VERSION ""

NS_ :

BS_:

BU_: ATCM_DMSM GSM GWM _delete SCCM OCS GENERIC TSTR RCM

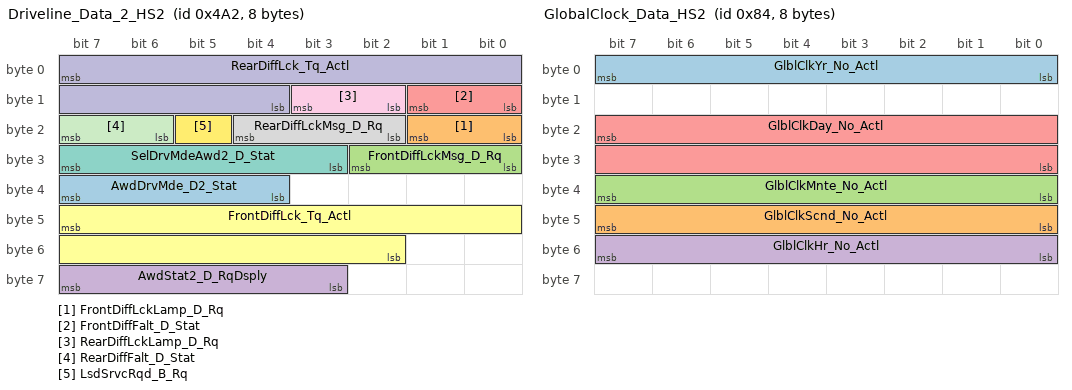
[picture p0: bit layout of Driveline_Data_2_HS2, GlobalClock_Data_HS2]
BO_ 1186 Driveline_Data_2_HS2: 8 GWM
 SG_ AwdDrvMde_D2_Stat : 39|4@0+ (1,0) [0|15] "SED" Vector__XXX
 SG_ FrontDiffLckLamp_D_Rq : 17|2@0+ (1,0) [0|3] "SED"  ATCM_DMSM
 SG_ FrontDiffLckMsg_D_Rq : 26|3@0+ (1,0) [0|7] "SED"  GENERIC
 SG_ AwdStat2_D_RqDsply : 63|5@0+ (1,0) [0|31] "SED"  GENERIC
 SG_ FrontDiffFalt_D_Stat : 9|2@0+ (1,0) [0|3] "SED"  GENERIC
 SG_ FrontDiffLck_Tq_Actl : 47|14@0+ (1,0) [0|16381] "Nm"  GENERIC
 SG_ SelDrvMdeAwd2_D_Stat : 31|5@0+ (1,0) [0|31] "SED"  GENERIC
 SG_ RearDiffLckMsg_D_Rq : 20|3@0+ (1,0) [0|7] "SED" Vector__XXX
 SG_ RearDiffLckLamp_D_Rq : 11|2@0+ (1,0) [0|3] "SED"  ATCM_DMSM
 SG_ RearDiffLck_Tq_Actl : 7|12@0+ (1,0) [0|4093] "Nm" Vector__XXX
 SG_ RearDiffFalt_D_Stat : 23|2@0+ (1,0) [0|3] "SED" Vector__XXX
 SG_ LsdSrvcRqd_B_Rq : 21|1@0+ (1,0) [0|1] "SED" Vector__XXX

BO_ 132 GlobalClock_Data_HS2: 8 GWM
 SG_ GlblClkYr_No_Actl : 7|8@0+ (1,2000) [2000|2255] "year" Vector__XXX
 SG_ GlblClkScnd_No_Actl : 47|8@0+ (1,0) [0|255] "second" Vector__XXX
 SG_ GlblClkMnte_No_Actl : 39|8@0+ (1,0) [0|255] "minute" Vector__XXX
 SG_ GlblClkHr_No_Actl : 55|8@0+ (1,0) [0|255] "hour" Vector__XXX
 SG_ GlblClkDay_No_Actl : 23|16@0+ (1,0) [0|65535] "julian day" Vector__XXX

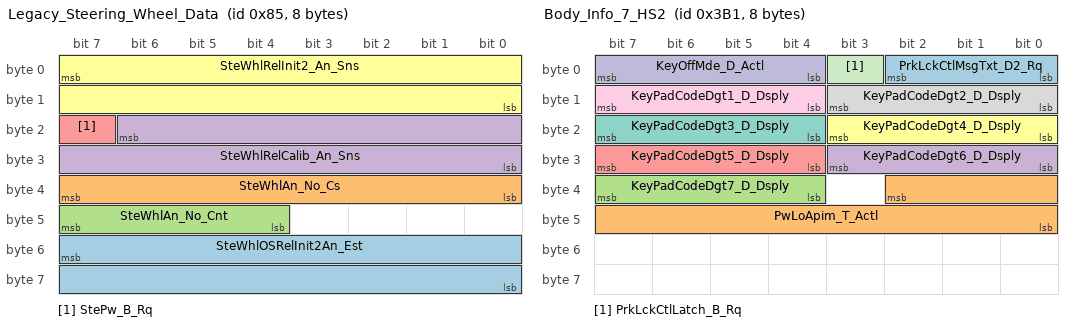
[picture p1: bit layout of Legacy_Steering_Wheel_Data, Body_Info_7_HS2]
BO_ 133 Legacy_Steering_Wheel_Data: 8 GENERIC
 SG_ SteWhlOSRelInit2An_Est : 55|16@0+ (0.1,-3200) [-3200|3353.3] "deg"  GENERIC
 SG_ SteWhlAn_No_Cs : 39|8@0+ (1,0) [0|255] "Unitless"  GENERIC
 SG_ SteWhlAn_No_Cnt : 47|4@0+ (1,0) [0|15] "Counts"  GENERIC
 SG_ SteWhlRelCalib_An_Sns : 22|15@0+ (0.1,-1600) [-1600|1676.5] "deg"  GENERIC
 SG_ StePw_B_Rq : 23|1@0+ (1,0) [0|1] "SED"  GENERIC
 SG_ SteWhlRelInit2_An_Sns : 7|16@0+ (0.1,-3200) [-3200|3353.3] "degrees"  GENERIC

BO_ 945 Body_Info_7_HS2: 8 GWM
 SG_ PrkLckCtlMsgTxt_D2_Rq : 2|3@0+ (1,0) [0|7] "SED"  GENERIC
 SG_ PwLoApim_T_Actl : 34|11@0+ (1,0) [0|2047] "minute"  GENERIC
 SG_ KeyPadCodeDgt7_D_Dsply : 39|4@0+ (1,0) [0|15] "SED"  GENERIC
 SG_ KeyPadCodeDgt6_D_Dsply : 27|4@0+ (1,0) [0|15] "SED"  GENERIC
 SG_ KeyPadCodeDgt5_D_Dsply : 31|4@0+ (1,0) [0|15] "SED"  GENERIC
 SG_ KeyPadCodeDgt4_D_Dsply : 19|4@0+ (1,0) [0|15] "SED"  GENERIC
 SG_ KeyPadCodeDgt3_D_Dsply : 23|4@0+ (1,0) [0|15] "SED"  GENERIC
 SG_ KeyPadCodeDgt2_D_Dsply : 11|4@0+ (1,0) [0|15] "SED"  GENERIC
 SG_ KeyPadCodeDgt1_D_Dsply : 15|4@0+ (1,0) [0|15] "SED"  GENERIC
 SG_ KeyOffMde_D_Actl : 7|4@0+ (1,0) [0|15] "SED" Vector__XXX
 SG_ PrkLckCtlLatch_B_Rq : 3|1@0+ (1,0) [0|1] "SED"  GENERIC

BO_ 1080 GatewayData3_HS2: 8 GWM
 SG_ TrlrAidMde_D_Rq_UB : 56|1@0+ (1,0) [0|1] "SED" Vector__XXX
 SG_ TrlrAidMde_D_Rq : 58|2@0+ (1,0) [0|3] "SED" Vector__XXX
 SG_ Rba_D_Rq_UB : 59|1@0+ (1,0) [0|1] "SED" Vector__XXX
 SG_ Rba_D_Rq : 61|2@0+ (1,0) [0|3] "SED" Vector__XXX
 SG_ TrailCtlSwtch_B_Stat_UB : 62|1@0+ (1,0) [0|1] "SED" Vector__XXX
 SG_ TrailCtlSwtch_B_Stat : 63|1@0+ (1,0) [0|1] "SED" Vector__XXX
 SG_ TrailCtlPt_B_Falt_UB : 0|1@0+ (1,0) [0|1] "SED" Vector__XXX
 SG_ TrailCtlPt_B_Falt : 49|2@0+ (1,0) [0|3] "SED" Vector__XXX
 SG_ AutoTowActv_B_Stat_UB : 50|1@0+ (1,0) [0|1] "SED" Vector__XXX
 SG_ AutoTowActv_B_Stat : 51|1@0+ (1,0) [0|1] "SED" Vector__XXX
 SG_ DrLatchLckRr_B_Stat_UB : 44|1@0+ (1,0) [0|1] "SED" Vector__XXX
 SG_ DrLatchLckRl_B_Stat_UB : 46|1@0+ (1,0) [0|1] "SED" Vector__XXX
 SG_ DrLatchLckFr_B_Stat_UB : 32|1@0+ (1,0) [0|1] "SED"  GSM
 SG_ DrLatchLckFl_B_Stat_UB : 34|1@0+ (1,0) [0|1] "SED"  GSM
 SG_ DrLatchRr_B_Falt_UB : 40|1@0+ (1,0) [0|1] "SED" Vector__XXX
 SG_ DrLatchRl_B_Falt_UB : 42|1@0+ (1,0) [0|1] "SED" Vector__XXX
 SG_ DrLatchFr_B_Falt_UB : 36|1@0+ (1,0) [0|1] "SED"  GSM
 SG_ DrLatchFl_B_Falt_UB : 38|1@0+ (1,0) [0|1] "SED"  GSM
 SG_ DrLatchCntRr_No_Actl_UB : 24|1@0+ (1,0) [0|1] "SED" Vector__XXX
 SG_ DrLatchCntRl_No_Actl_UB : 25|1@0+ (1,0) [0|1] "SED" Vector__XXX
 SG_ DrLatchCntFr_No_Actl_UB : 26|1@0+ (1,0) [0|1] "SED"  GSM
 SG_ DrLatchCntFl_No_Actl_UB : 27|1@0+ (1,0) [0|1] "SED"  GSM
 SG_ DrLatchRr_B_Falt : 41|1@0+ (1,0) [0|1] "SED" Vector__XXX
 SG_ DrLatchRl_B_Falt : 43|1@0+ (1,0) [0|1] "SED" Vector__XXX
 SG_ DrLatchLckRr_B_Stat : 45|1@0+ (1,0) [0|1] "SED" Vector__XXX
 SG_ DrLatchLckRl_B_Stat : 47|1@0+ (1,0) [0|1] "SED" Vector__XXX
 SG_ DrLatchLckFr_B_Stat : 33|1@0+ (1,0) [0|1] "SED"  GSM
 SG_ DrLatchLckFl_B_Stat : 35|1@0+ (1,0) [0|1] "SED"  GSM
 SG_ DrLatchFr_B_Falt : 37|1@0+ (1,0) [0|1] "SED"  GSM
 SG_ DrLatchFl_B_Falt : 39|1@0+ (1,0) [0|1] "SED"  GSM
 SG_ DrLatchCntRr_No_Actl : 31|4@0+ (1,0) [0|15] "unitless" Vector__XXX
 SG_ DrLatchCntRl_No_Actl : 19|4@0+ (1,0) [0|15] "unitless" Vector__XXX
 SG_ DrLatchCntFr_No_Actl : 23|4@0+ (1,0) [0|15] "unitless"  GSM
 SG_ DrLatchCntFl_No_Actl : 55|4@0+ (1,0) [0|15] "unitless"  GSM
 SG_ TurnLghtSwtch_D_Stat2_UB : 1|1@0+ (1,0) [0|1] "SED" Vector__XXX
 SG_ TurnLghtSwtch_D_Stat2 : 3|2@0+ (1,0) [0|3] "SED" Vector__XXX
 SG_ CabnAmb_Te_Actl_UB : 4|1@0+ (1,0) [0|1] "SED"  SCCM
 SG_ CabnAmb_Te_Actl : 15|8@0+ (0.5,-57) [-57|70] "degreesC"  SCCM
 SG_ HeadLghtHiPrmsn_D_Stat_UB : 5|1@0+ (1,0) [0|1] "SED"  SCCM
 SG_ HeadLghtHiPrmsn_D_Stat : 7|2@0+ (1,0) [0|3] "SED"  SCCM

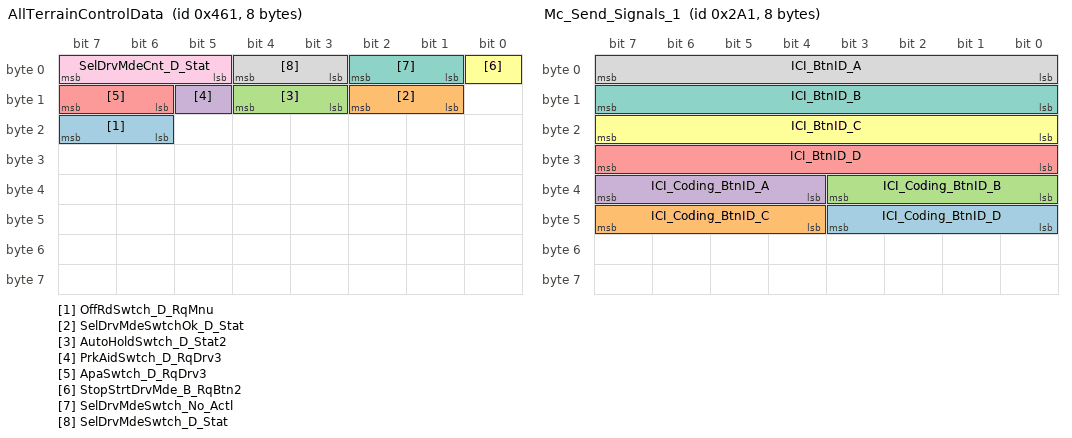
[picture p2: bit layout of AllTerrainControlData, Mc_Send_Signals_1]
BO_ 1121 AllTerrainControlData: 8 ATCM_DMSM
 SG_ OffRdSwtch_D_RqMnu : 23|2@0+ (1,0) [0|3] "SED"  GWM
 SG_ SelDrvMdeSwtchOk_D_Stat : 10|2@0+ (1,0) [0|3] "SED"  GWM
 SG_ AutoHoldSwtch_D_Stat2 : 12|2@0+ (1,0) [0|3] "SED"  GWM
 SG_ PrkAidSwtch_D_RqDrv3 : 13|1@0+ (1,0) [0|1] "SED"  GWM
 SG_ ApaSwtch_D_RqDrv3 : 15|2@0+ (1,0) [0|3] "SED"  GWM
 SG_ StopStrtDrvMde_B_RqBtn2 : 0|1@0+ (1,0) [0|1] "SED"  GWM
 SG_ SelDrvMdeSwtch_No_Actl : 2|2@0+ (1,0) [0|3] "unitless"  GWM
 SG_ SelDrvMdeSwtch_D_Stat : 4|2@0+ (1,0) [0|3] "SED"  GWM
 SG_ SelDrvMdeCnt_D_Stat : 7|3@0+ (1,0) [0|7] "Counts"  GWM

BO_ 673 Mc_Send_Signals_1: 8 SCCM
 SG_ ICI_Coding_BtnID_D : 43|4@0+ (1,0) [0|15] "SED"  GWM
 SG_ ICI_Coding_BtnID_C : 47|4@0+ (1,0) [0|15] "SED"  GWM
 SG_ ICI_Coding_BtnID_B : 35|4@0+ (1,0) [0|15] "SED"  GWM
 SG_ ICI_Coding_BtnID_A : 39|4@0+ (1,0) [0|15] "SED"  GWM
 SG_ ICI_BtnID_D : 31|8@0+ (1,0) [0|255] "unitless"  GWM
 SG_ ICI_BtnID_C : 23|8@0+ (1,0) [0|255] "unitless"  GWM
 SG_ ICI_BtnID_B : 15|8@0+ (1,0) [0|255] "unitless"  GWM
 SG_ ICI_BtnID_A : 7|8@0+ (1,0) [0|255] "unitless"  GWM

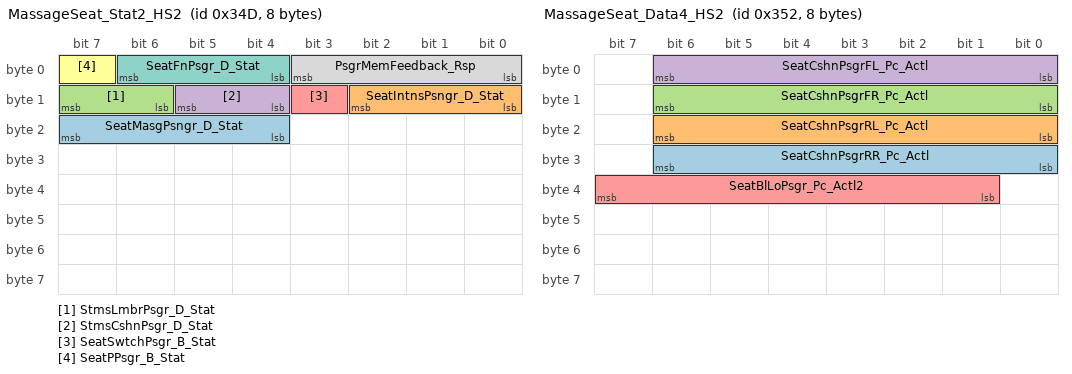
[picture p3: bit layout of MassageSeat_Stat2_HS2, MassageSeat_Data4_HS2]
BO_ 845 MassageSeat_Stat2_HS2: 8 GWM
 SG_ SeatMasgPsngr_D_Stat : 23|4@0+ (1,0) [0|15] "SED"  GENERIC
 SG_ SeatIntnsPsngr_D_Stat : 10|3@0+ (1,0) [0|7] "SED"  GENERIC
 SG_ StmsLmbrPsgr_D_Stat : 15|2@0+ (1,0) [0|3] "SED"  OCS
 SG_ StmsCshnPsgr_D_Stat : 13|2@0+ (1,0) [0|3] "SED"  OCS
 SG_ SeatSwtchPsgr_B_Stat : 11|1@0+ (1,0) [0|1] "SED"  OCS
 SG_ SeatPPsgr_B_Stat : 7|1@0+ (1,0) [0|1] "SED"  OCS
 SG_ SeatFnPsgr_D_Stat : 6|3@0+ (1,0) [0|7] "SED"  OCS
 SG_ PsgrMemFeedback_Rsp : 3|4@0+ (1,0) [0|15] "SED"  GENERIC

BO_ 850 MassageSeat_Data4_HS2: 8 GWM
 SG_ SeatCshnPsgrRR_Pc_Actl : 30|7@0+ (1,0) [0|126] "Percent"  OCS
 SG_ SeatCshnPsgrRL_Pc_Actl : 22|7@0+ (1,0) [0|126] "Percent"  OCS
 SG_ SeatCshnPsgrFR_Pc_Actl : 14|7@0+ (1,0) [0|126] "Percent"  OCS
 SG_ SeatCshnPsgrFL_Pc_Actl : 6|7@0+ (1,0) [0|126] "Percent"  OCS
 SG_ SeatBlLoPsgr_Pc_Actl2 : 39|7@0+ (1,0) [0|126] "Percent"  OCS

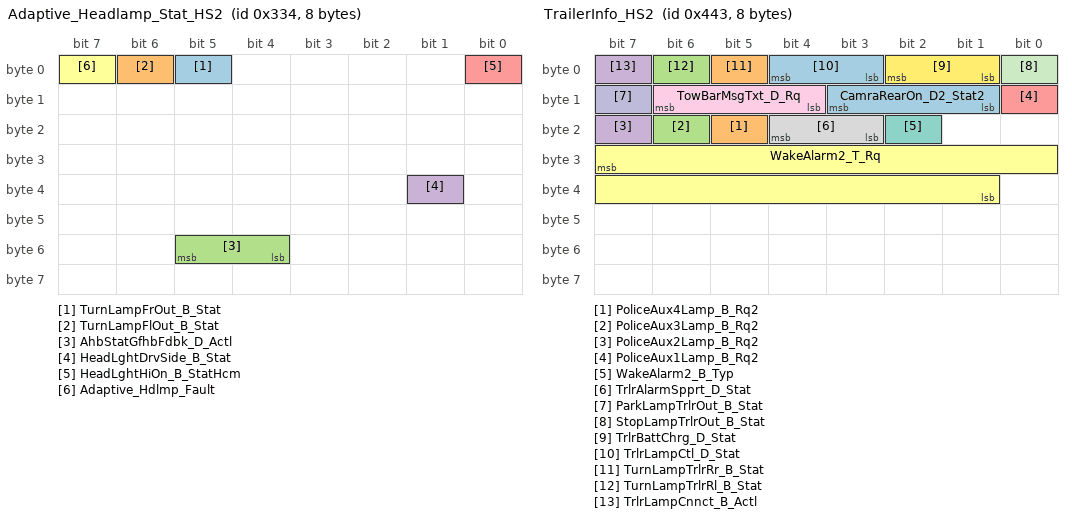
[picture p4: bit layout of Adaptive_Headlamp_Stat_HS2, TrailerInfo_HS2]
BO_ 820 Adaptive_Headlamp_Stat_HS2: 8 GWM
 SG_ TurnLampFrOut_B_Stat : 5|1@0+ (1,0) [0|1] "SED" Vector__XXX
 SG_ TurnLampFlOut_B_Stat : 6|1@0+ (1,0) [0|1] "SED" Vector__XXX
 SG_ AhbStatGfhbFdbk_D_Actl : 53|2@0+ (1,0) [0|3] "SED"  SCCM
 SG_ HeadLghtDrvSide_B_Stat : 33|1@0+ (1,0) [0|1] "SED" Vector__XXX
 SG_ HeadLghtHiOn_B_StatHcm : 0|1@0+ (1,0) [0|1] "SED"  GENERIC
 SG_ Adaptive_Hdlmp_Fault : 7|1@0+ (1,0) [0|1] "SED"  GENERIC

BO_ 935 Side_Detect_R_Stat_HS2: 8 GWM
 SG_ SodInnrRight_D_Stat : 20|2@0+ (1,0) [0|3] "SED"  GENERIC
 SG_ RbaCtaRight_D_Stat : 55|3@0+ (1,0) [0|7] "SED" Vector__XXX
 SG_ LcwaRight_D_Stat : 52|3@0+ (1,0) [0|7] "SED" Vector__XXX
 SG_ LcwaDetctRight2_B_Stat : 40|1@0+ (1,0) [0|1] "SED" Vector__XXX
 SG_ LcwaDetctRight1_B_Stat : 41|1@0+ (1,0) [0|1] "SED" Vector__XXX
 SG_ CtaInnrRight_D_Stat : 27|2@0+ (1,0) [0|3] "SED"  GENERIC
 SG_ CtaAlrtRight2_D_Stat : 30|3@0+ (1,0) [0|7] "SED"  GENERIC
 SG_ BttRight_D_Stat : 45|3@0+ (1,0) [0|7] "SED"  GENERIC
 SG_ BttRight_D_RqDrv : 47|2@0+ (1,0) [0|3] "SED"  GENERIC
 SG_ CtaBrkRightMsgTxt_B_Rq : 42|1@0+ (1,0) [0|1] "SED"  GENERIC
 SG_ CtaRightBrkEnbl_B_Rq : 31|1@0+ (1,0) [0|1] "SED" Vector__XXX
 SG_ Side_Detect_R_Illum : 39|8@0+ (1,0) [0|255] "Percent"  GENERIC
 SG_ CtaSnsRight_D_Stat : 25|2@0+ (1,0) [0|3] "SED"  GENERIC
 SG_ CtaAlrtRight_D_Stat : 8|1@0+ (1,0) [0|1] "SED"  GENERIC
 SG_ CtaRight_D_Stat : 18|3@0+ (1,0) [0|7] "SED" Vector__XXX
 SG_ SodRight_D_Stat : 15|3@0+ (1,0) [0|7] "SED"  GENERIC
 SG_ SodSnsRight_D_Stat : 12|2@0+ (1,0) [0|3] "SED" Vector__XXX
 SG_ SodAlrtRight_D_Stat : 10|2@0+ (1,0) [0|3] "SED"  GENERIC
 SG_ SodDetctRight_D_Stat : 23|3@0+ (1,0) [0|7] "SED" Vector__XXX
 SG_ SodWarnRight_Prd_Rq : 6|7@0+ (1,0) [0|127] "millisecond"  GENERIC
 SG_ CtaRightBrkDecel_B_Rq : 7|1@0+ (1,0) [0|1] "SED" Vector__XXX

BO_ 934 Side_Detect_L_Stat_HS2: 8 GWM
 SG_ SodInnrLeft_D_Stat : 20|2@0+ (1,0) [0|3] "SED"  GENERIC
 SG_ RbaCtaLeft_D_Stat : 55|3@0+ (1,0) [0|7] "SED" Vector__XXX
 SG_ LcwaLeft_D_Stat : 52|3@0+ (1,0) [0|7] "SED" Vector__XXX
 SG_ LcwaDetctLeft2_B_Stat : 40|1@0+ (1,0) [0|1] "SED" Vector__XXX
 SG_ LcwaDetctLeft1_B_Stat : 41|1@0+ (1,0) [0|1] "SED" Vector__XXX
 SG_ CtaInnrLeft_D_Stat : 27|2@0+ (1,0) [0|3] "SED"  GENERIC
 SG_ CtaAlrtLeft2_D_Stat : 30|3@0+ (1,0) [0|7] "SED"  GENERIC
 SG_ BttLeft_D_Stat : 45|3@0+ (1,0) [0|7] "SED"  GENERIC
 SG_ BttLeft_D_RqDrv : 47|2@0+ (1,0) [0|3] "SED"  GENERIC
 SG_ CtaBrkLeftMsgTxt_B_Rq : 42|1@0+ (1,0) [0|1] "SED"  GENERIC
 SG_ CtaLeftBrkDecel_B_Rq : 7|1@0+ (1,0) [0|1] "SED" Vector__XXX
 SG_ CtaLeftBrkEnbl_B_Rq : 31|1@0+ (1,0) [0|1] "SED" Vector__XXX
 SG_ Side_Detect_L_Illum : 39|8@0+ (1,0) [0|255] "Percent"  GENERIC
 SG_ CtaSnsLeft_D_Stat : 25|2@0+ (1,0) [0|3] "SED"  GENERIC
 SG_ SodDetctLeft_D_Stat : 23|3@0+ (1,0) [0|7] "SED" Vector__XXX
 SG_ CtaLeft_D_Stat : 18|3@0+ (1,0) [0|7] "SED" Vector__XXX
 SG_ CtaAlrtLeft_D_Stat : 8|1@0+ (1,0) [0|1] "SED"  GENERIC
 SG_ SodLeft_D_Stat : 15|3@0+ (1,0) [0|7] "SED"  GENERIC
 SG_ SodSnsLeft_D_Stat : 12|2@0+ (1,0) [0|3] "SED" Vector__XXX
 SG_ SodAlrtLeft_D_Stat : 10|2@0+ (1,0) [0|3] "SED"  GENERIC
 SG_ SodWarnLeft_Prd_Rq : 6|7@0+ (1,0) [0|127] "millisecond"  GENERIC

BO_ 1073 BodyEngGateway_2_HS2: 8 GWM
 SG_ CamraFrntBttn_D_Stat : 48|1@0+ (1,0) [0|1] "SED" Vector__XXX
 SG_ CamraFrntBttn_D_Stat_UB : 60|1@0+ (1,0) [0|1] "SED" Vector__XXX
 SG_ BrkDrvMde_D_Rq_UB : 49|1@0+ (1,0) [0|1] "SED" Vector__XXX
 SG_ BrkDrvMde_D_Rq : 63|3@0+ (1,0) [0|7] "SED" Vector__XXX
 SG_ SteEffort_D_Rq : 52|3@0+ (1,0) [0|7] "SED" Vector__XXX
 SG_ SteEffort_D_Rq_UB : 40|1@0+ (1,0) [0|1] "SED" Vector__XXX
 SG_ AutoHoldSwtch_D_Stat_UB : 57|1@0+ (1,0) [0|1] "SED" Vector__XXX
 SG_ AutoHoldSwtch_D_Stat : 59|2@0+ (1,0) [0|3] "SED" Vector__XXX
 SG_ HMI_HMIMode_St_UB : 41|1@0+ (1,0) [0|1] "SED"  SCCM
 SG_ HMI_HMIMode_St : 55|3@0+ (1,0) [0|7] "SED"  SCCM
 SG_ Veh_Lock_Requestor_UB : 47|1@0+ (1,0) [0|1] "SED"  GSM
 SG_ Veh_Lock_EvNum_UB : 32|1@0+ (1,0) [0|1] "SED"  GSM
 SG_ Veh_Lock_Sub_Id_UB : 33|1@0+ (1,0) [0|1] "SED" Vector__XXX
 SG_ Tire_Press_System_Stat_UB : 34|1@0+ (1,0) [0|1] "SED" Vector__XXX
 SG_ Veh_Lock_Status_UB : 8|1@0+ (1,0) [0|1] "SED"  GSM
 SG_ Veh_Lock_Sub_Id : 19|4@0+ (1,0) [0|15] "SED" Vector__XXX
 SG_ Veh_Lock_Status : 10|2@0+ (1,0) [0|3] "SED"  GSM
 SG_ Veh_Lock_Requestor : 39|5@0+ (1,0) [0|31] "SED"  GSM
 SG_ Veh_Lock_EvNum : 31|8@0+ (1,0) [0|255] "unitless"  GSM
 SG_ Tire_Press_System_Stat : 23|4@0+ (1,0) [0|15] "SED" Vector__XXX
 SG_ DISPLAY_SPEED_OFFSET_UB : 0|1@0+ (1,0) [0|1] "SED" Vector__XXX
 SG_ DISPLAY_SPEED_OFFSET : 3|3@0+ (0.5,0) [0|3.5] "kph" Vector__XXX
 SG_ DISPLAY_SPEED_SCALING_UB : 11|1@0+ (1,0) [0|1] "SED" Vector__XXX
 SG_ DISPLAY_SPEED_SCALING : 15|4@0+ (0.5,100) [100|107.5] "%" Vector__XXX
 SG_ Foh_D_Stat : 7|3@0+ (1,0) [0|7] "SED"  SCCM
 SG_ Foh_D_Stat_UB : 4|1@0+ (1,0) [0|1] "SED"  SCCM
 SG_ SteWhlHeat_D_Rq_UB : 42|1@0+ (1,0) [0|1] "SED"  SCCM
 SG_ SteWhlHeat_D_Rq : 46|4@0+ (1,0) [0|15] "SED"  SCCM

BO_ 1091 TrailerInfo_HS2: 8 GWM
 SG_ CamraRearOn_D2_Stat2 : 11|3@0+ (1,0) [0|7] "SED"  GENERIC
 SG_ PoliceAux4Lamp_B_Rq2 : 21|1@0+ (1,0) [0|1] "SED"  GENERIC
 SG_ PoliceAux3Lamp_B_Rq2 : 22|1@0+ (1,0) [0|1] "SED"  GENERIC
 SG_ PoliceAux2Lamp_B_Rq2 : 23|1@0+ (1,0) [0|1] "SED"  GENERIC
 SG_ PoliceAux1Lamp_B_Rq2 : 8|1@0+ (1,0) [0|1] "SED"  GENERIC
 SG_ WakeAlarm2_T_Rq : 31|15@0+ (1,0) [0|32767] "minute"  GENERIC
 SG_ WakeAlarm2_B_Typ : 18|1@0+ (1,0) [0|1] "SED"  GENERIC
 SG_ TrlrAlarmSpprt_D_Stat : 20|2@0+ (1,0) [0|3] "SED"  GENERIC
 SG_ TowBarMsgTxt_D_Rq : 14|3@0+ (1,0) [0|7] "SED"  GENERIC
 SG_ ParkLampTrlrOut_B_Stat : 15|1@0+ (1,0) [0|1] "SED"  GENERIC
 SG_ StopLampTrlrOut_B_Stat : 0|1@0+ (1,0) [0|1] "SED"  GENERIC
 SG_ TrlrBattChrg_D_Stat : 2|2@0+ (1,0) [0|3] "SED"  GENERIC
 SG_ TrlrLampCtl_D_Stat : 4|2@0+ (1,0) [0|3] "SED"  GENERIC
 SG_ TurnLampTrlrRr_B_Stat : 5|1@0+ (1,0) [0|1] "SED"  GENERIC
 SG_ TurnLampTrlrRl_B_Stat : 6|1@0+ (1,0) [0|1] "SED"  GENERIC
 SG_ TrlrLampCnnct_B_Actl : 7|1@0+ (1,0) [0|1] "SED" Vector__XXX

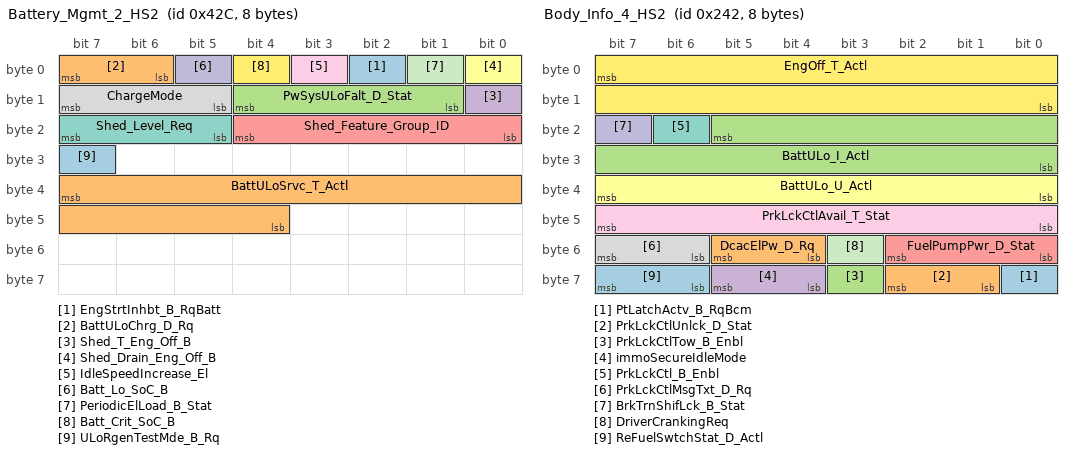
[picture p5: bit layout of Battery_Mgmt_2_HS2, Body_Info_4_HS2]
BO_ 1068 Battery_Mgmt_2_HS2: 8 GWM
 SG_ EngStrtInhbt_B_RqBatt : 2|1@0+ (1,0) [0|1] "SED"  GENERIC
 SG_ BattULoChrg_D_Rq : 7|2@0+ (1,0) [0|3] "SED"  GENERIC
 SG_ PwSysULoFalt_D_Stat : 12|4@0+ (1,0) [0|15] "SED" Vector__XXX
 SG_ Shed_T_Eng_Off_B : 8|1@0+ (1,0) [0|1] "SED" Vector__XXX
 SG_ Shed_Feature_Group_ID : 20|5@0+ (1,0) [0|31] "SED" Vector__XXX
 SG_ Shed_Drain_Eng_Off_B : 0|1@0+ (1,0) [0|1] "SED" Vector__XXX
 SG_ Shed_Level_Req : 23|3@0+ (1,0) [0|7] "SED"  GSM,SCCM
 SG_ ChargeMode : 15|3@0+ (1,0) [0|7] "SED"  GENERIC
 SG_ IdleSpeedIncrease_El : 3|1@0+ (1,0) [0|1] "SED"  GENERIC
 SG_ Batt_Lo_SoC_B : 5|1@0+ (1,0) [0|1] "SED"  GENERIC
 SG_ PeriodicElLoad_B_Stat : 1|1@0+ (1,0) [0|1] "SED"  GENERIC
 SG_ Batt_Crit_SoC_B : 4|1@0+ (1,0) [0|1] "SED"  GSM
 SG_ ULoRgenTestMde_B_Rq : 31|1@0+ (1,0) [0|1] "SED"  GENERIC
 SG_ BattULoSrvc_T_Actl : 39|12@0+ (1,0) [0|4095] "days"  GENERIC

BO_ 611 Driveline_Data_1_HS2: 8 GWM
 SG_ AwdTerrMdeChng_D_Rdy : 58|3@0+ (1,0) [0|7] "SED" Vector__XXX
 SG_ AwdTerrMde_D_Actl : 50|3@0+ (1,0) [0|7] "SED" Vector__XXX
 SG_ AwdSys_D_Stat : 27|2@0+ (1,0) [0|3] "SED"  GENERIC
 SG_ SelDrvMdeAwd_D_Stat : 33|2@0+ (1,0) [0|3] "SED"  GENERIC
 SG_ AwdStat_D_RqDsply : 63|5@0+ (1,0) [0|31] "SED"  GSM
 SG_ AwdLck_D_Stat : 31|4@0+ (1,0) [0|15] "SED"  GENERIC
 SG_ AwdSrvcRqd_B_Rq : 0|1@0+ (1,0) [0|1] "SED"  RCM
 SG_ AwdDrvMde_D_Stat : 38|3@0+ (1,0) [0|7] "SED"  GENERIC
 SG_ NtrlTowAvail_B_Stat : 4|1@0+ (1,0) [0|1] "SED"  GENERIC
 SG_ AwdLck_Tq_Rq : 15|12@0+ (1,0) [0|4093] "Nm"  GENERIC
 SG_ TrnAout_Tq_RqMx : 47|13@0+ (1,-1250) [-1250|6941] "Nm"  GENERIC
 SG_ AwdOffRoadMode_D_Stats : 25|2@0+ (1,0) [0|3] "SED" Vector__XXX
 SG_ AwdLoLamp_D_RqDsply : 35|2@0+ (1,0) [0|3] "SED"  ATCM_DMSM
 SG_ AwdHiLamp_D_RqDsply : 19|2@0+ (1,0) [0|3] "SED"  ATCM_DMSM
 SG_ AwdAutoLamp_D_RqDsply : 17|2@0+ (1,0) [0|3] "SED"  ATCM_DMSM
 SG_ Awd2wdLamp_D_RqDsply : 2|2@0+ (1,0) [0|3] "SED"  ATCM_DMSM
 SG_ AwdRnge_D_Actl : 7|3@0+ (1,0) [0|7] "SED" Vector__XXX

BO_ 395 HeadUpDisplayReq_HS2: 8 GWM
 SG_ SelDrvMdeCnfm_D_Stat : 35|2@0+ (1,0) [0|3] "SED"  GENERIC
 SG_ HudShifPoint_N_Rq : 29|6@0+ (100,2000) [2000|8300] "rpm" Vector__XXX
 SG_ HudMde_D_Rq : 38|3@0+ (1,0) [0|7] "SED" Vector__XXX
 SG_ HudLedMde_D_Rq : 31|2@0+ (1,0) [0|3] "SED" Vector__XXX
 SG_ HudLedIntns_Pc_Rq : 22|7@0+ (1,0) [0|127] "percent" Vector__XXX
 SG_ HudLed9On_B_Rq : 15|1@0+ (1,0) [0|1] "SED" Vector__XXX
 SG_ HudLed8On_B_Rq : 0|1@0+ (1,0) [0|1] "SED" Vector__XXX
 SG_ HudLed7On_B_Rq : 1|1@0+ (1,0) [0|1] "SED" Vector__XXX
 SG_ HudLed6On_B_Rq : 2|1@0+ (1,0) [0|1] "SED" Vector__XXX
 SG_ HudLed5On_B_Rq : 3|1@0+ (1,0) [0|1] "SED" Vector__XXX
 SG_ HudLed4On_B_Rq : 4|1@0+ (1,0) [0|1] "SED" Vector__XXX
 SG_ HudLed3On_B_Rq : 5|1@0+ (1,0) [0|1] "SED" Vector__XXX
 SG_ HudLed2On_B_Rq : 6|1@0+ (1,0) [0|1] "SED" Vector__XXX
 SG_ HudLed1On_B_Rq : 7|1@0+ (1,0) [0|1] "SED" Vector__XXX
 SG_ HudLed18On_B_Rq : 39|1@0+ (1,0) [0|1] "SED" Vector__XXX
 SG_ HudLed17On_B_Rq : 23|1@0+ (1,0) [0|1] "SED" Vector__XXX
 SG_ HudLed16On_B_Rq : 8|1@0+ (1,0) [0|1] "SED" Vector__XXX
 SG_ HudLed15On_B_Rq : 9|1@0+ (1,0) [0|1] "SED" Vector__XXX
 SG_ HudLed14On_B_Rq : 10|1@0+ (1,0) [0|1] "SED" Vector__XXX
 SG_ HudLed13On_B_Rq : 11|1@0+ (1,0) [0|1] "SED" Vector__XXX
 SG_ HudLed12On_B_Rq : 12|1@0+ (1,0) [0|1] "SED" Vector__XXX
 SG_ HudLed11On_B_Rq : 13|1@0+ (1,0) [0|1] "SED" Vector__XXX
 SG_ HudLed10On_B_Rq : 14|1@0+ (1,0) [0|1] "SED" Vector__XXX

BO_ 578 Body_Info_4_HS2: 8 GWM
 SG_ PtLatchActv_B_RqBcm : 56|1@0+ (1,0) [0|1] "SED"  GENERIC
 SG_ PrkLckCtlUnlck_D_Stat : 58|2@0+ (1,0) [0|3] "SED"  GENERIC
 SG_ PrkLckCtlTow_B_Enbl : 59|1@0+ (1,0) [0|1] "SED"  GENERIC
 SG_ immoSecureIdleMode : 61|2@0+ (1,0) [0|3] "SED"  GSM
 SG_ FuelPumpPwr_D_Stat : 50|3@0+ (1,0) [0|7] "SED"  GENERIC
 SG_ BattULo_U_Actl : 39|8@0+ (0.0625,0) [0|15.875] "volt" Vector__XXX
 SG_ PrkLckCtl_B_Enbl : 22|1@0+ (1,0) [0|1] "SED"  GSM
 SG_ PrkLckCtlMsgTxt_D_Rq : 55|2@0+ (1,0) [0|3] "SED"  GENERIC
 SG_ PrkLckCtlAvail_T_Stat : 47|8@0+ (1,0) [0|255] "second"  GENERIC
 SG_ BrkTrnShifLck_B_Stat : 23|1@0+ (1,0) [0|1] "SED"  GSM
 SG_ DriverCrankingReq : 51|1@0+ (1,0) [0|1] "SED"  GSM
 SG_ EngOff_T_Actl : 7|16@0+ (1,0) [0|65534] "second^0.5" Vector__XXX
 SG_ ReFuelSwtchStat_D_Actl : 63|2@0+ (1,0) [0|3] "SED"  GENERIC
 SG_ DcacElPw_D_Rq : 53|2@0+ (1,0) [0|3] "SED"  GENERIC
 SG_ BattULo_I_Actl : 21|14@0+ (0.0625,-512) [-512|511.875] "ampere"  GENERIC

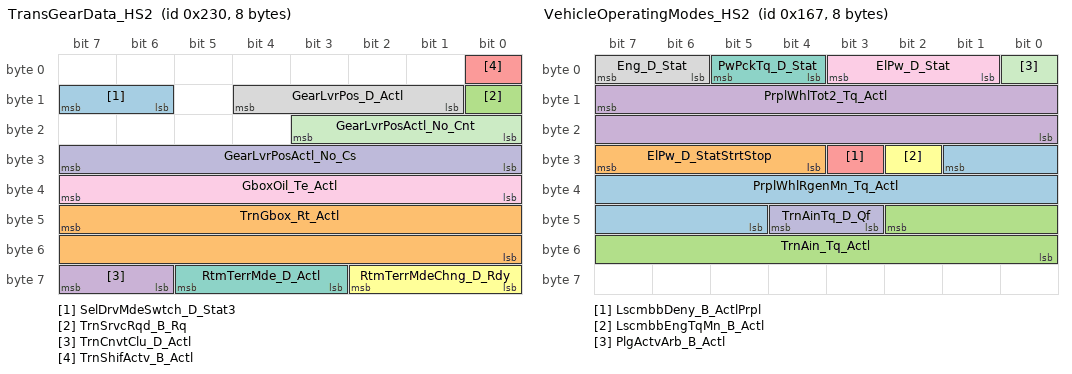
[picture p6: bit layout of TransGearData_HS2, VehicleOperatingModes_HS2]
BO_ 560 TransGearData_HS2: 8 GWM
 SG_ SelDrvMdeSwtch_D_Stat3 : 15|2@0+ (1,0) [0|3] "SED" Vector__XXX
 SG_ TrnGbox_Rt_Actl : 47|16@0+ (0.001,0) [0|65.533] "Unitless" Vector__XXX
 SG_ TrnSrvcRqd_B_Rq : 8|1@0+ (1,0) [0|1] "SED"  RCM
 SG_ TrnCnvtClu_D_Actl : 63|2@0+ (1,0) [0|3] "SED" Vector__XXX
 SG_ TrnShifActv_B_Actl : 0|1@0+ (1,0) [0|1] "SED" Vector__XXX
 SG_ RtmTerrMdeChng_D_Rdy : 58|3@0+ (1,0) [0|7] "SED" Vector__XXX
 SG_ RtmTerrMde_D_Actl : 61|3@0+ (1,0) [0|7] "SED" Vector__XXX
 SG_ GearLvrPos_D_Actl : 12|4@0+ (1,0) [0|15] "SED"  SCCM,RCM,GSM
 SG_ GboxOil_Te_Actl : 39|8@0+ (1,-60) [-60|193] "degC"  GENERIC
 SG_ GearLvrPosActl_No_Cs : 31|8@0+ (1,0) [0|255] "Unitless"  GENERIC
 SG_ GearLvrPosActl_No_Cnt : 19|4@0+ (1,0) [0|15] "Unitless"  GENERIC

BO_ 359 VehicleOperatingModes_HS2: 8 GWM
 SG_ PrplWhlRgenMn_Tq_Actl : 25|13@0+ (4,-16380) [-16380|16380] "Nm" Vector__XXX
 SG_ ElPw_D_StatStrtStop : 31|4@0+ (1,0) [0|15] "SED"  GSM,SCCM
 SG_ TrnAin_Tq_Actl : 42|11@0+ (1,-500) [-500|1547] "Nm" Vector__XXX
 SG_ PrplWhlTot2_Tq_Actl : 15|16@0+ (4,-131072) [-131072|131060] "Nm"  RCM
 SG_ LscmbbDeny_B_ActlPrpl : 27|1@0+ (1,0) [0|1] "SED" Vector__XXX
 SG_ LscmbbEngTqMn_B_Actl : 26|1@0+ (1,0) [0|1] "SED" Vector__XXX
 SG_ PwPckTq_D_Stat : 5|2@0+ (1,0) [0|3] "SED"  SCCM,OCS,GSM
 SG_ Eng_D_Stat : 7|2@0+ (1,0) [0|3] "SED" Vector__XXX
 SG_ ElPw_D_Stat : 3|3@0+ (1,0) [0|7] "SED"  GSM,OCS,SCCM
 SG_ TrnAinTq_D_Qf : 44|2@0+ (1,0) [0|3] "SED" Vector__XXX
 SG_ PlgActvArb_B_Actl : 0|1@0+ (1,0) [0|1] "SED"  GENERIC

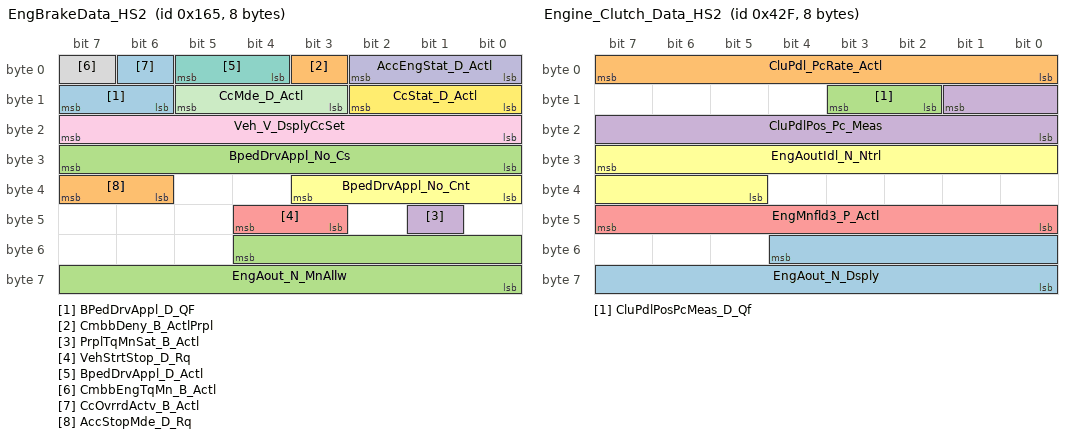
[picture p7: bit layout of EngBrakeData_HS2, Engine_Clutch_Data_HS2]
BO_ 357 EngBrakeData_HS2: 8 GWM
 SG_ BPedDrvAppl_D_QF : 15|2@0+ (1,0) [0|3] "SED"  OCS,GSM,RCM
 SG_ CmbbDeny_B_ActlPrpl : 3|1@0+ (1,0) [0|1] "SED" Vector__XXX
 SG_ BpedDrvAppl_No_Cs : 31|8@0+ (1,0) [0|255] "Unitless"  GENERIC
 SG_ PrplTqMnSat_B_Actl : 41|1@0+ (1,0) [0|1] "SED" Vector__XXX
 SG_ VehStrtStop_D_Rq : 44|2@0+ (1,0) [0|3] "SED"  GENERIC
 SG_ BpedDrvAppl_No_Cnt : 35|4@0+ (1,0) [0|15] "Unitless"  GENERIC
 SG_ BpedDrvAppl_D_Actl : 5|2@0+ (1,0) [0|3] "SED"  OCS,GSM,RCM
 SG_ CmbbEngTqMn_B_Actl : 7|1@0+ (1,0) [0|1] "SED"  GENERIC
 SG_ Veh_V_DsplyCcSet : 23|8@0+ (1,0) [0|253] "Unitless"  GENERIC
 SG_ AccEngStat_D_Actl : 2|3@0+ (1,0) [0|7] "SED" Vector__XXX
 SG_ CcMde_D_Actl : 13|3@0+ (1,0) [0|7] "SED" Vector__XXX
 SG_ CcStat_D_Actl : 10|3@0+ (1,0) [0|7] "SED"  OCS,RCM
 SG_ CcOvrrdActv_B_Actl : 6|1@0+ (1,0) [0|1] "SED"  RCM
 SG_ AccStopMde_D_Rq : 39|2@0+ (1,0) [0|3] "SED" Vector__XXX
 SG_ EngAout_N_MnAllw : 52|13@0+ (2,0) [0|16382] "rpm"  GENERIC

BO_ 390 ACCDATA_HS2: 8 GWM
 SG_ AccAutoResum_D_Rq : 7|2@0+ (1,0) [0|3] "SED" Vector__XXX
 SG_ AccBrkPulse_B_Rq : 36|1@0+ (1,0) [0|1] "SED" Vector__XXX
 SG_ AccBrkTot_A_Rq : 4|13@0+ (0.0039,-20) [-20|11.9449] "m/s^2" Vector__XXX
 SG_ AccPrpl_A_Pred : 17|10@0+ (0.01,-5) [-5|5.23] "m/s^2" Vector__XXX
 SG_ AccVeh_V_Trg : 32|9@0+ (0.5,0) [0|255.5] "kph" Vector__XXX
 SG_ AccBrkPrkEl_B_Rq : 38|1@0+ (1,0) [0|1] "SED" Vector__XXX
 SG_ Cmbb_B_Enbl : 50|1@0+ (1,0) [0|1] "SED"  RCM
 SG_ CmbbOvrrd_B_RqDrv : 51|1@0+ (1,0) [0|1] "SED"  RCM
 SG_ CmbbDeny_B_Actl : 37|1@0+ (1,0) [0|1] "SED"  RCM
 SG_ CmbbEngTqMn_B_Rq : 52|1@0+ (1,0) [0|1] "SED" Vector__XXX
 SG_ AccPrpl_A_Rq : 49|10@0+ (0.01,-5) [-5|5.23] "m/s^2" Vector__XXX
 SG_ AccDeny_B_Rq : 53|1@0+ (1,0) [0|1] "SED" Vector__XXX
 SG_ AccResumEnbl_B_Rq : 33|1@0+ (1,0) [0|1] "SED" Vector__XXX
 SG_ AccCancl_B_Rq : 39|1@0+ (1,0) [0|1] "SED" Vector__XXX
 SG_ AccBrkPrchg_B_Rq : 54|1@0+ (1,0) [0|1] "SED" Vector__XXX
 SG_ AccBrkDecel_B_Rq : 55|1@0+ (1,0) [0|1] "SED" Vector__XXX
 SG_ AccStopStat_B_Rq : 34|1@0+ (1,0) [0|1] "SED" Vector__XXX

BO_ 1071 Engine_Clutch_Data_HS2: 8 GWM
 SG_ EngAout_N_Dsply : 52|13@0+ (2,0) [0|16382] "rpm"  GENERIC
 SG_ CluPdl_PcRate_Actl : 7|8@0+ (0.04,-5) [-5|5.2] "%/ms" Vector__XXX
 SG_ CluPdlPosPcMeas_D_Qf : 11|2@0+ (1,0) [0|3] "SED" Vector__XXX
 SG_ CluPdlPos_Pc_Meas : 9|10@0+ (0.1,0) [0|102.3] "%" Vector__XXX
 SG_ EngMnfld3_P_Actl : 47|8@0+ (10,0) [0|2530] "milibar" Vector__XXX
 SG_ EngAoutIdl_N_Ntrl : 31|11@0+ (2,0) [0|4094] "rpm" Vector__XXX

BO_ 1072 Cluster_Info1_HS2: 8 GWM
 SG_ HdcOn_B_Rq_UB : 55|1@0+ (1,0) [0|1] "SED" Vector__XXX
 SG_ TrlrAidCancl_B_Rq_UB : 56|1@0+ (1,0) [0|1] "SED" Vector__XXX
 SG_ TrlrAidCancl_B_Rq : 57|1@0+ (1,0) [0|1] "SED" Vector__XXX
 SG_ HdcOn_B_Rq : 39|1@0+ (1,0) [0|1] "SED" Vector__XXX
 SG_ HsaMde_D_Rq : 51|2@0+ (1,0) [0|3] "SED" Vector__XXX
 SG_ HsaMde_D_Rq_UB : 49|1@0+ (1,0) [0|1] "SED" Vector__XXX
 SG_ LscmbbStat_B_Actl : 53|1@0+ (1,0) [0|1] "SED" Vector__XXX
 SG_ LscmbbStat_B_Actl_UB : 52|1@0+ (1,0) [0|1] "SED" Vector__XXX
 SG_ Outside_Air_Temp_Stat_UB : 3|1@0+ (1,0) [0|1] "SED" Vector__XXX
 SG_ Outside_Air_Temp_Stat : 47|8@0+ (0.5,-40) [-40|86.5] "Degrees C" Vector__XXX
 SG_ BulbChkActv_B_Stat_UB : 5|1@0+ (1,0) [0|1] "SED" Vector__XXX
 SG_ BulbChkActv_B_Stat : 6|1@0+ (1,0) [0|1] "SED" Vector__XXX
 SG_ Fda_B_Stat_UB : 4|1@0+ (1,0) [0|1] "SED" Vector__XXX
 SG_ AccEnbl_B_RqDrv_UB : 2|1@0+ (1,0) [0|1] "SED" Vector__XXX
 SG_ AccDeny_B_RqIpc_UB : 1|1@0+ (1,0) [0|1] "SED" Vector__XXX
 SG_ OdometerMasterValue_UB : 0|1@0+ (1,0) [0|1] "SED" Vector__XXX
 SG_ OdometerMasterValue : 15|24@0+ (1,0) [0|16777214] "km"  RCM
 SG_ Fda_B_Stat : 36|1@0+ (1,0) [0|1] "SED" Vector__XXX
 SG_ AccDeny_B_RqIpc : 7|1@0+ (1,0) [0|1] "SED" Vector__XXX
 SG_ AccEnbl_B_RqDrv : 35|1@0+ (1,0) [0|1] "SED" Vector__XXX
 SG_ DrvSlipCtlMde_D_Rq_UB : 38|1@0+ (1,0) [0|1] "SED" Vector__XXX
 SG_ DrvSlipCtlMde_D_Rq : 33|2@0+ (1,0) [0|3] "SED" Vector__XXX
 SG_ DrvSlipCtlMde_B_Rq_UB : 37|1@0+ (1,0) [0|1] "SED" Vector__XXX
 SG_ DrvSlipCtlMde_B_Rq : 34|1@0+ (1,0) [0|1] "SED" Vector__XXX
 SG_ ePRNDL_MODE_UB : 48|1@0+ (1,0) [0|1] "SED"  GSM
 SG_ ePRNDL_MODE : 54|1@0+ (1,0) [0|1] "SED"  GSM
 SG_ TrlrBrkMde_D_Rq : 63|1@0+ (1,0) [0|1] "SED" Vector__XXX
 SG_ TRLR_SWAY_CONFIG_CMD : 62|1@0+ (1,0) [0|1] "SED" Vector__XXX
 SG_ TRAILER_BRAKE_CONFIG : 61|1@0+ (1,0) [0|1] "SED" Vector__XXX
 SG_ TrlrBrkMde_D_Rq_UB : 60|1@0+ (1,0) [0|1] "SED" Vector__XXX
 SG_ TRLR_SWAY_CONFIG_CMD_UB : 59|1@0+ (1,0) [0|1] "SED" Vector__XXX
 SG_ TRAILER_BRAKE_CONFIG_UB : 58|1@0+ (1,0) [0|1] "SED" Vector__XXX

BO_ 1058 PowertrainData_HS2: 8 GWM
 SG_ TqmTerrMdeChng_D_Rdy_UB : 33|1@0+ (1,0) [0|1] "SED" Vector__XXX
 SG_ TqmTerrMde_D_Actl_UB : 32|1@0+ (1,0) [0|1] "SED" Vector__XXX
 SG_ TqmTerrMdeChng_D_Rdy : 63|3@0+ (1,0) [0|7] "SED" Vector__XXX
 SG_ TqmTerrMde_D_Actl : 60|3@0+ (1,0) [0|7] "SED" Vector__XXX
 SG_ BattTracWarnLamp_B_Rq_UB : 48|1@0+ (1,0) [0|1] "SED"  GENERIC
 SG_ BattTracWarnLamp_B_Rq : 43|1@0+ (1,0) [0|1] "SED"  RCM
 SG_ BattTracSrvcRqd_B_Rq_UB : 44|1@0+ (1,0) [0|1] "SED"  GENERIC
 SG_ BattTracSrvcRqd_B_Rq : 45|1@0+ (1,0) [0|1] "SED"  RCM
 SG_ SeatBlLoPsgr_Pc_Actl_UB : 42|1@0+ (1,0) [0|1] "SED"  OCS
 SG_ SeatBlLoPsgr_Pc_Actl : 55|7@0+ (1,0) [0|126] "Percent"  OCS
 SG_ WndwFrontHeat_B_Stat_UB : 41|1@0+ (1,0) [0|1] "SED" Vector__XXX
 SG_ WndwFrontHeat_B_Stat : 40|1@0+ (1,0) [0|1] "SED" Vector__XXX
 SG_ HILL_DESC_SW_UB : 46|1@0+ (1,0) [0|1] "SED" Vector__XXX
 SG_ HILL_DESC_SW : 47|1@0+ (1,0) [0|1] "SED" Vector__XXX
 SG_ EngClntTe_D_Qf : 36|2@0+ (1,0) [0|3] "SED" Vector__XXX
 SG_ EngClnt_Te_Actl_UB : 37|1@0+ (1,0) [0|1] "SED" Vector__XXX
 SG_ EngClnt_Te_Actl : 31|8@0+ (1,-60) [-60|195] "degC" Vector__XXX
 SG_ TrnTotTq_Rt_Est_UB : 38|1@0+ (1,0) [0|1] "SED" Vector__XXX
 SG_ TrnTotLss_Tq_Est_UB : 39|1@0+ (1,0) [0|1] "SED" Vector__XXX
 SG_ TrnTotTq_Rt_Est : 15|16@0+ (0.001,0) [0|65.533] "Unitless" Vector__XXX
 SG_ TrnTotLss_Tq_Est : 7|8@0+ (0.5,0) [0|126.5] "Nm" Vector__XXX
 SG_ DrvSlipCtlMde_B_Rq2_UB : 57|1@0+ (1,0) [0|1] "SED" Vector__XXX
 SG_ DrvSlipCtlMde_B_Rq2 : 34|1@0+ (1,0) [0|1] "SED" Vector__XXX

BO_ 1082 GatewayData_HS2: 8 GWM
 SG_ EsaOn_B_Rq_UB : 33|1@0+ (1,0) [0|1] "SED" Vector__XXX
 SG_ EsaOn_B_Rq : 34|1@0+ (1,0) [0|1] "SED" Vector__XXX
 SG_ RearDiffLck_D_RqArb_UB : 35|1@0+ (1,0) [0|1] "SED" Vector__XXX
 SG_ RearDiffLck_D_RqArb : 25|2@0+ (1,0) [0|3] "SED" Vector__XXX
 SG_ AwdMde_D_RqArb_UB : 36|1@0+ (1,0) [0|1] "SED" Vector__XXX
 SG_ AwdMde_D_RqArb : 39|3@0+ (1,0) [0|7] "SED" Vector__XXX
 SG_ SelDrvMdeTxtReset_B_Rq_UB : 43|1@0+ (1,0) [0|1] "SED" Vector__XXX
 SG_ SelDrvMdeTxtReset_B_Rq : 44|1@0+ (1,0) [0|1] "SED" Vector__XXX
 SG_ SelDrvMdeDsply_B_Avail_UB : 50|1@0+ (1,0) [0|1] "SED" Vector__XXX
 SG_ AirSusp_D_RqDrv_UB : 16|1@0+ (1,0) [0|1] "SED" Vector__XXX
 SG_ DrvInputRequired_B_Rq_UB : 52|1@0+ (1,0) [0|1] "SED"  SCCM
 SG_ DrvInputRequired_B_Rq : 32|1@0+ (1,0) [0|1] "SED"  SCCM
 SG_ SelDrvMdeSwtch_D_Stat2_UB : 45|1@0+ (1,0) [0|1] "SED" Vector__XXX
 SG_ SelDrvMdeSwtch_D_Stat2 : 47|2@0+ (1,0) [0|3] "SED" Vector__XXX
 SG_ FapLcStopHold_B_Rq : 57|1@0+ (1,0) [0|1] "SED" Vector__XXX
 SG_ SelDrvMdeDsply_B_Avail : 51|1@0+ (1,0) [0|1] "SED" Vector__XXX
 SG_ FapLcStopHold_B_Rq_UB : 56|1@0+ (1,0) [0|1] "SED" Vector__XXX
 SG_ FapLcPrchgBrk_B_Rq_UB : 58|1@0+ (1,0) [0|1] "SED" Vector__XXX
 SG_ LnchCtl_N_Rq_UB : 23|1@0+ (1,0) [0|1] "SED" Vector__XXX
 SG_ LnchCtl_D_Rq_UB : 0|1@0+ (1,0) [0|1] "SED" Vector__XXX
 SG_ LnchCtl_N_Rq : 15|8@0+ (50,0) [0|12750] "rpm" Vector__XXX
 SG_ LnchCtl_D_Rq : 2|2@0+ (1,0) [0|3] "SED" Vector__XXX
 SG_ AirSusp_D_RqDrv : 31|2@0+ (1,0) [0|3] "SED" Vector__XXX
 SG_ AwdRnge_D_ActlIpc_UB : 26|1@0+ (1,0) [0|1] "SED" Vector__XXX
 SG_ AwdRnge_D_ActlIpc : 29|3@0+ (1,0) [0|7] "SED" Vector__XXX
 SG_ NtrlTowMdeEnbl_B_RqDrv_UB : 60|1@0+ (1,0) [0|1] "SED" Vector__XXX
 SG_ NtrlTowMdeEnbl_B_RqDrv : 48|1@0+ (1,0) [0|1] "SED" Vector__XXX
 SG_ DrvSlipCtlMde_B_RqMyKey_UB : 17|1@0+ (1,0) [0|1] "SED" Vector__XXX
 SG_ DrvSlipCtlMde_B_RqMyKey : 18|1@0+ (1,0) [0|1] "SED" Vector__XXX
 SG_ AwdDrvMde_D_Rq_UB : 49|1@0+ (1,0) [0|1] "SED" Vector__XXX
 SG_ AwdDrvMde_D_Rq : 63|3@0+ (1,0) [0|7] "SED" Vector__XXX
 SG_ MetricActv_B_Actl_UB : 53|1@0+ (1,0) [0|1] "SED" Vector__XXX
 SG_ MetricActv_B_Actl : 54|1@0+ (1,0) [0|1] "SED" Vector__XXX
 SG_ BrkLineLck_D_Rq_UB : 5|1@0+ (1,0) [0|1] "SED" Vector__XXX
 SG_ BrkLineLck_D_Rq : 7|2@0+ (1,0) [0|3] "SED" Vector__XXX
 SG_ SuspDrvMde_D_Rq_UB : 19|1@0+ (1,0) [0|1] "SED" Vector__XXX
 SG_ SuspDrvMde_D_Rq : 22|3@0+ (1,0) [0|7] "SED" Vector__XXX
 SG_ SelDrvMdePt_D_Stat_UB : 55|1@0+ (1,0) [0|1] "SED" Vector__XXX
 SG_ SelDrvMdePt_D_Stat : 41|2@0+ (1,0) [0|3] "SED" Vector__XXX

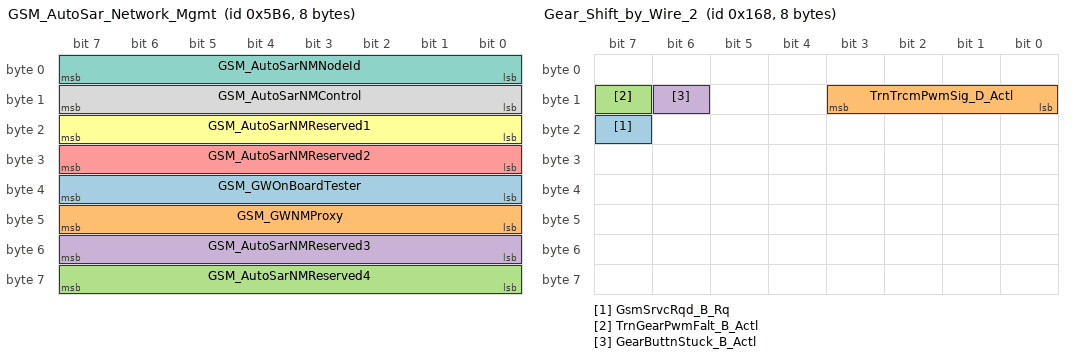
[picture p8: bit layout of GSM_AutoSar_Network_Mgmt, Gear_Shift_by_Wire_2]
BO_ 1462 GSM_AutoSar_Network_Mgmt: 8 GSM
 SG_ GSM_GWOnBoardTester : 39|8@0+ (1,0) [0|255] "unitless"  SCCM,GWM
 SG_ GSM_GWNMProxy : 47|8@0+ (1,0) [0|255] "unitless"  SCCM,GWM
 SG_ GSM_AutoSarNMReserved4 : 63|8@0+ (1,0) [0|255] "unitless"  SCCM,GWM
 SG_ GSM_AutoSarNMReserved3 : 55|8@0+ (1,0) [0|255] "unitless"  SCCM,GWM
 SG_ GSM_AutoSarNMReserved2 : 31|8@0+ (1,0) [0|255] "unitless"  SCCM,GWM
 SG_ GSM_AutoSarNMReserved1 : 23|8@0+ (1,0) [0|255] "unitless"  SCCM,GWM
 SG_ GSM_AutoSarNMNodeId : 7|8@0+ (1,0) [0|255] "unitless"  SCCM,GWM
 SG_ GSM_AutoSarNMControl : 15|8@0+ (1,0) [0|255] "unitless"  SCCM,GWM

BO_ 92 Gear_Shift_by_Wire_3_HS2: 8 GWM
 SG_ TrnGearMsgTxt2_D_Rq : 53|5@0+ (1,0) [0|31] "SED"  GENERIC
 SG_ RaceTrakMde_D_Stat : 55|2@0+ (1,0) [0|3] "SED" Vector__XXX
 SG_ TrnLvrV_D_Rq : 43|2@0+ (1,0) [0|3] "SED" Vector__XXX
 SG_ TrnSbwSysHlth_D_Actl : 1|2@0+ (1,0) [0|3] "SED"  GSM
 SG_ TrnDtpCmd_D_Actl : 46|3@0+ (1,0) [0|7] "SED"  GSM
 SG_ TrnGearNtmAllow_B_Stat : 47|1@0+ (1,0) [0|1] "SED"  GENERIC
 SG_ GearSelLck_D_Rq : 41|2@0+ (1,0) [0|3] "SED"  GSM
 SG_ TrnGearCmd_No_Cs : 31|8@0+ (1,0) [0|255] "Unitless"  GSM
 SG_ TrnValidGear_D_Cnfm : 11|2@0+ (1,0) [0|3] "SED"  GSM
 SG_ TrnNtrlTowCmd_D_Actl : 6|2@0+ (1,0) [0|3] "SED"  GSM
 SG_ TrnGearCmd_Pc_ActlPt : 9|10@0+ (0.1,0) [0|102.2] "percent duty cycle"  GSM
 SG_ TrnGear_D_RqPt : 4|3@0+ (1,0) [0|7] "SED"  GSM
 SG_ TrnCmdState_B_Actl : 39|1@0+ (1,0) [0|1] "SED"  GSM
 SG_ TrnCmdCnt_B_Actl : 7|1@0+ (1,0) [0|1] "unitless"  GSM
 SG_ PrkBrkActv_D_RqTrnGear : 38|2@0+ (1,0) [0|3] "SED"  GSM
 SG_ TrnGearMsgTxt_D_Rq : 36|5@0+ (1,0) [0|31] "SED"  GENERIC
 SG_ TrnGearCmd_No_Cnt : 15|4@0+ (1,0) [0|15] "Unitless"  GSM

BO_ 360 Gear_Shift_by_Wire_2: 8 GSM
 SG_ GsmSrvcRqd_B_Rq : 23|1@0+ (1,0) [0|1] "SED"  GWM
 SG_ TrnTrcmPwmSig_D_Actl : 11|4@0+ (1,0) [0|15] "SED"  GWM
 SG_ TrnGearPwmFalt_B_Actl : 15|1@0+ (1,0) [0|1] "SED"  GWM
 SG_ GearButtnStuck_B_Actl : 14|1@0+ (1,0) [0|1] "SED"  GWM

BO_ 90 Gear_Shift_by_Wire: 8 GSM
 SG_ TrnGsmNtmState_D_Actl : 55|2@0+ (1,0) [0|3] "SED"  GWM
 SG_ DrQltyDrv_D_StatGsm : 42|3@0+ (1,0) [0|7] "SED"  GWM
 SG_ TrnBtsiOvrrd_B_Stat : 43|1@0+ (1,0) [0|1] "SED"  GWM
 SG_ GsmGearMsgTxt_D_Rq : 63|2@0+ (1,0) [0|3] "SED"  GWM
 SG_ TrnRng_D_RqGsm : 51|4@0+ (1,0) [0|15] "SED"  GWM
 SG_ PrkBrkActv_D_RqGsmGear : 53|2@0+ (1,0) [0|3] "SED"  GWM
 SG_ TrnValidGearRq_D_Stat : 25|2@0+ (1,0) [0|3] "SED"  GWM
 SG_ TrnGearRqCnt_B_Actl : 26|1@0+ (1,0) [0|1] "unitless"  GWM
 SG_ TrnGearButtn_U_Actl : 23|8@0+ (0.05,0) [0|12.7] "VOLT"  GWM
 SG_ TrnGearButtn_B_ActlR2 : 8|1@0+ (1,0) [0|1] "SED"  GWM
 SG_ TrnGearButtn_B_ActlR1 : 9|1@0+ (1,0) [0|1] "SED"  GWM
 SG_ TrnGearButtn_B_ActlR0 : 10|1@0+ (1,0) [0|1] "SED"  GWM
 SG_ TrnGearButtn_B_ActlP2 : 11|1@0+ (1,0) [0|1] "SED"  GWM
 SG_ TrnGearButtn_B_ActlP1 : 12|1@0+ (1,0) [0|1] "SED"  GWM
 SG_ TrnGearButtn_B_ActlP0 : 13|1@0+ (1,0) [0|1] "SED"  GWM
 SG_ TrnGearButtn_B_ActlN2 : 14|1@0+ (1,0) [0|1] "SED"  GWM
 SG_ TrnGearButtn_B_ActlN1 : 15|1@0+ (1,0) [0|1] "SED"  GWM
 SG_ TrnGearButtn_B_ActlN0 : 0|1@0+ (1,0) [0|1] "SED"  GWM
 SG_ TrnGearButtn_B_ActlM2 : 1|1@0+ (1,0) [0|1] "SED"  GWM
 SG_ TrnGearButtn_B_ActlM1 : 2|1@0+ (1,0) [0|1] "SED"  GWM
 SG_ TrnGearButtn_B_ActlM0 : 3|1@0+ (1,0) [0|1] "SED"  GWM
 SG_ TrnGearButtn_B_ActlD2 : 4|1@0+ (1,0) [0|1] "SED"  GWM
 SG_ TrnGearButtn_B_ActlD1 : 5|1@0+ (1,0) [0|1] "SED"  GWM
 SG_ TrnGearButtn_B_ActlD0 : 6|1@0+ (1,0) [0|1] "SED"  GWM
 SG_ TrnGear_No_Cs : 39|8@0+ (1,0) [0|255] "Unitless"  GWM
 SG_ TrnGear_No_Cnt : 47|4@0+ (1,0) [0|15] "Unitless"  GWM
 SG_ TrnGear_D_RqDrv : 31|5@0+ (1,0) [0|31] "SED"  GWM
 SG_ BrkSwtchPos_B_ActlGsm : 7|1@0+ (1,0) [0|1] "SED" Vector__XXX

BO_ 1842 TesterPhysicalReqGSM: 8 TSTR
 SG_ TesterPhysicalReqGSM : 7|64@0+ (1,0) [0|1.84467E+019] "unitless"  GSM

BO_ 1850 TesterPhysicalResGSM: 8 GSM
 SG_ TesterPhysicalResGSM : 7|64@0+ (1,0) [0|1.84467E+019] "unitless"  TSTR

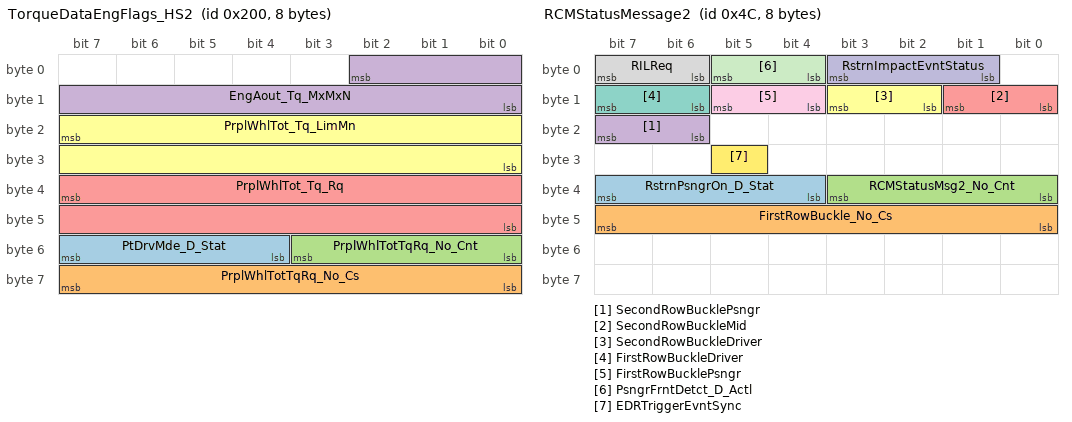
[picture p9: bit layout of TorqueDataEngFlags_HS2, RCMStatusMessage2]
BO_ 512 TorqueDataEngFlags_HS2: 8 GWM
 SG_ PtDrvMde_D_Stat : 55|4@0+ (1,0) [0|15] "SED" Vector__XXX
 SG_ PrplWhlTotTqRq_No_Cs : 63|8@0+ (1,0) [0|255] "Unitless" Vector__XXX
 SG_ PrplWhlTotTqRq_No_Cnt : 51|4@0+ (1,0) [0|15] "Unitless" Vector__XXX
 SG_ EngAout_Tq_MxMxN : 2|11@0+ (1,-500) [-500|1547] "Nm"  GENERIC
 SG_ PrplWhlTot_Tq_Rq : 39|16@0+ (4,-131072) [-131072|131068] "Nm" Vector__XXX
 SG_ PrplWhlTot_Tq_LimMn : 23|16@0+ (4,-131072) [-131072|131068] "Nm" Vector__XXX

BO_ 76 RCMStatusMessage2: 8 RCM
 SG_ RstrnPsngrOn_D_Stat : 39|4@0+ (1,0) [0|15] "SED"  GWM
 SG_ FirstRowBuckle_No_Cs : 47|8@0+ (1,0) [0|255] "unitless"  GWM
 SG_ RCMStatusMsg2_No_Cnt : 35|4@0+ (1,0) [0|15] "Unitless"  GWM
 SG_ SecondRowBucklePsngr : 23|2@0+ (1,0) [0|3] "SED"  GWM
 SG_ SecondRowBuckleMid : 9|2@0+ (1,0) [0|3] "SED"  GWM
 SG_ SecondRowBuckleDriver : 11|2@0+ (1,0) [0|3] "SED"  GWM
 SG_ FirstRowBuckleDriver : 15|2@0+ (1,0) [0|3] "SED"  GSM,GWM
 SG_ RILReq : 7|2@0+ (1,0) [0|3] "SED"  GWM
 SG_ FirstRowBucklePsngr : 13|2@0+ (1,0) [0|3] "SED"  OCS,GWM
 SG_ RstrnImpactEvntStatus : 3|3@0+ (1,0) [0|7] "SED"  SCCM,OCS,GWM
 SG_ PsngrFrntDetct_D_Actl : 5|2@0+ (1,0) [0|3] "SED"  GWM
 SG_ EDRTriggerEvntSync : 29|1@0+ (1,0) [0|1] "SED"  GWM

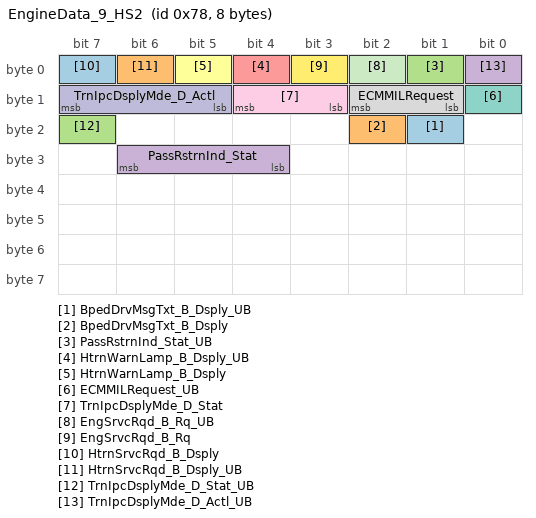
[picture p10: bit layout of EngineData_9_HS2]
BO_ 120 EngineData_9_HS2: 8 GWM
 SG_ BpedDrvMsgTxt_B_Dsply_UB : 17|1@0+ (1,0) [0|1] "SED"  RCM
 SG_ BpedDrvMsgTxt_B_Dsply : 18|1@0+ (1,0) [0|1] "SED" Vector__XXX
 SG_ PassRstrnInd_Stat_UB : 1|1@0+ (1,0) [0|1] "SED" Vector__XXX
 SG_ PassRstrnInd_Stat : 30|3@0+ (1,0) [0|7] "SED" Vector__XXX
 SG_ HtrnWarnLamp_B_Dsply_UB : 4|1@0+ (1,0) [0|1] "SED"  GENERIC
 SG_ HtrnWarnLamp_B_Dsply : 5|1@0+ (1,0) [0|1] "SED"  RCM
 SG_ ECMMILRequest_UB : 8|1@0+ (1,0) [0|1] "SED"  RCM
 SG_ ECMMILRequest : 10|2@0+ (1,0) [0|3] "SED"  RCM
 SG_ TrnIpcDsplyMde_D_Stat : 12|2@0+ (1,0) [0|3] "SED"  GSM
 SG_ TrnIpcDsplyMde_D_Actl : 15|3@0+ (1,0) [0|7] "SED"  GSM
 SG_ EngSrvcRqd_B_Rq_UB : 2|1@0+ (1,0) [0|1] "SED"  GENERIC
 SG_ EngSrvcRqd_B_Rq : 3|1@0+ (1,0) [0|1] "SED"  RCM
 SG_ HtrnSrvcRqd_B_Dsply : 7|1@0+ (1,0) [0|1] "SED"  RCM
 SG_ HtrnSrvcRqd_B_Dsply_UB : 6|1@0+ (1,0) [0|1] "SED"  GENERIC
 SG_ TrnIpcDsplyMde_D_Stat_UB : 23|1@0+ (1,0) [0|1] "SED"  GSM
 SG_ TrnIpcDsplyMde_D_Actl_UB : 0|1@0+ (1,0) [0|1] "SED"  GSM

BO_ 1665 RCM_Rapid_Data_Response_2: 8 RCM
 SG_ UUDTRCMResponse2 : 7|64@0+ (1,0) [0|1.84467440737096E+019] "unitless"  TSTR

BO_ 2041 TesterPhysicalResPCU: 8 RCM
 SG_ TesterPhysicalResPCU : 7|64@0+ (1,0) [0|1.84467E+019] "unitless"  TSTR

CM_ SG_ 133 SteWhlOSRelInit2An_Est "Legacy signal not supported, reserving bit location for commodity IPMA dbc file.  No valid data. ";
CM_ SG_ 133 SteWhlAn_No_Cs "Legacy signal not supported, reserving bit location for commodity IPMA dbc file.  No valid data. ";
CM_ SG_ 133 SteWhlAn_No_Cnt "Legacy signal not supported, reserving bit location for commodity IPMA dbc file.  No valid data. ";
CM_ SG_ 133 SteWhlRelCalib_An_Sns "Signal is not transmitted on vehicles where PSCM is transmitting the message that contains this signal.
Signal data set to 0x0 for ABS only vehicle option content";
CM_ SG_ 133 SteWhlRelInit2_An_Sns "Legacy signal not supported, reserving bit location for commodity IPMA dbc file.  No valid data. ";
CM_ SG_ 1080 DrLatchCntRr_No_Actl "Rolling counts indicate fresh data (DrLatchCntxx) are updated each time new data is sent from a latch to BCM thru the GW. UBs not required.";
CM_ SG_ 1080 DrLatchCntRl_No_Actl "Rolling counts indicate fresh data (DrLatchCntxx) are updated each time new data is sent from a latch to BCM thru the GW. UBs not required.";
CM_ SG_ 1080 DrLatchCntFr_No_Actl "Rolling counts indicate fresh data (DrLatchCntxx) are updated each time new data is sent from a latch to BCM thru the GW. UBs not required.";
CM_ SG_ 1080 DrLatchCntFl_No_Actl "Rolling counts indicate fresh data (DrLatchCntxx) are updated each time new data is sent from a latch to BCM thru the GW. UBs not required.";
CM_ BO_ 673 "Do not use this Frame for other Cluster Interaction";
CM_ SG_ 673 ICI_Coding_BtnID_D "Object InputControlInterface ICI ButtonCoding_D
(Parameter2)";
CM_ SG_ 673 ICI_Coding_BtnID_C "Object InputControlInterface ICI ButtonCoding_C
(Parameter2)";
CM_ SG_ 673 ICI_Coding_BtnID_B "Object InputControlInterface ICI ButtonCoding_B
(Parameter2)";
CM_ SG_ 673 ICI_Coding_BtnID_A "Object InputControlInterface ICI ButtonCoding_A
(Parameter2)";
CM_ SG_ 673 ICI_BtnID_D "Object InputControlInterface ICI ButtonID_D
(Parameter1)
for detailed Information refer to ICI Reference document";
CM_ SG_ 673 ICI_BtnID_C "Object InputControlInterface ICI ButtonID_C
(Parameter1)
for detailed Information refer to ICI Reference document";
CM_ SG_ 673 ICI_BtnID_B "Object InputControlInterface ICI ButtonID_B
(Parameter1)
for detailed Information refer to ICI Reference document";
CM_ SG_ 673 ICI_BtnID_A "Object InputControlInterface ICI ButtonID_A
(Parameter1)
for detailed Information refer to ICI Reference document";
CM_ SG_ 1073 HMI_HMIMode_St "Object ACU System Master.HMIMode
OR
Object NAV System Master.HMIMode

Refer Method HMIAudioMode in the SPSS";
CM_ SG_ 1073 Foh_D_Stat "Signal not transmitted on vehicles that do not have the Fuel operated heater feature.";
CM_ SG_ 1091 PoliceAux4Lamp_B_Rq2 "Signal not transmitted on programs that do not have AWD.";
CM_ SG_ 1091 PoliceAux3Lamp_B_Rq2 "Signal not transmitted on programs that do not have AWD.";
CM_ SG_ 1091 PoliceAux2Lamp_B_Rq2 "Signal not transmitted on programs that do not have AWD.";
CM_ SG_ 1091 PoliceAux1Lamp_B_Rq2 "Signal not transmitted on programs that do not have AWD.";
CM_ BO_ 611 "Used on Applications with 4x4 supplied by Motorola.";
CM_ SG_ 611 AwdStat_D_RqDsply "Signal not transmitted on programs that do not have AWD.";
CM_ SG_ 611 AwdSrvcRqd_B_Rq "Signal not transmitted on programs that do not have AWD.";
CM_ SG_ 611 AwdLck_Tq_Rq "Signal not transmitted on programs that do not have AWD.";
CM_ SG_ 560 SelDrvMdeSwtch_D_Stat3 "ECM_HEV does not support or Transmit signal.";
CM_ SG_ 560 TrnGbox_Rt_Actl "Signal not transmitted on Gas & HEV variants. MHT(U611/625) HPCM Rx 0x230 from PCM_HEV. Powersplit FWD HEV’s(Cx482/3 430) HPCM Tx 0x230.";
CM_ SG_ 560 TrnSrvcRqd_B_Rq "Signal not transmitted on Diesel & HEV variants. MHT(U611/625) HPCM Rx 0x230 from PCM_HEV. Powersplit FWD HEV’s(Cx482/3 430) HPCM Tx 0x230.";
CM_ SG_ 560 TrnCnvtClu_D_Actl "Signal not transmitted on Gas & HEV variants. MHT(U611/625) HPCM Rx 0x230 from PCM_HEV. Powersplit FWD HEV’s(Cx482/3 430) HPCM Tx 0x230.";
CM_ SG_ 560 TrnShifActv_B_Actl "Signal not transmitted on HEV variants. MHT(U611/625) HPCM Rx 0x230 from PCM_HEV. Powersplit FWD HEV’s(Cx482/3 430) HPCM Tx 0x230.";
CM_ SG_ 560 GboxOil_Te_Actl "Signal not transmitted on HEV variants. MHT(U611/625) HPCM Rx 0x230 from PCM_HEV. Powersplit FWD HEV’s(Cx482/3 430) HPCM Tx 0x230.";
CM_ SG_ 560 GearLvrPosActl_No_Cs "Signal not transmitted on Gas & HEV variants. MHT(U611/625) HPCM Rx 0x230 from PCM_HEV. Powersplit FWD HEV’s(Cx482/3 430) HPCM Tx 0x230.";
CM_ SG_ 560 GearLvrPosActl_No_Cnt "Signal not transmitted on Gas & HEV variants. MHT(U611/625) HPCM Rx 0x230 from PCM_HEV. Powersplit FWD HEV’s(Cx482/3 430) HPCM Tx 0x230.";
CM_ SG_ 359 TrnAin_Tq_Actl "Signal not transmitted on HEV variances.";
CM_ SG_ 359 TrnAinTq_D_Qf "Signal not transmitted on HEV variances.";
CM_ SG_ 359 PlgActvArb_B_Actl "Only supported on PHEV programs.  PlgActvArb_B_Actl HPCM will Tx on Powersplit PHEV’s,  On MHT PHEVs the PCM_HEV will Tx and HPCM will Rx. 
";
CM_ SG_ 390 AccPrpl_A_Rq "PCMGenSigTimeoutTime=1000";
CM_ SG_ 1071 CluPdl_PcRate_Actl "Signal not transmitted on HEV variants.";
CM_ SG_ 1071 CluPdlPosPcMeas_D_Qf "Signal not transmitted on HEV variants.";
CM_ SG_ 1071 CluPdlPos_Pc_Meas "Signal not transmitted on HEV variants.";
CM_ SG_ 1071 EngAoutIdl_N_Ntrl "Signal not transmitted on HEV variants and diesel.";
CM_ SG_ 1072 Outside_Air_Temp_Stat "Filtered value, i.e. same as disply for customer";
CM_ SG_ 1058 TrnTotTq_Rt_Est "Signal not transmitted on gas and HEV variants.";
CM_ SG_ 1058 TrnTotLss_Tq_Est "Signal not transmitted on gas and HEV variants.";
CM_ SG_ 1082 MetricActv_B_Actl "0 =Inactive(English), 1=Active(Metric)";
CM_ SG_ 92 TrnGearMsgTxt2_D_Rq "Signal not transmitted on vehicles that do not have shift by wire.";
CM_ SG_ 92 TrnSbwSysHlth_D_Actl "Signal not transmitted on vehicles that do not have shift by wire.";
CM_ SG_ 92 TrnDtpCmd_D_Actl "Signal not transmitted on vehicles that do not have shift by wire.";
CM_ SG_ 92 TrnGearNtmAllow_B_Stat "Signal not transmitted on vehicles that do not have shift by wire.";
CM_ SG_ 92 TrnGearCmd_No_Cs "Signal not transmitted on vehicles that do not have shift by wire.";
CM_ SG_ 92 TrnValidGear_D_Cnfm "Signal not transmitted on vehicles that do not have shift by wire.";
CM_ SG_ 92 TrnNtrlTowCmd_D_Actl "Signal not transmitted on vehicles that do not have shift by wire.";
CM_ SG_ 92 TrnGearCmd_Pc_ActlPt "Signal not transmitted on vehicles that do not have shift by wire.";
CM_ SG_ 92 TrnGear_D_RqPt "Signal not transmitted on vehicles that do not have shift by wire.";
CM_ SG_ 92 TrnCmdState_B_Actl "Signal not transmitted on vehicles that do not have shift by wire.";
CM_ SG_ 92 TrnCmdCnt_B_Actl "Signal not transmitted on vehicles that do not have shift by wire.";
CM_ SG_ 92 PrkBrkActv_D_RqTrnGear "Signal not transmitted on vehicles that do not have shift by wire.";
CM_ SG_ 92 TrnGearMsgTxt_D_Rq "Signal not transmitted on vehicles that do not have shift by wire.";
CM_ SG_ 92 TrnGearCmd_No_Cnt "Signal not transmitted on vehicles that do not have shift by wire.";
CM_ SG_ 360 GsmSrvcRqd_B_Rq "Signal not transmitted on vehicles that do not have shift by wire.";
CM_ SG_ 360 TrnTrcmPwmSig_D_Actl "Signal not transmitted on vehicles that do not have shift by wire.";
CM_ SG_ 360 TrnGearPwmFalt_B_Actl "Signal not transmitted on vehicles that do not have shift by wire.";
CM_ SG_ 360 GearButtnStuck_B_Actl "Signal not transmitted on vehicles that do not have shift by wire.";
CM_ SG_ 90 TrnGsmNtmState_D_Actl "Signal not transmitted on vehicles that do not have shift by wire.";
CM_ SG_ 90 DrQltyDrv_D_StatGsm "Signal not transmitted on vehicles that do not have shift by wire.";
CM_ SG_ 90 TrnBtsiOvrrd_B_Stat "Signal not transmitted on vehicles that do not have shift by wire.";
CM_ SG_ 90 TrnValidGearRq_D_Stat "Signal not transmitted on vehicles that do not have shift by wire.";
CM_ SG_ 90 TrnGearRqCnt_B_Actl "Signal not transmitted on vehicles that do not have shift by wire.";
CM_ SG_ 90 TrnGearButtn_U_Actl "Signal not transmitted on vehicles that do not have shift by wire.";
CM_ SG_ 90 TrnGearButtn_B_ActlR2 "Signal not transmitted on vehicles that do not have shift by wire.";
CM_ SG_ 90 TrnGearButtn_B_ActlR1 "Signal not transmitted on vehicles that do not have shift by wire.";
CM_ SG_ 90 TrnGearButtn_B_ActlR0 "Signal not transmitted on vehicles that do not have shift by wire.";
CM_ SG_ 90 TrnGearButtn_B_ActlP2 "Signal not transmitted on vehicles that do not have shift by wire.";
CM_ SG_ 90 TrnGearButtn_B_ActlP1 "Signal not transmitted on vehicles that do not have shift by wire.";
CM_ SG_ 90 TrnGearButtn_B_ActlP0 "Signal not transmitted on vehicles that do not have shift by wire.";
CM_ SG_ 90 TrnGearButtn_B_ActlN2 "Signal not transmitted on vehicles that do not have shift by wire.";
CM_ SG_ 90 TrnGearButtn_B_ActlN1 "Signal not transmitted on vehicles that do not have shift by wire.";
CM_ SG_ 90 TrnGearButtn_B_ActlN0 "Signal not transmitted on vehicles that do not have shift by wire.";
CM_ SG_ 90 TrnGearButtn_B_ActlM2 "Signal not transmitted on vehicles that do not have shift by wire.";
CM_ SG_ 90 TrnGearButtn_B_ActlM1 "Signal not transmitted on vehicles that do not have shift by wire.";
CM_ SG_ 90 TrnGearButtn_B_ActlM0 "Signal not transmitted on vehicles that do not have shift by wire.";
CM_ SG_ 90 TrnGearButtn_B_ActlD2 "Signal not transmitted on vehicles that do not have shift by wire.";
CM_ SG_ 90 TrnGearButtn_B_ActlD1 "Signal not transmitted on vehicles that do not have shift by wire.";
CM_ SG_ 90 TrnGearButtn_B_ActlD0 "Signal not transmitted on vehicles that do not have shift by wire.";
CM_ SG_ 90 TrnGear_No_Cs "Signal not transmitted on vehicles that do not have shift by wire.";
CM_ SG_ 90 TrnGear_No_Cnt "Signal not transmitted on vehicles that do not have shift by wire.";
CM_ SG_ 90 TrnGear_D_RqDrv "Signal not transmitted on vehicles that do not have shift by wire.";
CM_ SG_ 90 BrkSwtchPos_B_ActlGsm "Signal not transmitted on vehicles that do not have shift by wire.";
CM_ SG_ 512 PrplWhlTotTqRq_No_Cs "Signal not transmitted on gas variants.";
CM_ SG_ 512 PrplWhlTotTqRq_No_Cnt "Signal not transmitted on gas variants.";
CM_ SG_ 512 EngAout_Tq_MxMxN "Signal not transmitted on gas variants.";
BA_DEF_ BO_  "FrameRouting" STRING ;
BA_DEF_ BO_  "FrameGatewayNetwork" STRING ;
BA_DEF_ BO_  "NetworkInitialization" ENUM  "No","Yes";
BA_DEF_ BO_  "FrameGatewayId" HEX 0 1407;
BA_DEF_ BO_  "EventRateOfChange" INT 10 10000;
BA_DEF_ BO_  "GenMsgNrOfRepetition" INT 0 100;
BA_DEF_ BO_  "GenMsgDelayTime" INT 0 1000;
BA_DEF_ BO_  "GenMsgCycleTime" INT 0 100000;
BA_DEF_ BO_  "GenMsgSendType" ENUM  "FixedPeriodic","Event","EnabledPeriodic","NotUsed","NotUsed","EventPeriodic","NotUsed","NotUsed","NoMsgSendType";
BA_DEF_ SG_  "U_CD764_MY2022_Tx" ENUM  "No","Yes";
BA_DEF_ SG_  "U_U55X_MY2022_Tx" ENUM  "No","Yes";
BA_DEF_ SG_  "U_CD542_MY2021_Tx" ENUM  "No","Yes";
BA_DEF_ SG_  "ECGUsedTxSignal" ENUM  "No","Yes";
BA_DEF_ SG_  "U_T6_MCA_MY2020_Tx" ENUM  "No","Yes";
BA_DEF_ SG_  "U_P702_MY2021_Tx" ENUM  "No","Yes";
BA_DEF_ SG_  "U_CX727_MY2021_Tx" ENUM  "No","Yes";
BA_DEF_ SG_  "U_CD764_MY2022_Rx" ENUM  "No","Yes";
BA_DEF_ SG_  "U_U55X_MY2022_Rx" ENUM  "No","Yes";
BA_DEF_ SG_  "U_CD542_MY2021_Rx" ENUM  "No","Yes";
BA_DEF_ SG_  "ECGUsedRxSignal" ENUM  "No","Yes";
BA_DEF_ SG_  "U_T6_MCA_MY2020_Rx" ENUM  "No","Yes";
BA_DEF_ SG_  "U_P702_MY2021_Rx" ENUM  "No","Yes";
BA_DEF_ SG_  "U_CX727_MY2021_Rx" ENUM  "No","Yes";
BA_DEF_ SG_  "GenSigStartValue" HEX 0 268435455;
BA_DEF_ SG_  "MetaData" ENUM  "No","Yes";
BA_DEF_ SG_  "ContentDependant" ENUM  "No","Yes";
BA_DEF_ SG_  "GenSigStartValueInteger" INT 0 1000000000;
BA_DEF_ SG_  "UsedOnPgmDBC" ENUM  "No","Yes";
BA_DEF_ SG_  "WakeupSignal" ENUM  "No","Yes";
BA_DEF_ SG_  "GenSigInactiveValue" INT 0 100000;
BA_DEF_ SG_  "GenSigSendType" ENUM  "Cyclic","OnWrite","vector_leerstring","OnChange","vector_leerstring","IfActive","vector_leerstring","NoSigSendType";
BA_DEF_ BO_  "OvtpPushApplication" ENUM  "FALSE","TRUE";
BA_DEF_ BO_  "SCP_FreshnessValueLength" INT 0 512;
BA_DEF_ BO_  "SCP_FreshnessValueTxLength" INT 0 512;
BA_DEF_ BO_  "SCP_AuthInfoTxLength" INT 0 512;
BA_DEF_ BO_  "GenMsgRoutingTimeoutTime" INT 0 5000;
BA_DEF_ BO_  "MessageGateway" ENUM  "No","Yes";
BA_DEF_ BO_  "NmAsrMessage" ENUM  "No","Yes";
BA_DEF_ BO_  "TpApplType" STRING ;
BA_DEF_ BO_  "DiagState" ENUM  "No","Yes";
BA_DEF_ BO_  "TpTxIndex" INT 0 536870911;
BA_DEF_ BO_  "DiagRequest" ENUM  "No","Yes";
BA_DEF_ BO_  "DiagResponse" ENUM  "No","Yes";
BA_DEF_ BO_  "GenMsgILSupport" ENUM  "No","Yes";
BA_DEF_DEF_  "FrameRouting" "";
BA_DEF_DEF_  "FrameGatewayNetwork" "NONE";
BA_DEF_DEF_  "NetworkInitialization" "Yes";
BA_DEF_DEF_  "FrameGatewayId" 0;
BA_DEF_DEF_  "EventRateOfChange" 10000;
BA_DEF_DEF_  "GenMsgNrOfRepetition" 1;
BA_DEF_DEF_  "GenMsgDelayTime" 20;
BA_DEF_DEF_  "GenMsgCycleTime" 0;
BA_DEF_DEF_  "GenMsgSendType" "NoMsgSendType";
BA_DEF_DEF_  "U_CD764_MY2022_Tx" "No";
BA_DEF_DEF_  "U_U55X_MY2022_Tx" "No";
BA_DEF_DEF_  "U_CD542_MY2021_Tx" "No";
BA_DEF_DEF_  "ECGUsedTxSignal" "No";
BA_DEF_DEF_  "U_T6_MCA_MY2020_Tx" "No";
BA_DEF_DEF_  "U_P702_MY2021_Tx" "No";
BA_DEF_DEF_  "U_CX727_MY2021_Tx" "No";
BA_DEF_DEF_  "U_CD764_MY2022_Rx" "No";
BA_DEF_DEF_  "U_U55X_MY2022_Rx" "No";
BA_DEF_DEF_  "U_CD542_MY2021_Rx" "No";
BA_DEF_DEF_  "ECGUsedRxSignal" "No";
BA_DEF_DEF_  "U_T6_MCA_MY2020_Rx" "No";
BA_DEF_DEF_  "U_P702_MY2021_Rx" "No";
BA_DEF_DEF_  "U_CX727_MY2021_Rx" "No";
BA_DEF_DEF_  "GenSigStartValue" 0;
BA_DEF_DEF_  "MetaData" "No";
BA_DEF_DEF_  "ContentDependant" "No";
BA_DEF_DEF_  "GenSigStartValueInteger" 0;
BA_DEF_DEF_  "UsedOnPgmDBC" "Yes";
BA_DEF_DEF_  "WakeupSignal" "No";
BA_DEF_DEF_  "GenSigInactiveValue" 0;
BA_DEF_DEF_  "GenSigSendType" "NoSigSendType";
BA_DEF_DEF_  "OvtpPushApplication" "FALSE";
BA_DEF_DEF_  "SCP_FreshnessValueLength" 64;
BA_DEF_DEF_  "SCP_FreshnessValueTxLength" 11;
BA_DEF_DEF_  "SCP_AuthInfoTxLength" 53;
BA_DEF_DEF_  "GenMsgRoutingTimeoutTime" 0;
BA_DEF_DEF_  "MessageGateway" "No";
BA_DEF_DEF_  "NmAsrMessage" "No";
BA_DEF_DEF_  "TpApplType" "";
BA_DEF_DEF_  "DiagState" "No";
BA_DEF_DEF_  "TpTxIndex" 0;
BA_DEF_DEF_  "DiagRequest" "No";
BA_DEF_DEF_  "DiagResponse" "No";
BA_DEF_DEF_  "GenMsgILSupport" "Yes";
BA_ "FrameGatewayId" BO_ 1186 1186;
BA_ "FrameGatewayNetwork" BO_ 1186 "FD1_CAN";
BA_ "FrameRouting" BO_ 1186 "FD1_CAN,0x4A2;";
BA_ "FrameGatewayId" BO_ 132 132;
BA_ "FrameGatewayNetwork" BO_ 132 "HS1_CAN";
BA_ "FrameRouting" BO_ 132 "HS1_CAN,0x84;";
BA_ "GenMsgSendType" BO_ 133 0;
BA_ "GenMsgCycleTime" BO_ 133 10;
BA_ "GenMsgDelayTime" BO_ 133 0;
BA_ "FrameGatewayId" BO_ 945 945;
BA_ "FrameGatewayNetwork" BO_ 945 "HS1_CAN";
BA_ "FrameRouting" BO_ 945 "HS1_CAN,0x3B1;";
BA_ "GenMsgSendType" BO_ 1080 5;
BA_ "GenMsgCycleTime" BO_ 1080 1000;
BA_ "GenMsgSendType" BO_ 1121 5;
BA_ "GenMsgCycleTime" BO_ 1121 1000;
BA_ "GenMsgSendType" BO_ 673 5;
BA_ "GenMsgCycleTime" BO_ 673 100;
BA_ "FrameGatewayId" BO_ 845 845;
BA_ "FrameGatewayNetwork" BO_ 845 "MS1_CAN";
BA_ "FrameRouting" BO_ 845 "MS1_CAN,0x34D;";
BA_ "FrameGatewayId" BO_ 850 850;
BA_ "FrameGatewayNetwork" BO_ 850 "MS1_CAN";
BA_ "FrameRouting" BO_ 850 "MS1_CAN,0x352;";
BA_ "FrameGatewayId" BO_ 820 820;
BA_ "FrameGatewayNetwork" BO_ 820 "FD1_CAN";
BA_ "FrameRouting" BO_ 820 "FD1_CAN,0x334;";
BA_ "FrameRouting" BO_ 935 "FD1_CAN,0x3A7;";
BA_ "FrameRouting" BO_ 934 "FD1_CAN,0x3A6;";
BA_ "GenMsgSendType" BO_ 1073 5;
BA_ "GenMsgCycleTime" BO_ 1073 1000;
BA_ "FrameRouting" BO_ 1091 "HS3_CAN,0x443;MS1_CAN,0x443";
BA_ "MessageGateway" BO_ 1068 1;
BA_ "GenMsgRoutingTimeoutTime" BO_ 1068 150;
BA_ "GenMsgSendType" BO_ 1068 5;
BA_ "GenMsgCycleTime" BO_ 1068 100;
BA_ "FrameGatewayId" BO_ 611 611;
BA_ "FrameGatewayNetwork" BO_ 611 "FD1_CAN";
BA_ "FrameRouting" BO_ 611 "FD1_CAN,0x263;";
BA_ "FrameGatewayId" BO_ 395 395;
BA_ "FrameGatewayNetwork" BO_ 395 "HS3_CAN";
BA_ "FrameRouting" BO_ 395 "HS3_CAN,0x18B;";
BA_ "MessageGateway" BO_ 578 1;
BA_ "GenMsgRoutingTimeoutTime" BO_ 578 120;
BA_ "GenMsgSendType" BO_ 578 5;
BA_ "GenMsgCycleTime" BO_ 578 100;
BA_ "MessageGateway" BO_ 560 1;
BA_ "GenMsgRoutingTimeoutTime" BO_ 560 60;
BA_ "GenMsgSendType" BO_ 560 5;
BA_ "GenMsgCycleTime" BO_ 560 100;
BA_ "GenMsgDelayTime" BO_ 560 10;
BA_ "GenMsgDelayTime" BO_ 359 0;
BA_ "FrameGatewayId" BO_ 359 359;
BA_ "FrameGatewayNetwork" BO_ 359 "FD1_CAN";
BA_ "FrameRouting" BO_ 359 "FD1_CAN,0x167;";
BA_ "MessageGateway" BO_ 357 1;
BA_ "GenMsgRoutingTimeoutTime" BO_ 357 60;
BA_ "GenMsgSendType" BO_ 357 5;
BA_ "GenMsgCycleTime" BO_ 357 100;
BA_ "GenMsgDelayTime" BO_ 357 10;
BA_ "FrameGatewayId" BO_ 390 390;
BA_ "FrameGatewayNetwork" BO_ 390 "FD1_CAN";
BA_ "FrameRouting" BO_ 390 "FD1_CAN,0x186;";
BA_ "FrameGatewayId" BO_ 1071 1071;
BA_ "FrameGatewayNetwork" BO_ 1071 "FD1_CAN";
BA_ "FrameRouting" BO_ 1071 "FD1_CAN,0x42F;";
BA_ "GenMsgSendType" BO_ 1072 5;
BA_ "GenMsgCycleTime" BO_ 1072 100;
BA_ "GenMsgSendType" BO_ 1058 0;
BA_ "GenMsgCycleTime" BO_ 1058 100;
BA_ "GenMsgSendType" BO_ 1082 5;
BA_ "GenMsgCycleTime" BO_ 1082 1000;
BA_ "GenMsgILSupport" BO_ 1462 0;
BA_ "NmAsrMessage" BO_ 1462 1;
BA_ "GenMsgSendType" BO_ 1462 0;
BA_ "GenMsgCycleTime" BO_ 1462 1000;
BA_ "NetworkInitialization" BO_ 1462 0;
BA_ "FrameGatewayId" BO_ 92 92;
BA_ "FrameGatewayNetwork" BO_ 92 "FD1_CAN";
BA_ "FrameRouting" BO_ 92 "FD1_CAN,0x5C;";
BA_ "GenMsgSendType" BO_ 360 0;
BA_ "GenMsgCycleTime" BO_ 360 1000;
BA_ "GenMsgSendType" BO_ 90 5;
BA_ "GenMsgCycleTime" BO_ 90 100;
BA_ "GenMsgILSupport" BO_ 1842 0;
BA_ "DiagRequest" BO_ 1842 1;
BA_ "GenMsgSendType" BO_ 1842 1;
BA_ "GenMsgDelayTime" BO_ 1842 0;
BA_ "NetworkInitialization" BO_ 1842 0;
BA_ "GenMsgILSupport" BO_ 1850 0;
BA_ "DiagResponse" BO_ 1850 1;
BA_ "GenMsgSendType" BO_ 1850 1;
BA_ "GenMsgDelayTime" BO_ 1850 0;
BA_ "NetworkInitialization" BO_ 1850 0;
BA_ "GenMsgDelayTime" BO_ 512 10;
BA_ "FrameGatewayId" BO_ 512 512;
BA_ "FrameGatewayNetwork" BO_ 512 "FD1_CAN";
BA_ "FrameRouting" BO_ 512 "FD1_CAN,0x200;";
BA_ "GenMsgSendType" BO_ 76 5;
BA_ "GenMsgCycleTime" BO_ 76 100;
BA_ "GenMsgDelayTime" BO_ 76 10;
BA_ "GenMsgSendType" BO_ 120 5;
BA_ "GenMsgCycleTime" BO_ 120 100;
BA_ "GenMsgDelayTime" BO_ 120 10;
BA_ "GenMsgILSupport" BO_ 1665 0;
BA_ "TpApplType" BO_ 1665 "DiagUUDTResponse";
BA_ "GenMsgSendType" BO_ 1665 1;
BA_ "NetworkInitialization" BO_ 1665 0;
BA_ "GenMsgILSupport" BO_ 2041 0;
BA_ "GenMsgSendType" BO_ 2041 1;
BA_ "GenMsgDelayTime" BO_ 2041 0;
BA_ "NetworkInitialization" BO_ 2041 0;
BA_ "GenSigStartValue" SG_ 1186 FrontDiffLck_Tq_Actl 16382;
BA_ "GenSigStartValueInteger" SG_ 1186 SelDrvMdeAwd2_D_Stat 31;
BA_ "GenSigStartValue" SG_ 1186 SelDrvMdeAwd2_D_Stat 31;
BA_ "U_P702_MY2021_Rx" SG_ 1186 RearDiffLckLamp_D_Rq 1;
BA_ "U_U55X_MY2022_Rx" SG_ 1186 RearDiffLckLamp_D_Rq 1;
BA_ "U_T6_MCA_MY2020_Rx" SG_ 132 GlblClkYr_No_Actl 1;
BA_ "U_U55X_MY2022_Rx" SG_ 132 GlblClkYr_No_Actl 1;
BA_ "U_CD764_MY2022_Rx" SG_ 132 GlblClkYr_No_Actl 1;
BA_ "U_T6_MCA_MY2020_Rx" SG_ 132 GlblClkScnd_No_Actl 1;
BA_ "U_U55X_MY2022_Rx" SG_ 132 GlblClkScnd_No_Actl 1;
BA_ "U_CD764_MY2022_Rx" SG_ 132 GlblClkScnd_No_Actl 1;
BA_ "U_T6_MCA_MY2020_Rx" SG_ 132 GlblClkMnte_No_Actl 1;
BA_ "U_U55X_MY2022_Rx" SG_ 132 GlblClkMnte_No_Actl 1;
BA_ "U_CD764_MY2022_Rx" SG_ 132 GlblClkMnte_No_Actl 1;
BA_ "U_T6_MCA_MY2020_Rx" SG_ 132 GlblClkHr_No_Actl 1;
BA_ "U_U55X_MY2022_Rx" SG_ 132 GlblClkHr_No_Actl 1;
BA_ "U_CD764_MY2022_Rx" SG_ 132 GlblClkHr_No_Actl 1;
BA_ "U_T6_MCA_MY2020_Rx" SG_ 132 GlblClkDay_No_Actl 1;
BA_ "U_U55X_MY2022_Rx" SG_ 132 GlblClkDay_No_Actl 1;
BA_ "U_CD764_MY2022_Rx" SG_ 132 GlblClkDay_No_Actl 1;
BA_ "GenSigStartValueInteger" SG_ 133 SteWhlOSRelInit2An_Est 65534;
BA_ "ContentDependant" SG_ 133 SteWhlOSRelInit2An_Est 1;
BA_ "GenSigStartValue" SG_ 133 SteWhlOSRelInit2An_Est 65533;
BA_ "ContentDependant" SG_ 133 SteWhlAn_No_Cs 1;
BA_ "MetaData" SG_ 133 SteWhlAn_No_Cs 1;
BA_ "ContentDependant" SG_ 133 SteWhlAn_No_Cnt 1;
BA_ "MetaData" SG_ 133 SteWhlAn_No_Cnt 1;
BA_ "ContentDependant" SG_ 133 SteWhlRelCalib_An_Sns 1;
BA_ "U_P702_MY2021_Rx" SG_ 133 SteWhlRelCalib_An_Sns 1;
BA_ "U_T6_MCA_MY2020_Rx" SG_ 133 SteWhlRelCalib_An_Sns 1;
BA_ "U_CD764_MY2022_Rx" SG_ 133 SteWhlRelCalib_An_Sns 1;
BA_ "U_P702_MY2021_Tx" SG_ 133 SteWhlRelCalib_An_Sns 1;
BA_ "GenSigStartValueInteger" SG_ 133 SteWhlRelInit2_An_Sns 65535;
BA_ "ContentDependant" SG_ 133 SteWhlRelInit2_An_Sns 1;
BA_ "GenSigStartValue" SG_ 133 SteWhlRelInit2_An_Sns 65535;
BA_ "U_CX727_MY2021_Rx" SG_ 133 SteWhlRelInit2_An_Sns 1;
BA_ "U_P702_MY2021_Rx" SG_ 133 SteWhlRelInit2_An_Sns 1;
BA_ "WakeupSignal" SG_ 945 PrkLckCtlMsgTxt_D2_Rq 1;
BA_ "WakeupSignal" SG_ 945 PwLoApim_T_Actl 1;
BA_ "WakeupSignal" SG_ 945 KeyPadCodeDgt6_D_Dsply 1;
BA_ "WakeupSignal" SG_ 945 KeyPadCodeDgt5_D_Dsply 1;
BA_ "WakeupSignal" SG_ 945 KeyPadCodeDgt4_D_Dsply 1;
BA_ "WakeupSignal" SG_ 945 KeyPadCodeDgt3_D_Dsply 1;
BA_ "WakeupSignal" SG_ 945 KeyPadCodeDgt2_D_Dsply 1;
BA_ "WakeupSignal" SG_ 945 KeyPadCodeDgt1_D_Dsply 1;
BA_ "GenSigSendType" SG_ 1080 TrlrAidMde_D_Rq 3;
BA_ "GenSigSendType" SG_ 1080 Rba_D_Rq 3;
BA_ "GenSigSendType" SG_ 1080 TrailCtlSwtch_B_Stat 3;
BA_ "GenSigSendType" SG_ 1080 TrailCtlPt_B_Falt 3;
BA_ "U_CX727_MY2021_Rx" SG_ 1080 AutoTowActv_B_Stat_UB 1;
BA_ "GenSigSendType" SG_ 1080 AutoTowActv_B_Stat 3;
BA_ "U_CX727_MY2021_Rx" SG_ 1080 AutoTowActv_B_Stat 1;
BA_ "U_P702_MY2021_Rx" SG_ 1080 AutoTowActv_B_Stat 1;
BA_ "U_CX727_MY2021_Rx" SG_ 1080 DrLatchLckRr_B_Stat_UB 1;
BA_ "U_P702_MY2021_Rx" SG_ 1080 DrLatchLckRr_B_Stat_UB 1;
BA_ "U_T6_MCA_MY2020_Rx" SG_ 1080 DrLatchLckRr_B_Stat_UB 1;
BA_ "U_CX727_MY2021_Rx" SG_ 1080 DrLatchLckRl_B_Stat_UB 1;
BA_ "U_P702_MY2021_Rx" SG_ 1080 DrLatchLckRl_B_Stat_UB 1;
BA_ "U_T6_MCA_MY2020_Rx" SG_ 1080 DrLatchLckRl_B_Stat_UB 1;
BA_ "U_CX727_MY2021_Rx" SG_ 1080 DrLatchLckFr_B_Stat_UB 1;
BA_ "U_P702_MY2021_Rx" SG_ 1080 DrLatchLckFr_B_Stat_UB 1;
BA_ "U_T6_MCA_MY2020_Rx" SG_ 1080 DrLatchLckFr_B_Stat_UB 1;
BA_ "U_CD542_MY2021_Rx" SG_ 1080 DrLatchLckFr_B_Stat_UB 1;
BA_ "U_U55X_MY2022_Rx" SG_ 1080 DrLatchLckFr_B_Stat_UB 1;
BA_ "U_CD764_MY2022_Rx" SG_ 1080 DrLatchLckFr_B_Stat_UB 1;
BA_ "U_CX727_MY2021_Rx" SG_ 1080 DrLatchLckFl_B_Stat_UB 1;
BA_ "U_P702_MY2021_Rx" SG_ 1080 DrLatchLckFl_B_Stat_UB 1;
BA_ "U_T6_MCA_MY2020_Rx" SG_ 1080 DrLatchLckFl_B_Stat_UB 1;
BA_ "U_CD542_MY2021_Rx" SG_ 1080 DrLatchLckFl_B_Stat_UB 1;
BA_ "U_U55X_MY2022_Rx" SG_ 1080 DrLatchLckFl_B_Stat_UB 1;
BA_ "U_CD764_MY2022_Rx" SG_ 1080 DrLatchLckFl_B_Stat_UB 1;
BA_ "U_CX727_MY2021_Rx" SG_ 1080 DrLatchRr_B_Falt_UB 1;
BA_ "U_P702_MY2021_Rx" SG_ 1080 DrLatchRr_B_Falt_UB 1;
BA_ "U_T6_MCA_MY2020_Rx" SG_ 1080 DrLatchRr_B_Falt_UB 1;
BA_ "U_CX727_MY2021_Rx" SG_ 1080 DrLatchRl_B_Falt_UB 1;
BA_ "U_P702_MY2021_Rx" SG_ 1080 DrLatchRl_B_Falt_UB 1;
BA_ "U_T6_MCA_MY2020_Rx" SG_ 1080 DrLatchRl_B_Falt_UB 1;
BA_ "U_CX727_MY2021_Rx" SG_ 1080 DrLatchFr_B_Falt_UB 1;
BA_ "U_P702_MY2021_Rx" SG_ 1080 DrLatchFr_B_Falt_UB 1;
BA_ "U_T6_MCA_MY2020_Rx" SG_ 1080 DrLatchFr_B_Falt_UB 1;
BA_ "U_CD542_MY2021_Rx" SG_ 1080 DrLatchFr_B_Falt_UB 1;
BA_ "U_U55X_MY2022_Rx" SG_ 1080 DrLatchFr_B_Falt_UB 1;
BA_ "U_CD764_MY2022_Rx" SG_ 1080 DrLatchFr_B_Falt_UB 1;
BA_ "U_CX727_MY2021_Rx" SG_ 1080 DrLatchFl_B_Falt_UB 1;
BA_ "U_P702_MY2021_Rx" SG_ 1080 DrLatchFl_B_Falt_UB 1;
BA_ "U_T6_MCA_MY2020_Rx" SG_ 1080 DrLatchFl_B_Falt_UB 1;
BA_ "U_CD542_MY2021_Rx" SG_ 1080 DrLatchFl_B_Falt_UB 1;
BA_ "U_U55X_MY2022_Rx" SG_ 1080 DrLatchFl_B_Falt_UB 1;
BA_ "U_CD764_MY2022_Rx" SG_ 1080 DrLatchFl_B_Falt_UB 1;
BA_ "U_CX727_MY2021_Rx" SG_ 1080 DrLatchCntRr_No_Actl_UB 1;
BA_ "U_P702_MY2021_Rx" SG_ 1080 DrLatchCntRr_No_Actl_UB 1;
BA_ "U_T6_MCA_MY2020_Rx" SG_ 1080 DrLatchCntRr_No_Actl_UB 1;
BA_ "U_CX727_MY2021_Rx" SG_ 1080 DrLatchCntRl_No_Actl_UB 1;
BA_ "U_P702_MY2021_Rx" SG_ 1080 DrLatchCntRl_No_Actl_UB 1;
BA_ "U_T6_MCA_MY2020_Rx" SG_ 1080 DrLatchCntRl_No_Actl_UB 1;
BA_ "U_CX727_MY2021_Rx" SG_ 1080 DrLatchCntFr_No_Actl_UB 1;
BA_ "U_P702_MY2021_Rx" SG_ 1080 DrLatchCntFr_No_Actl_UB 1;
BA_ "U_T6_MCA_MY2020_Rx" SG_ 1080 DrLatchCntFr_No_Actl_UB 1;
BA_ "U_CD542_MY2021_Rx" SG_ 1080 DrLatchCntFr_No_Actl_UB 1;
BA_ "U_U55X_MY2022_Rx" SG_ 1080 DrLatchCntFr_No_Actl_UB 1;
BA_ "U_CD764_MY2022_Rx" SG_ 1080 DrLatchCntFr_No_Actl_UB 1;
BA_ "U_CX727_MY2021_Rx" SG_ 1080 DrLatchCntFl_No_Actl_UB 1;
BA_ "U_P702_MY2021_Rx" SG_ 1080 DrLatchCntFl_No_Actl_UB 1;
BA_ "U_T6_MCA_MY2020_Rx" SG_ 1080 DrLatchCntFl_No_Actl_UB 1;
BA_ "U_CD542_MY2021_Rx" SG_ 1080 DrLatchCntFl_No_Actl_UB 1;
BA_ "U_U55X_MY2022_Rx" SG_ 1080 DrLatchCntFl_No_Actl_UB 1;
BA_ "U_CD764_MY2022_Rx" SG_ 1080 DrLatchCntFl_No_Actl_UB 1;
BA_ "U_CX727_MY2021_Rx" SG_ 1080 DrLatchRr_B_Falt 1;
BA_ "U_P702_MY2021_Rx" SG_ 1080 DrLatchRr_B_Falt 1;
BA_ "U_T6_MCA_MY2020_Rx" SG_ 1080 DrLatchRr_B_Falt 1;
BA_ "U_CX727_MY2021_Rx" SG_ 1080 DrLatchRl_B_Falt 1;
BA_ "U_P702_MY2021_Rx" SG_ 1080 DrLatchRl_B_Falt 1;
BA_ "U_T6_MCA_MY2020_Rx" SG_ 1080 DrLatchRl_B_Falt 1;
BA_ "U_CX727_MY2021_Rx" SG_ 1080 DrLatchLckRr_B_Stat 1;
BA_ "U_P702_MY2021_Rx" SG_ 1080 DrLatchLckRr_B_Stat 1;
BA_ "U_T6_MCA_MY2020_Rx" SG_ 1080 DrLatchLckRr_B_Stat 1;
BA_ "U_CX727_MY2021_Rx" SG_ 1080 DrLatchLckRl_B_Stat 1;
BA_ "U_P702_MY2021_Rx" SG_ 1080 DrLatchLckRl_B_Stat 1;
BA_ "U_T6_MCA_MY2020_Rx" SG_ 1080 DrLatchLckRl_B_Stat 1;
BA_ "U_CX727_MY2021_Rx" SG_ 1080 DrLatchLckFr_B_Stat 1;
BA_ "U_P702_MY2021_Rx" SG_ 1080 DrLatchLckFr_B_Stat 1;
BA_ "U_T6_MCA_MY2020_Rx" SG_ 1080 DrLatchLckFr_B_Stat 1;
BA_ "U_CD542_MY2021_Rx" SG_ 1080 DrLatchLckFr_B_Stat 1;
BA_ "U_U55X_MY2022_Rx" SG_ 1080 DrLatchLckFr_B_Stat 1;
BA_ "U_CD764_MY2022_Rx" SG_ 1080 DrLatchLckFr_B_Stat 1;
BA_ "U_CX727_MY2021_Rx" SG_ 1080 DrLatchLckFl_B_Stat 1;
BA_ "U_P702_MY2021_Rx" SG_ 1080 DrLatchLckFl_B_Stat 1;
BA_ "U_T6_MCA_MY2020_Rx" SG_ 1080 DrLatchLckFl_B_Stat 1;
BA_ "U_CD542_MY2021_Rx" SG_ 1080 DrLatchLckFl_B_Stat 1;
BA_ "U_U55X_MY2022_Rx" SG_ 1080 DrLatchLckFl_B_Stat 1;
BA_ "U_CD764_MY2022_Rx" SG_ 1080 DrLatchLckFl_B_Stat 1;
BA_ "U_CX727_MY2021_Rx" SG_ 1080 DrLatchFr_B_Falt 1;
BA_ "U_P702_MY2021_Rx" SG_ 1080 DrLatchFr_B_Falt 1;
BA_ "U_T6_MCA_MY2020_Rx" SG_ 1080 DrLatchFr_B_Falt 1;
BA_ "U_CD542_MY2021_Rx" SG_ 1080 DrLatchFr_B_Falt 1;
BA_ "U_U55X_MY2022_Rx" SG_ 1080 DrLatchFr_B_Falt 1;
BA_ "U_CD764_MY2022_Rx" SG_ 1080 DrLatchFr_B_Falt 1;
BA_ "U_CX727_MY2021_Rx" SG_ 1080 DrLatchFl_B_Falt 1;
BA_ "U_P702_MY2021_Rx" SG_ 1080 DrLatchFl_B_Falt 1;
BA_ "U_T6_MCA_MY2020_Rx" SG_ 1080 DrLatchFl_B_Falt 1;
BA_ "U_CD542_MY2021_Rx" SG_ 1080 DrLatchFl_B_Falt 1;
BA_ "U_U55X_MY2022_Rx" SG_ 1080 DrLatchFl_B_Falt 1;
BA_ "U_CD764_MY2022_Rx" SG_ 1080 DrLatchFl_B_Falt 1;
BA_ "U_CX727_MY2021_Rx" SG_ 1080 DrLatchCntRr_No_Actl 1;
BA_ "U_P702_MY2021_Rx" SG_ 1080 DrLatchCntRr_No_Actl 1;
BA_ "U_T6_MCA_MY2020_Rx" SG_ 1080 DrLatchCntRr_No_Actl 1;
BA_ "U_CX727_MY2021_Rx" SG_ 1080 DrLatchCntRl_No_Actl 1;
BA_ "U_P702_MY2021_Rx" SG_ 1080 DrLatchCntRl_No_Actl 1;
BA_ "U_T6_MCA_MY2020_Rx" SG_ 1080 DrLatchCntRl_No_Actl 1;
BA_ "U_CX727_MY2021_Rx" SG_ 1080 DrLatchCntFr_No_Actl 1;
BA_ "U_P702_MY2021_Rx" SG_ 1080 DrLatchCntFr_No_Actl 1;
BA_ "U_T6_MCA_MY2020_Rx" SG_ 1080 DrLatchCntFr_No_Actl 1;
BA_ "U_CD542_MY2021_Rx" SG_ 1080 DrLatchCntFr_No_Actl 1;
BA_ "U_U55X_MY2022_Rx" SG_ 1080 DrLatchCntFr_No_Actl 1;
BA_ "U_CD764_MY2022_Rx" SG_ 1080 DrLatchCntFr_No_Actl 1;
BA_ "U_CX727_MY2021_Rx" SG_ 1080 DrLatchCntFl_No_Actl 1;
BA_ "U_P702_MY2021_Rx" SG_ 1080 DrLatchCntFl_No_Actl 1;
BA_ "U_T6_MCA_MY2020_Rx" SG_ 1080 DrLatchCntFl_No_Actl 1;
BA_ "U_CD542_MY2021_Rx" SG_ 1080 DrLatchCntFl_No_Actl 1;
BA_ "U_U55X_MY2022_Rx" SG_ 1080 DrLatchCntFl_No_Actl 1;
BA_ "U_CD764_MY2022_Rx" SG_ 1080 DrLatchCntFl_No_Actl 1;
BA_ "U_U55X_MY2022_Rx" SG_ 1080 TurnLghtSwtch_D_Stat2_UB 1;
BA_ "GenSigSendType" SG_ 1080 TurnLghtSwtch_D_Stat2 3;
BA_ "U_U55X_MY2022_Rx" SG_ 1080 TurnLghtSwtch_D_Stat2 1;
BA_ "U_CX727_MY2021_Rx" SG_ 1080 CabnAmb_Te_Actl_UB 1;
BA_ "U_T6_MCA_MY2020_Rx" SG_ 1080 CabnAmb_Te_Actl_UB 1;
BA_ "U_CD542_MY2021_Rx" SG_ 1080 CabnAmb_Te_Actl_UB 1;
BA_ "U_U55X_MY2022_Rx" SG_ 1080 CabnAmb_Te_Actl_UB 1;
BA_ "U_CD764_MY2022_Rx" SG_ 1080 CabnAmb_Te_Actl_UB 1;
BA_ "GenSigStartValueInteger" SG_ 1080 CabnAmb_Te_Actl 114;
BA_ "U_CX727_MY2021_Rx" SG_ 1080 CabnAmb_Te_Actl 1;
BA_ "U_T6_MCA_MY2020_Rx" SG_ 1080 CabnAmb_Te_Actl 1;
BA_ "U_CD542_MY2021_Rx" SG_ 1080 CabnAmb_Te_Actl 1;
BA_ "U_U55X_MY2022_Rx" SG_ 1080 CabnAmb_Te_Actl 1;
BA_ "U_CD764_MY2022_Rx" SG_ 1080 CabnAmb_Te_Actl 1;
BA_ "U_CX727_MY2021_Rx" SG_ 1080 HeadLghtHiPrmsn_D_Stat_UB 1;
BA_ "U_P702_MY2021_Rx" SG_ 1080 HeadLghtHiPrmsn_D_Stat_UB 1;
BA_ "U_T6_MCA_MY2020_Rx" SG_ 1080 HeadLghtHiPrmsn_D_Stat_UB 1;
BA_ "U_CD542_MY2021_Rx" SG_ 1080 HeadLghtHiPrmsn_D_Stat_UB 1;
BA_ "U_U55X_MY2022_Rx" SG_ 1080 HeadLghtHiPrmsn_D_Stat_UB 1;
BA_ "U_CD764_MY2022_Rx" SG_ 1080 HeadLghtHiPrmsn_D_Stat_UB 1;
BA_ "GenSigStartValueInteger" SG_ 1080 HeadLghtHiPrmsn_D_Stat 3;
BA_ "GenSigStartValue" SG_ 1080 HeadLghtHiPrmsn_D_Stat 3;
BA_ "GenSigSendType" SG_ 1080 HeadLghtHiPrmsn_D_Stat 3;
BA_ "U_CX727_MY2021_Rx" SG_ 1080 HeadLghtHiPrmsn_D_Stat 1;
BA_ "U_P702_MY2021_Rx" SG_ 1080 HeadLghtHiPrmsn_D_Stat 1;
BA_ "U_T6_MCA_MY2020_Rx" SG_ 1080 HeadLghtHiPrmsn_D_Stat 1;
BA_ "U_CD542_MY2021_Rx" SG_ 1080 HeadLghtHiPrmsn_D_Stat 1;
BA_ "U_U55X_MY2022_Rx" SG_ 1080 HeadLghtHiPrmsn_D_Stat 1;
BA_ "U_CD764_MY2022_Rx" SG_ 1080 HeadLghtHiPrmsn_D_Stat 1;
BA_ "GenSigStartValue" SG_ 1121 OffRdSwtch_D_RqMnu 2;
BA_ "GenSigSendType" SG_ 1121 OffRdSwtch_D_RqMnu 3;
BA_ "GenSigSendType" SG_ 1121 SelDrvMdeSwtchOk_D_Stat 3;
BA_ "U_U55X_MY2022_Tx" SG_ 1121 SelDrvMdeSwtchOk_D_Stat 1;
BA_ "GenSigSendType" SG_ 1121 AutoHoldSwtch_D_Stat2 3;
BA_ "U_T6_MCA_MY2020_Tx" SG_ 1121 AutoHoldSwtch_D_Stat2 1;
BA_ "U_U55X_MY2022_Tx" SG_ 1121 AutoHoldSwtch_D_Stat2 1;
BA_ "GenSigSendType" SG_ 1121 PrkAidSwtch_D_RqDrv3 3;
BA_ "U_T6_MCA_MY2020_Tx" SG_ 1121 PrkAidSwtch_D_RqDrv3 1;
BA_ "U_U55X_MY2022_Tx" SG_ 1121 PrkAidSwtch_D_RqDrv3 1;
BA_ "GenSigSendType" SG_ 1121 ApaSwtch_D_RqDrv3 3;
BA_ "U_T6_MCA_MY2020_Tx" SG_ 1121 ApaSwtch_D_RqDrv3 1;
BA_ "U_U55X_MY2022_Tx" SG_ 1121 ApaSwtch_D_RqDrv3 1;
BA_ "GenSigSendType" SG_ 1121 StopStrtDrvMde_B_RqBtn2 3;
BA_ "U_T6_MCA_MY2020_Tx" SG_ 1121 StopStrtDrvMde_B_RqBtn2 1;
BA_ "U_U55X_MY2022_Tx" SG_ 1121 StopStrtDrvMde_B_RqBtn2 1;
BA_ "GenSigSendType" SG_ 1121 SelDrvMdeSwtch_No_Actl 3;
BA_ "U_P702_MY2021_Tx" SG_ 1121 SelDrvMdeSwtch_No_Actl 1;
BA_ "U_T6_MCA_MY2020_Tx" SG_ 1121 SelDrvMdeSwtch_No_Actl 1;
BA_ "U_U55X_MY2022_Tx" SG_ 1121 SelDrvMdeSwtch_No_Actl 1;
BA_ "GenSigSendType" SG_ 1121 SelDrvMdeSwtch_D_Stat 3;
BA_ "U_P702_MY2021_Tx" SG_ 1121 SelDrvMdeSwtch_D_Stat 1;
BA_ "U_T6_MCA_MY2020_Tx" SG_ 1121 SelDrvMdeSwtch_D_Stat 1;
BA_ "U_U55X_MY2022_Tx" SG_ 1121 SelDrvMdeSwtch_D_Stat 1;
BA_ "GenSigSendType" SG_ 1121 SelDrvMdeCnt_D_Stat 3;
BA_ "U_P702_MY2021_Tx" SG_ 1121 SelDrvMdeCnt_D_Stat 1;
BA_ "U_T6_MCA_MY2020_Tx" SG_ 1121 SelDrvMdeCnt_D_Stat 1;
BA_ "U_U55X_MY2022_Tx" SG_ 1121 SelDrvMdeCnt_D_Stat 1;
BA_ "GenSigSendType" SG_ 673 ICI_Coding_BtnID_D 3;
BA_ "U_CX727_MY2021_Tx" SG_ 673 ICI_Coding_BtnID_D 1;
BA_ "U_P702_MY2021_Tx" SG_ 673 ICI_Coding_BtnID_D 1;
BA_ "U_T6_MCA_MY2020_Tx" SG_ 673 ICI_Coding_BtnID_D 1;
BA_ "U_CD542_MY2021_Tx" SG_ 673 ICI_Coding_BtnID_D 1;
BA_ "U_U55X_MY2022_Tx" SG_ 673 ICI_Coding_BtnID_D 1;
BA_ "U_CD764_MY2022_Tx" SG_ 673 ICI_Coding_BtnID_D 1;
BA_ "GenSigSendType" SG_ 673 ICI_Coding_BtnID_C 3;
BA_ "U_CX727_MY2021_Tx" SG_ 673 ICI_Coding_BtnID_C 1;
BA_ "U_P702_MY2021_Tx" SG_ 673 ICI_Coding_BtnID_C 1;
BA_ "U_T6_MCA_MY2020_Tx" SG_ 673 ICI_Coding_BtnID_C 1;
BA_ "U_CD542_MY2021_Tx" SG_ 673 ICI_Coding_BtnID_C 1;
BA_ "U_U55X_MY2022_Tx" SG_ 673 ICI_Coding_BtnID_C 1;
BA_ "U_CD764_MY2022_Tx" SG_ 673 ICI_Coding_BtnID_C 1;
BA_ "GenSigSendType" SG_ 673 ICI_Coding_BtnID_B 3;
BA_ "U_CX727_MY2021_Tx" SG_ 673 ICI_Coding_BtnID_B 1;
BA_ "U_P702_MY2021_Tx" SG_ 673 ICI_Coding_BtnID_B 1;
BA_ "U_T6_MCA_MY2020_Tx" SG_ 673 ICI_Coding_BtnID_B 1;
BA_ "U_CD542_MY2021_Tx" SG_ 673 ICI_Coding_BtnID_B 1;
BA_ "U_U55X_MY2022_Tx" SG_ 673 ICI_Coding_BtnID_B 1;
BA_ "U_CD764_MY2022_Tx" SG_ 673 ICI_Coding_BtnID_B 1;
BA_ "GenSigSendType" SG_ 673 ICI_Coding_BtnID_A 3;
BA_ "U_CX727_MY2021_Tx" SG_ 673 ICI_Coding_BtnID_A 1;
BA_ "U_P702_MY2021_Tx" SG_ 673 ICI_Coding_BtnID_A 1;
BA_ "U_T6_MCA_MY2020_Tx" SG_ 673 ICI_Coding_BtnID_A 1;
BA_ "U_CD542_MY2021_Tx" SG_ 673 ICI_Coding_BtnID_A 1;
BA_ "U_U55X_MY2022_Tx" SG_ 673 ICI_Coding_BtnID_A 1;
BA_ "U_CD764_MY2022_Tx" SG_ 673 ICI_Coding_BtnID_A 1;
BA_ "GenSigStartValueInteger" SG_ 673 ICI_BtnID_D 255;
BA_ "GenSigStartValue" SG_ 673 ICI_BtnID_D 255;
BA_ "GenSigSendType" SG_ 673 ICI_BtnID_D 3;
BA_ "U_CX727_MY2021_Tx" SG_ 673 ICI_BtnID_D 1;
BA_ "U_P702_MY2021_Tx" SG_ 673 ICI_BtnID_D 1;
BA_ "U_T6_MCA_MY2020_Tx" SG_ 673 ICI_BtnID_D 1;
BA_ "U_CD542_MY2021_Tx" SG_ 673 ICI_BtnID_D 1;
BA_ "U_U55X_MY2022_Tx" SG_ 673 ICI_BtnID_D 1;
BA_ "U_CD764_MY2022_Tx" SG_ 673 ICI_BtnID_D 1;
BA_ "GenSigStartValueInteger" SG_ 673 ICI_BtnID_C 255;
BA_ "GenSigStartValue" SG_ 673 ICI_BtnID_C 255;
BA_ "GenSigSendType" SG_ 673 ICI_BtnID_C 3;
BA_ "U_CX727_MY2021_Tx" SG_ 673 ICI_BtnID_C 1;
BA_ "U_P702_MY2021_Tx" SG_ 673 ICI_BtnID_C 1;
BA_ "U_T6_MCA_MY2020_Tx" SG_ 673 ICI_BtnID_C 1;
BA_ "U_CD542_MY2021_Tx" SG_ 673 ICI_BtnID_C 1;
BA_ "U_U55X_MY2022_Tx" SG_ 673 ICI_BtnID_C 1;
BA_ "U_CD764_MY2022_Tx" SG_ 673 ICI_BtnID_C 1;
BA_ "GenSigStartValueInteger" SG_ 673 ICI_BtnID_B 255;
BA_ "GenSigStartValue" SG_ 673 ICI_BtnID_B 255;
BA_ "GenSigSendType" SG_ 673 ICI_BtnID_B 3;
BA_ "U_CX727_MY2021_Tx" SG_ 673 ICI_BtnID_B 1;
BA_ "U_P702_MY2021_Tx" SG_ 673 ICI_BtnID_B 1;
BA_ "U_T6_MCA_MY2020_Tx" SG_ 673 ICI_BtnID_B 1;
BA_ "U_CD542_MY2021_Tx" SG_ 673 ICI_BtnID_B 1;
BA_ "U_U55X_MY2022_Tx" SG_ 673 ICI_BtnID_B 1;
BA_ "U_CD764_MY2022_Tx" SG_ 673 ICI_BtnID_B 1;
BA_ "GenSigStartValueInteger" SG_ 673 ICI_BtnID_A 255;
BA_ "GenSigStartValue" SG_ 673 ICI_BtnID_A 255;
BA_ "GenSigSendType" SG_ 673 ICI_BtnID_A 3;
BA_ "U_CX727_MY2021_Tx" SG_ 673 ICI_BtnID_A 1;
BA_ "U_P702_MY2021_Tx" SG_ 673 ICI_BtnID_A 1;
BA_ "U_T6_MCA_MY2020_Tx" SG_ 673 ICI_BtnID_A 1;
BA_ "U_CD542_MY2021_Tx" SG_ 673 ICI_BtnID_A 1;
BA_ "U_U55X_MY2022_Tx" SG_ 673 ICI_BtnID_A 1;
BA_ "U_CD764_MY2022_Tx" SG_ 673 ICI_BtnID_A 1;
BA_ "U_U55X_MY2022_Rx" SG_ 845 SeatMasgPsngr_D_Stat 1;
BA_ "U_U55X_MY2022_Rx" SG_ 845 SeatIntnsPsngr_D_Stat 1;
BA_ "U_P702_MY2021_Rx" SG_ 845 StmsLmbrPsgr_D_Stat 1;
BA_ "U_U55X_MY2022_Rx" SG_ 845 StmsLmbrPsgr_D_Stat 1;
BA_ "U_P702_MY2021_Rx" SG_ 845 StmsCshnPsgr_D_Stat 1;
BA_ "U_U55X_MY2022_Rx" SG_ 845 StmsCshnPsgr_D_Stat 1;
BA_ "U_P702_MY2021_Rx" SG_ 845 SeatSwtchPsgr_B_Stat 1;
BA_ "U_U55X_MY2022_Rx" SG_ 845 SeatSwtchPsgr_B_Stat 1;
BA_ "U_P702_MY2021_Rx" SG_ 845 SeatPPsgr_B_Stat 1;
BA_ "U_U55X_MY2022_Rx" SG_ 845 SeatPPsgr_B_Stat 1;
BA_ "U_P702_MY2021_Rx" SG_ 845 SeatFnPsgr_D_Stat 1;
BA_ "U_U55X_MY2022_Rx" SG_ 845 SeatFnPsgr_D_Stat 1;
BA_ "GenSigStartValueInteger" SG_ 850 SeatCshnPsgrRR_Pc_Actl 127;
BA_ "GenSigStartValue" SG_ 850 SeatCshnPsgrRR_Pc_Actl 127;
BA_ "U_P702_MY2021_Rx" SG_ 850 SeatCshnPsgrRR_Pc_Actl 1;
BA_ "U_U55X_MY2022_Rx" SG_ 850 SeatCshnPsgrRR_Pc_Actl 1;
BA_ "GenSigStartValueInteger" SG_ 850 SeatCshnPsgrRL_Pc_Actl 127;
BA_ "GenSigStartValue" SG_ 850 SeatCshnPsgrRL_Pc_Actl 127;
BA_ "U_P702_MY2021_Rx" SG_ 850 SeatCshnPsgrRL_Pc_Actl 1;
BA_ "U_U55X_MY2022_Rx" SG_ 850 SeatCshnPsgrRL_Pc_Actl 1;
BA_ "GenSigStartValueInteger" SG_ 850 SeatCshnPsgrFR_Pc_Actl 127;
BA_ "GenSigStartValue" SG_ 850 SeatCshnPsgrFR_Pc_Actl 127;
BA_ "U_P702_MY2021_Rx" SG_ 850 SeatCshnPsgrFR_Pc_Actl 1;
BA_ "U_U55X_MY2022_Rx" SG_ 850 SeatCshnPsgrFR_Pc_Actl 1;
BA_ "GenSigStartValueInteger" SG_ 850 SeatCshnPsgrFL_Pc_Actl 127;
BA_ "GenSigStartValue" SG_ 850 SeatCshnPsgrFL_Pc_Actl 127;
BA_ "U_P702_MY2021_Rx" SG_ 850 SeatCshnPsgrFL_Pc_Actl 1;
BA_ "U_U55X_MY2022_Rx" SG_ 850 SeatCshnPsgrFL_Pc_Actl 1;
BA_ "GenSigStartValueInteger" SG_ 850 SeatBlLoPsgr_Pc_Actl2 127;
BA_ "GenSigStartValue" SG_ 850 SeatBlLoPsgr_Pc_Actl2 127;
BA_ "U_P702_MY2021_Rx" SG_ 850 SeatBlLoPsgr_Pc_Actl2 1;
BA_ "U_U55X_MY2022_Rx" SG_ 850 SeatBlLoPsgr_Pc_Actl2 1;
BA_ "GenSigSendType" SG_ 820 TurnLampFrOut_B_Stat 3;
BA_ "GenSigSendType" SG_ 820 TurnLampFlOut_B_Stat 3;
BA_ "GenSigSendType" SG_ 820 AhbStatGfhbFdbk_D_Actl 3;
BA_ "U_T6_MCA_MY2020_Rx" SG_ 820 AhbStatGfhbFdbk_D_Actl 1;
BA_ "U_CX727_MY2021_Rx" SG_ 820 AhbStatGfhbFdbk_D_Actl 1;
BA_ "U_P702_MY2021_Rx" SG_ 820 AhbStatGfhbFdbk_D_Actl 1;
BA_ "U_CD542_MY2021_Rx" SG_ 820 AhbStatGfhbFdbk_D_Actl 1;
BA_ "U_U55X_MY2022_Rx" SG_ 820 AhbStatGfhbFdbk_D_Actl 1;
BA_ "U_CD764_MY2022_Rx" SG_ 820 AhbStatGfhbFdbk_D_Actl 1;
BA_ "U_CX727_MY2021_Tx" SG_ 820 AhbStatGfhbFdbk_D_Actl 1;
BA_ "U_P702_MY2021_Tx" SG_ 820 AhbStatGfhbFdbk_D_Actl 1;
BA_ "U_T6_MCA_MY2020_Tx" SG_ 820 AhbStatGfhbFdbk_D_Actl 1;
BA_ "U_CD542_MY2021_Tx" SG_ 820 AhbStatGfhbFdbk_D_Actl 1;
BA_ "GenSigSendType" SG_ 820 HeadLghtDrvSide_B_Stat 3;
BA_ "U_CX727_MY2021_Tx" SG_ 820 HeadLghtDrvSide_B_Stat 1;
BA_ "U_P702_MY2021_Tx" SG_ 820 HeadLghtDrvSide_B_Stat 1;
BA_ "U_T6_MCA_MY2020_Tx" SG_ 820 HeadLghtDrvSide_B_Stat 1;
BA_ "U_CD542_MY2021_Tx" SG_ 820 HeadLghtDrvSide_B_Stat 1;
BA_ "GenSigSendType" SG_ 820 HeadLghtHiOn_B_StatHcm 3;
BA_ "U_CX727_MY2021_Tx" SG_ 820 HeadLghtHiOn_B_StatHcm 1;
BA_ "U_P702_MY2021_Tx" SG_ 820 HeadLghtHiOn_B_StatHcm 1;
BA_ "U_T6_MCA_MY2020_Tx" SG_ 820 HeadLghtHiOn_B_StatHcm 1;
BA_ "U_CD542_MY2021_Tx" SG_ 820 HeadLghtHiOn_B_StatHcm 1;
BA_ "GenSigSendType" SG_ 820 Adaptive_Hdlmp_Fault 3;
BA_ "U_CX727_MY2021_Tx" SG_ 820 Adaptive_Hdlmp_Fault 1;
BA_ "U_P702_MY2021_Tx" SG_ 820 Adaptive_Hdlmp_Fault 1;
BA_ "U_T6_MCA_MY2020_Tx" SG_ 820 Adaptive_Hdlmp_Fault 1;
BA_ "U_CD542_MY2021_Tx" SG_ 820 Adaptive_Hdlmp_Fault 1;
BA_ "GenSigStartValueInteger" SG_ 935 Side_Detect_R_Illum 100;
BA_ "GenSigStartValue" SG_ 935 Side_Detect_R_Illum 100;
BA_ "GenSigStartValueInteger" SG_ 935 SodRight_D_Stat 2;
BA_ "GenSigStartValue" SG_ 935 SodRight_D_Stat 2;
BA_ "GenSigStartValueInteger" SG_ 935 SodWarnRight_Prd_Rq 14;
BA_ "GenSigStartValue" SG_ 935 SodWarnRight_Prd_Rq 14;
BA_ "GenSigStartValueInteger" SG_ 934 Side_Detect_L_Illum 100;
BA_ "GenSigStartValue" SG_ 934 Side_Detect_L_Illum 100;
BA_ "GenSigStartValueInteger" SG_ 934 SodLeft_D_Stat 2;
BA_ "GenSigStartValue" SG_ 934 SodLeft_D_Stat 2;
BA_ "GenSigStartValueInteger" SG_ 934 SodWarnLeft_Prd_Rq 14;
BA_ "GenSigStartValue" SG_ 934 SodWarnLeft_Prd_Rq 14;
BA_ "GenSigSendType" SG_ 1073 CamraFrntBttn_D_Stat 3;
BA_ "GenSigSendType" SG_ 1073 BrkDrvMde_D_Rq 3;
BA_ "GenSigSendType" SG_ 1073 SteEffort_D_Rq 3;
BA_ "GenSigSendType" SG_ 1073 AutoHoldSwtch_D_Stat 3;
BA_ "U_CX727_MY2021_Rx" SG_ 1073 HMI_HMIMode_St_UB 1;
BA_ "U_P702_MY2021_Rx" SG_ 1073 HMI_HMIMode_St_UB 1;
BA_ "U_T6_MCA_MY2020_Rx" SG_ 1073 HMI_HMIMode_St_UB 1;
BA_ "U_CD542_MY2021_Rx" SG_ 1073 HMI_HMIMode_St_UB 1;
BA_ "U_U55X_MY2022_Rx" SG_ 1073 HMI_HMIMode_St_UB 1;
BA_ "U_CD764_MY2022_Rx" SG_ 1073 HMI_HMIMode_St_UB 1;
BA_ "WakeupSignal" SG_ 1073 HMI_HMIMode_St 1;
BA_ "GenSigSendType" SG_ 1073 HMI_HMIMode_St 3;
BA_ "U_CX727_MY2021_Rx" SG_ 1073 HMI_HMIMode_St 1;
BA_ "U_P702_MY2021_Rx" SG_ 1073 HMI_HMIMode_St 1;
BA_ "U_T6_MCA_MY2020_Rx" SG_ 1073 HMI_HMIMode_St 1;
BA_ "U_CD542_MY2021_Rx" SG_ 1073 HMI_HMIMode_St 1;
BA_ "U_U55X_MY2022_Rx" SG_ 1073 HMI_HMIMode_St 1;
BA_ "U_CD764_MY2022_Rx" SG_ 1073 HMI_HMIMode_St 1;
BA_ "U_CX727_MY2021_Rx" SG_ 1073 Veh_Lock_Requestor_UB 1;
BA_ "U_P702_MY2021_Rx" SG_ 1073 Veh_Lock_Requestor_UB 1;
BA_ "U_T6_MCA_MY2020_Rx" SG_ 1073 Veh_Lock_Requestor_UB 1;
BA_ "U_CD542_MY2021_Rx" SG_ 1073 Veh_Lock_Requestor_UB 1;
BA_ "U_U55X_MY2022_Rx" SG_ 1073 Veh_Lock_Requestor_UB 1;
BA_ "U_CD764_MY2022_Rx" SG_ 1073 Veh_Lock_Requestor_UB 1;
BA_ "U_CX727_MY2021_Rx" SG_ 1073 Veh_Lock_EvNum_UB 1;
BA_ "U_P702_MY2021_Rx" SG_ 1073 Veh_Lock_EvNum_UB 1;
BA_ "U_T6_MCA_MY2020_Rx" SG_ 1073 Veh_Lock_EvNum_UB 1;
BA_ "U_CD542_MY2021_Rx" SG_ 1073 Veh_Lock_EvNum_UB 1;
BA_ "U_U55X_MY2022_Rx" SG_ 1073 Veh_Lock_EvNum_UB 1;
BA_ "U_CD764_MY2022_Rx" SG_ 1073 Veh_Lock_EvNum_UB 1;
BA_ "U_CX727_MY2021_Rx" SG_ 1073 Veh_Lock_Status_UB 1;
BA_ "U_P702_MY2021_Rx" SG_ 1073 Veh_Lock_Status_UB 1;
BA_ "U_T6_MCA_MY2020_Rx" SG_ 1073 Veh_Lock_Status_UB 1;
BA_ "U_CD542_MY2021_Rx" SG_ 1073 Veh_Lock_Status_UB 1;
BA_ "U_U55X_MY2022_Rx" SG_ 1073 Veh_Lock_Status_UB 1;
BA_ "U_CD764_MY2022_Rx" SG_ 1073 Veh_Lock_Status_UB 1;
BA_ "GenSigSendType" SG_ 1073 Veh_Lock_Sub_Id 3;
BA_ "WakeupSignal" SG_ 1073 Veh_Lock_Status 1;
BA_ "GenSigStartValueInteger" SG_ 1073 Veh_Lock_Status 1;
BA_ "GenSigStartValue" SG_ 1073 Veh_Lock_Status 1;
BA_ "GenSigSendType" SG_ 1073 Veh_Lock_Status 3;
BA_ "U_CX727_MY2021_Rx" SG_ 1073 Veh_Lock_Status 1;
BA_ "U_P702_MY2021_Rx" SG_ 1073 Veh_Lock_Status 1;
BA_ "U_T6_MCA_MY2020_Rx" SG_ 1073 Veh_Lock_Status 1;
BA_ "U_CD542_MY2021_Rx" SG_ 1073 Veh_Lock_Status 1;
BA_ "U_U55X_MY2022_Rx" SG_ 1073 Veh_Lock_Status 1;
BA_ "U_CD764_MY2022_Rx" SG_ 1073 Veh_Lock_Status 1;
BA_ "WakeupSignal" SG_ 1073 Veh_Lock_Requestor 1;
BA_ "GenSigSendType" SG_ 1073 Veh_Lock_Requestor 3;
BA_ "U_CX727_MY2021_Rx" SG_ 1073 Veh_Lock_Requestor 1;
BA_ "U_P702_MY2021_Rx" SG_ 1073 Veh_Lock_Requestor 1;
BA_ "U_T6_MCA_MY2020_Rx" SG_ 1073 Veh_Lock_Requestor 1;
BA_ "U_CD542_MY2021_Rx" SG_ 1073 Veh_Lock_Requestor 1;
BA_ "U_U55X_MY2022_Rx" SG_ 1073 Veh_Lock_Requestor 1;
BA_ "U_CD764_MY2022_Rx" SG_ 1073 Veh_Lock_Requestor 1;
BA_ "WakeupSignal" SG_ 1073 Veh_Lock_EvNum 1;
BA_ "GenSigSendType" SG_ 1073 Veh_Lock_EvNum 3;
BA_ "U_CX727_MY2021_Rx" SG_ 1073 Veh_Lock_EvNum 1;
BA_ "U_P702_MY2021_Rx" SG_ 1073 Veh_Lock_EvNum 1;
BA_ "U_T6_MCA_MY2020_Rx" SG_ 1073 Veh_Lock_EvNum 1;
BA_ "U_CD542_MY2021_Rx" SG_ 1073 Veh_Lock_EvNum 1;
BA_ "U_U55X_MY2022_Rx" SG_ 1073 Veh_Lock_EvNum 1;
BA_ "U_CD764_MY2022_Rx" SG_ 1073 Veh_Lock_EvNum 1;
BA_ "GenSigSendType" SG_ 1073 Tire_Press_System_Stat 3;
BA_ "U_CX727_MY2021_Rx" SG_ 1073 DISPLAY_SPEED_OFFSET_UB 1;
BA_ "U_P702_MY2021_Rx" SG_ 1073 DISPLAY_SPEED_OFFSET_UB 1;
BA_ "U_T6_MCA_MY2020_Rx" SG_ 1073 DISPLAY_SPEED_OFFSET_UB 1;
BA_ "GenSigSendType" SG_ 1073 DISPLAY_SPEED_OFFSET 3;
BA_ "U_CX727_MY2021_Rx" SG_ 1073 DISPLAY_SPEED_OFFSET 1;
BA_ "U_P702_MY2021_Rx" SG_ 1073 DISPLAY_SPEED_OFFSET 1;
BA_ "U_T6_MCA_MY2020_Rx" SG_ 1073 DISPLAY_SPEED_OFFSET 1;
BA_ "U_CX727_MY2021_Rx" SG_ 1073 DISPLAY_SPEED_SCALING_UB 1;
BA_ "U_P702_MY2021_Rx" SG_ 1073 DISPLAY_SPEED_SCALING_UB 1;
BA_ "U_T6_MCA_MY2020_Rx" SG_ 1073 DISPLAY_SPEED_SCALING_UB 1;
BA_ "GenSigSendType" SG_ 1073 DISPLAY_SPEED_SCALING 3;
BA_ "U_CX727_MY2021_Rx" SG_ 1073 DISPLAY_SPEED_SCALING 1;
BA_ "U_P702_MY2021_Rx" SG_ 1073 DISPLAY_SPEED_SCALING 1;
BA_ "U_T6_MCA_MY2020_Rx" SG_ 1073 DISPLAY_SPEED_SCALING 1;
BA_ "WakeupSignal" SG_ 1073 Foh_D_Stat 1;
BA_ "ContentDependant" SG_ 1073 Foh_D_Stat 1;
BA_ "GenSigSendType" SG_ 1073 Foh_D_Stat 3;
BA_ "U_P702_MY2021_Rx" SG_ 1073 Foh_D_Stat 1;
BA_ "U_T6_MCA_MY2020_Rx" SG_ 1073 Foh_D_Stat 1;
BA_ "U_CD542_MY2021_Rx" SG_ 1073 Foh_D_Stat 1;
BA_ "U_U55X_MY2022_Rx" SG_ 1073 Foh_D_Stat 1;
BA_ "U_CD764_MY2022_Rx" SG_ 1073 Foh_D_Stat 1;
BA_ "U_P702_MY2021_Rx" SG_ 1073 Foh_D_Stat_UB 1;
BA_ "U_T6_MCA_MY2020_Rx" SG_ 1073 Foh_D_Stat_UB 1;
BA_ "U_CD542_MY2021_Rx" SG_ 1073 Foh_D_Stat_UB 1;
BA_ "U_U55X_MY2022_Rx" SG_ 1073 Foh_D_Stat_UB 1;
BA_ "U_CD764_MY2022_Rx" SG_ 1073 Foh_D_Stat_UB 1;
BA_ "U_P702_MY2021_Rx" SG_ 1073 SteWhlHeat_D_Rq_UB 1;
BA_ "U_CX727_MY2021_Rx" SG_ 1073 SteWhlHeat_D_Rq_UB 1;
BA_ "U_T6_MCA_MY2020_Rx" SG_ 1073 SteWhlHeat_D_Rq_UB 1;
BA_ "U_CD542_MY2021_Rx" SG_ 1073 SteWhlHeat_D_Rq_UB 1;
BA_ "U_U55X_MY2022_Rx" SG_ 1073 SteWhlHeat_D_Rq_UB 1;
BA_ "U_CD764_MY2022_Rx" SG_ 1073 SteWhlHeat_D_Rq_UB 1;
BA_ "GenSigSendType" SG_ 1073 SteWhlHeat_D_Rq 3;
BA_ "U_P702_MY2021_Rx" SG_ 1073 SteWhlHeat_D_Rq 1;
BA_ "U_CX727_MY2021_Rx" SG_ 1073 SteWhlHeat_D_Rq 1;
BA_ "U_T6_MCA_MY2020_Rx" SG_ 1073 SteWhlHeat_D_Rq 1;
BA_ "U_CD542_MY2021_Rx" SG_ 1073 SteWhlHeat_D_Rq 1;
BA_ "U_U55X_MY2022_Rx" SG_ 1073 SteWhlHeat_D_Rq 1;
BA_ "U_CD764_MY2022_Rx" SG_ 1073 SteWhlHeat_D_Rq 1;
BA_ "ContentDependant" SG_ 1091 PoliceAux4Lamp_B_Rq2 1;
BA_ "ContentDependant" SG_ 1091 PoliceAux3Lamp_B_Rq2 1;
BA_ "ContentDependant" SG_ 1091 PoliceAux2Lamp_B_Rq2 1;
BA_ "ContentDependant" SG_ 1091 PoliceAux1Lamp_B_Rq2 1;
BA_ "GenSigStartValueInteger" SG_ 1091 WakeAlarm2_T_Rq 32767;
BA_ "GenSigStartValue" SG_ 1091 WakeAlarm2_T_Rq 32767;
BA_ "U_P702_MY2021_Rx" SG_ 1091 TrlrLampCnnct_B_Actl 1;
BA_ "U_T6_MCA_MY2020_Rx" SG_ 1091 TrlrLampCnnct_B_Actl 1;
BA_ "U_CX727_MY2021_Rx" SG_ 1091 TrlrLampCnnct_B_Actl 1;
BA_ "GenSigSendType" SG_ 1068 EngStrtInhbt_B_RqBatt 3;
BA_ "GenSigSendType" SG_ 1068 BattULoChrg_D_Rq 3;
BA_ "WakeupSignal" SG_ 1068 PwSysULoFalt_D_Stat 1;
BA_ "GenSigSendType" SG_ 1068 PwSysULoFalt_D_Stat 3;
BA_ "GenSigSendType" SG_ 1068 Shed_T_Eng_Off_B 3;
BA_ "U_P702_MY2021_Rx" SG_ 1068 Shed_T_Eng_Off_B 1;
BA_ "WakeupSignal" SG_ 1068 Shed_Feature_Group_ID 1;
BA_ "GenSigSendType" SG_ 1068 Shed_Feature_Group_ID 3;
BA_ "U_P702_MY2021_Rx" SG_ 1068 Shed_Feature_Group_ID 1;
BA_ "U_T6_MCA_MY2020_Rx" SG_ 1068 Shed_Feature_Group_ID 1;
BA_ "GenSigSendType" SG_ 1068 Shed_Drain_Eng_Off_B 3;
BA_ "U_P702_MY2021_Rx" SG_ 1068 Shed_Drain_Eng_Off_B 1;
BA_ "WakeupSignal" SG_ 1068 Shed_Level_Req 1;
BA_ "GenSigSendType" SG_ 1068 Shed_Level_Req 3;
BA_ "U_CX727_MY2021_Rx" SG_ 1068 Shed_Level_Req 1;
BA_ "U_P702_MY2021_Rx" SG_ 1068 Shed_Level_Req 1;
BA_ "U_T6_MCA_MY2020_Rx" SG_ 1068 Shed_Level_Req 1;
BA_ "U_CD542_MY2021_Rx" SG_ 1068 Shed_Level_Req 1;
BA_ "U_U55X_MY2022_Rx" SG_ 1068 Shed_Level_Req 1;
BA_ "U_CD764_MY2022_Rx" SG_ 1068 Shed_Level_Req 1;
BA_ "GenSigSendType" SG_ 1068 ChargeMode 3;
BA_ "GenSigSendType" SG_ 1068 IdleSpeedIncrease_El 3;
BA_ "GenSigSendType" SG_ 1068 Batt_Lo_SoC_B 3;
BA_ "GenSigSendType" SG_ 1068 PeriodicElLoad_B_Stat 3;
BA_ "GenSigSendType" SG_ 1068 Batt_Crit_SoC_B 3;
BA_ "U_CX727_MY2021_Rx" SG_ 1068 Batt_Crit_SoC_B 1;
BA_ "U_P702_MY2021_Rx" SG_ 1068 Batt_Crit_SoC_B 1;
BA_ "U_T6_MCA_MY2020_Rx" SG_ 1068 Batt_Crit_SoC_B 1;
BA_ "U_CD542_MY2021_Rx" SG_ 1068 Batt_Crit_SoC_B 1;
BA_ "U_U55X_MY2022_Rx" SG_ 1068 Batt_Crit_SoC_B 1;
BA_ "U_CD764_MY2022_Rx" SG_ 1068 Batt_Crit_SoC_B 1;
BA_ "GenSigSendType" SG_ 1068 ULoRgenTestMde_B_Rq 3;
BA_ "ContentDependant" SG_ 611 AwdStat_D_RqDsply 1;
BA_ "U_U55X_MY2022_Rx" SG_ 611 AwdStat_D_RqDsply 1;
BA_ "U_CD764_MY2022_Rx" SG_ 611 AwdStat_D_RqDsply 1;
BA_ "ContentDependant" SG_ 611 AwdSrvcRqd_B_Rq 1;
BA_ "U_CX727_MY2021_Rx" SG_ 611 AwdSrvcRqd_B_Rq 1;
BA_ "U_P702_MY2021_Rx" SG_ 611 AwdSrvcRqd_B_Rq 1;
BA_ "U_T6_MCA_MY2020_Rx" SG_ 611 AwdSrvcRqd_B_Rq 1;
BA_ "U_U55X_MY2022_Rx" SG_ 611 AwdSrvcRqd_B_Rq 1;
BA_ "U_CD764_MY2022_Rx" SG_ 611 AwdSrvcRqd_B_Rq 1;
BA_ "ContentDependant" SG_ 611 AwdLck_Tq_Rq 1;
BA_ "GenSigStartValueInteger" SG_ 611 TrnAout_Tq_RqMx 8191;
BA_ "GenSigStartValue" SG_ 611 TrnAout_Tq_RqMx 8191;
BA_ "U_P702_MY2021_Rx" SG_ 611 AwdLoLamp_D_RqDsply 1;
BA_ "U_U55X_MY2022_Rx" SG_ 611 AwdLoLamp_D_RqDsply 1;
BA_ "U_T6_MCA_MY2020_Rx" SG_ 611 AwdLoLamp_D_RqDsply 1;
BA_ "U_P702_MY2021_Rx" SG_ 611 AwdHiLamp_D_RqDsply 1;
BA_ "U_U55X_MY2022_Rx" SG_ 611 AwdHiLamp_D_RqDsply 1;
BA_ "U_T6_MCA_MY2020_Rx" SG_ 611 AwdHiLamp_D_RqDsply 1;
BA_ "U_P702_MY2021_Rx" SG_ 611 AwdAutoLamp_D_RqDsply 1;
BA_ "U_U55X_MY2022_Rx" SG_ 611 AwdAutoLamp_D_RqDsply 1;
BA_ "U_T6_MCA_MY2020_Rx" SG_ 611 AwdAutoLamp_D_RqDsply 1;
BA_ "U_P702_MY2021_Rx" SG_ 611 Awd2wdLamp_D_RqDsply 1;
BA_ "U_U55X_MY2022_Rx" SG_ 611 Awd2wdLamp_D_RqDsply 1;
BA_ "U_T6_MCA_MY2020_Rx" SG_ 611 Awd2wdLamp_D_RqDsply 1;
BA_ "GenSigStartValueInteger" SG_ 611 AwdRnge_D_Actl 7;
BA_ "GenSigStartValue" SG_ 611 AwdRnge_D_Actl 7;
BA_ "GenSigStartValueInteger" SG_ 395 HudShifPoint_N_Rq 30;
BA_ "GenSigStartValue" SG_ 395 HudShifPoint_N_Rq 30;
BA_ "GenSigSendType" SG_ 578 PtLatchActv_B_RqBcm 3;
BA_ "GenSigSendType" SG_ 578 PrkLckCtlUnlck_D_Stat 3;
BA_ "GenSigSendType" SG_ 578 PrkLckCtlTow_B_Enbl 3;
BA_ "GenSigSendType" SG_ 578 immoSecureIdleMode 3;
BA_ "U_CX727_MY2021_Rx" SG_ 578 immoSecureIdleMode 1;
BA_ "U_P702_MY2021_Rx" SG_ 578 immoSecureIdleMode 1;
BA_ "U_T6_MCA_MY2020_Rx" SG_ 578 immoSecureIdleMode 1;
BA_ "U_CD542_MY2021_Rx" SG_ 578 immoSecureIdleMode 1;
BA_ "U_U55X_MY2022_Rx" SG_ 578 immoSecureIdleMode 1;
BA_ "U_CD764_MY2022_Rx" SG_ 578 immoSecureIdleMode 1;
BA_ "GenSigSendType" SG_ 578 FuelPumpPwr_D_Stat 3;
BA_ "GenSigStartValueInteger" SG_ 578 BattULo_U_Actl 255;
BA_ "GenSigStartValue" SG_ 578 BattULo_U_Actl 255;
BA_ "U_CX727_MY2021_Rx" SG_ 578 BattULo_U_Actl 1;
BA_ "U_P702_MY2021_Rx" SG_ 578 BattULo_U_Actl 1;
BA_ "U_T6_MCA_MY2020_Rx" SG_ 578 BattULo_U_Actl 1;
BA_ "GenSigSendType" SG_ 578 PrkLckCtl_B_Enbl 3;
BA_ "U_CX727_MY2021_Rx" SG_ 578 PrkLckCtl_B_Enbl 1;
BA_ "U_P702_MY2021_Rx" SG_ 578 PrkLckCtl_B_Enbl 1;
BA_ "U_T6_MCA_MY2020_Rx" SG_ 578 PrkLckCtl_B_Enbl 1;
BA_ "U_CD542_MY2021_Rx" SG_ 578 PrkLckCtl_B_Enbl 1;
BA_ "U_U55X_MY2022_Rx" SG_ 578 PrkLckCtl_B_Enbl 1;
BA_ "U_CD764_MY2022_Rx" SG_ 578 PrkLckCtl_B_Enbl 1;
BA_ "WakeupSignal" SG_ 578 PrkLckCtlMsgTxt_D_Rq 1;
BA_ "GenSigSendType" SG_ 578 PrkLckCtlMsgTxt_D_Rq 3;
BA_ "WakeupSignal" SG_ 578 PrkLckCtlAvail_T_Stat 1;
BA_ "GenSigSendType" SG_ 578 BrkTrnShifLck_B_Stat 3;
BA_ "U_CX727_MY2021_Rx" SG_ 578 BrkTrnShifLck_B_Stat 1;
BA_ "U_P702_MY2021_Rx" SG_ 578 BrkTrnShifLck_B_Stat 1;
BA_ "U_T6_MCA_MY2020_Rx" SG_ 578 BrkTrnShifLck_B_Stat 1;
BA_ "U_CD542_MY2021_Rx" SG_ 578 BrkTrnShifLck_B_Stat 1;
BA_ "U_U55X_MY2022_Rx" SG_ 578 BrkTrnShifLck_B_Stat 1;
BA_ "U_CD764_MY2022_Rx" SG_ 578 BrkTrnShifLck_B_Stat 1;
BA_ "GenSigSendType" SG_ 578 DriverCrankingReq 3;
BA_ "U_CX727_MY2021_Rx" SG_ 578 DriverCrankingReq 1;
BA_ "U_P702_MY2021_Rx" SG_ 578 DriverCrankingReq 1;
BA_ "U_T6_MCA_MY2020_Rx" SG_ 578 DriverCrankingReq 1;
BA_ "U_CD542_MY2021_Rx" SG_ 578 DriverCrankingReq 1;
BA_ "U_U55X_MY2022_Rx" SG_ 578 DriverCrankingReq 1;
BA_ "U_CD764_MY2022_Rx" SG_ 578 DriverCrankingReq 1;
BA_ "U_CX727_MY2021_Rx" SG_ 578 EngOff_T_Actl 1;
BA_ "U_P702_MY2021_Rx" SG_ 578 EngOff_T_Actl 1;
BA_ "U_T6_MCA_MY2020_Rx" SG_ 578 EngOff_T_Actl 1;
BA_ "WakeupSignal" SG_ 578 ReFuelSwtchStat_D_Actl 1;
BA_ "GenSigSendType" SG_ 578 ReFuelSwtchStat_D_Actl 3;
BA_ "GenSigSendType" SG_ 578 DcacElPw_D_Rq 3;
BA_ "GenSigStartValueInteger" SG_ 578 BattULo_I_Actl 16383;
BA_ "GenSigStartValue" SG_ 578 BattULo_I_Actl 16383;
BA_ "ContentDependant" SG_ 560 SelDrvMdeSwtch_D_Stat3 1;
BA_ "GenSigSendType" SG_ 560 SelDrvMdeSwtch_D_Stat3 3;
BA_ "ContentDependant" SG_ 560 TrnGbox_Rt_Actl 1;
BA_ "ContentDependant" SG_ 560 TrnSrvcRqd_B_Rq 1;
BA_ "GenSigSendType" SG_ 560 TrnSrvcRqd_B_Rq 3;
BA_ "U_CX727_MY2021_Rx" SG_ 560 TrnSrvcRqd_B_Rq 1;
BA_ "U_P702_MY2021_Rx" SG_ 560 TrnSrvcRqd_B_Rq 1;
BA_ "U_T6_MCA_MY2020_Rx" SG_ 560 TrnSrvcRqd_B_Rq 1;
BA_ "U_CD542_MY2021_Rx" SG_ 560 TrnSrvcRqd_B_Rq 1;
BA_ "U_U55X_MY2022_Rx" SG_ 560 TrnSrvcRqd_B_Rq 1;
BA_ "U_CD764_MY2022_Rx" SG_ 560 TrnSrvcRqd_B_Rq 1;
BA_ "ContentDependant" SG_ 560 TrnCnvtClu_D_Actl 1;
BA_ "GenSigSendType" SG_ 560 TrnCnvtClu_D_Actl 3;
BA_ "ContentDependant" SG_ 560 TrnShifActv_B_Actl 1;
BA_ "GenSigSendType" SG_ 560 TrnShifActv_B_Actl 3;
BA_ "GenSigSendType" SG_ 560 RtmTerrMdeChng_D_Rdy 3;
BA_ "GenSigSendType" SG_ 560 RtmTerrMde_D_Actl 3;
BA_ "GenSigStartValueInteger" SG_ 560 GearLvrPos_D_Actl 14;
BA_ "GenSigStartValue" SG_ 560 GearLvrPos_D_Actl 14;
BA_ "GenSigSendType" SG_ 560 GearLvrPos_D_Actl 3;
BA_ "U_CX727_MY2021_Rx" SG_ 560 GearLvrPos_D_Actl 1;
BA_ "U_P702_MY2021_Rx" SG_ 560 GearLvrPos_D_Actl 1;
BA_ "U_T6_MCA_MY2020_Rx" SG_ 560 GearLvrPos_D_Actl 1;
BA_ "U_CD542_MY2021_Rx" SG_ 560 GearLvrPos_D_Actl 1;
BA_ "U_U55X_MY2022_Rx" SG_ 560 GearLvrPos_D_Actl 1;
BA_ "U_CD764_MY2022_Rx" SG_ 560 GearLvrPos_D_Actl 1;
BA_ "GenSigStartValueInteger" SG_ 560 GboxOil_Te_Actl 254;
BA_ "ContentDependant" SG_ 560 GboxOil_Te_Actl 1;
BA_ "GenSigStartValue" SG_ 560 GboxOil_Te_Actl 254;
BA_ "ContentDependant" SG_ 560 GearLvrPosActl_No_Cs 1;
BA_ "MetaData" SG_ 560 GearLvrPosActl_No_Cs 1;
BA_ "ContentDependant" SG_ 560 GearLvrPosActl_No_Cnt 1;
BA_ "MetaData" SG_ 560 GearLvrPosActl_No_Cnt 1;
BA_ "GenSigStartValueInteger" SG_ 359 PrplWhlRgenMn_Tq_Actl 4095;
BA_ "U_P702_MY2021_Rx" SG_ 359 ElPw_D_StatStrtStop 1;
BA_ "U_CX727_MY2021_Rx" SG_ 359 ElPw_D_StatStrtStop 1;
BA_ "U_T6_MCA_MY2020_Rx" SG_ 359 ElPw_D_StatStrtStop 1;
BA_ "U_U55X_MY2022_Rx" SG_ 359 ElPw_D_StatStrtStop 1;
BA_ "U_CD764_MY2022_Rx" SG_ 359 ElPw_D_StatStrtStop 1;
BA_ "U_CD542_MY2021_Rx" SG_ 359 ElPw_D_StatStrtStop 1;
BA_ "ContentDependant" SG_ 359 TrnAin_Tq_Actl 1;
BA_ "U_CX727_MY2021_Rx" SG_ 359 PrplWhlTot2_Tq_Actl 1;
BA_ "U_P702_MY2021_Rx" SG_ 359 PrplWhlTot2_Tq_Actl 1;
BA_ "U_T6_MCA_MY2020_Rx" SG_ 359 PrplWhlTot2_Tq_Actl 1;
BA_ "U_CD542_MY2021_Rx" SG_ 359 PrplWhlTot2_Tq_Actl 1;
BA_ "U_U55X_MY2022_Rx" SG_ 359 PrplWhlTot2_Tq_Actl 1;
BA_ "U_CD764_MY2022_Rx" SG_ 359 PrplWhlTot2_Tq_Actl 1;
BA_ "U_CX727_MY2021_Rx" SG_ 359 PwPckTq_D_Stat 1;
BA_ "U_P702_MY2021_Rx" SG_ 359 PwPckTq_D_Stat 1;
BA_ "U_T6_MCA_MY2020_Rx" SG_ 359 PwPckTq_D_Stat 1;
BA_ "U_CD542_MY2021_Rx" SG_ 359 PwPckTq_D_Stat 1;
BA_ "U_U55X_MY2022_Rx" SG_ 359 PwPckTq_D_Stat 1;
BA_ "U_CD764_MY2022_Rx" SG_ 359 PwPckTq_D_Stat 1;
BA_ "U_P702_MY2021_Rx" SG_ 359 ElPw_D_Stat 1;
BA_ "U_CX727_MY2021_Rx" SG_ 359 ElPw_D_Stat 1;
BA_ "U_T6_MCA_MY2020_Rx" SG_ 359 ElPw_D_Stat 1;
BA_ "U_CD542_MY2021_Rx" SG_ 359 ElPw_D_Stat 1;
BA_ "U_U55X_MY2022_Rx" SG_ 359 ElPw_D_Stat 1;
BA_ "U_CD764_MY2022_Rx" SG_ 359 ElPw_D_Stat 1;
BA_ "ContentDependant" SG_ 359 TrnAinTq_D_Qf 1;
BA_ "MetaData" SG_ 359 TrnAinTq_D_Qf 1;
BA_ "GenSigStartValueInteger" SG_ 359 PlgActvArb_B_Actl 1;
BA_ "ContentDependant" SG_ 359 PlgActvArb_B_Actl 1;
BA_ "GenSigStartValue" SG_ 359 PlgActvArb_B_Actl 1;
BA_ "GenSigStartValueInteger" SG_ 357 BPedDrvAppl_D_QF 1;
BA_ "MetaData" SG_ 357 BPedDrvAppl_D_QF 1;
BA_ "GenSigStartValue" SG_ 357 BPedDrvAppl_D_QF 1;
BA_ "GenSigSendType" SG_ 357 BPedDrvAppl_D_QF 3;
BA_ "U_CX727_MY2021_Rx" SG_ 357 BPedDrvAppl_D_QF 1;
BA_ "U_P702_MY2021_Rx" SG_ 357 BPedDrvAppl_D_QF 1;
BA_ "U_T6_MCA_MY2020_Rx" SG_ 357 BPedDrvAppl_D_QF 1;
BA_ "U_CD542_MY2021_Rx" SG_ 357 BPedDrvAppl_D_QF 1;
BA_ "U_U55X_MY2022_Rx" SG_ 357 BPedDrvAppl_D_QF 1;
BA_ "U_CD764_MY2022_Rx" SG_ 357 BPedDrvAppl_D_QF 1;
BA_ "GenSigSendType" SG_ 357 CmbbDeny_B_ActlPrpl 3;
BA_ "U_CX727_MY2021_Rx" SG_ 357 CmbbDeny_B_ActlPrpl 1;
BA_ "U_P702_MY2021_Rx" SG_ 357 CmbbDeny_B_ActlPrpl 1;
BA_ "U_T6_MCA_MY2020_Rx" SG_ 357 CmbbDeny_B_ActlPrpl 1;
BA_ "MetaData" SG_ 357 BpedDrvAppl_No_Cs 1;
BA_ "GenSigSendType" SG_ 357 PrplTqMnSat_B_Actl 3;
BA_ "U_CX727_MY2021_Rx" SG_ 357 PrplTqMnSat_B_Actl 1;
BA_ "U_P702_MY2021_Rx" SG_ 357 PrplTqMnSat_B_Actl 1;
BA_ "U_T6_MCA_MY2020_Rx" SG_ 357 PrplTqMnSat_B_Actl 1;
BA_ "GenSigSendType" SG_ 357 VehStrtStop_D_Rq 3;
BA_ "MetaData" SG_ 357 BpedDrvAppl_No_Cnt 1;
BA_ "GenSigStartValueInteger" SG_ 357 BpedDrvAppl_D_Actl 1;
BA_ "GenSigStartValue" SG_ 357 BpedDrvAppl_D_Actl 1;
BA_ "GenSigSendType" SG_ 357 BpedDrvAppl_D_Actl 3;
BA_ "U_CX727_MY2021_Rx" SG_ 357 BpedDrvAppl_D_Actl 1;
BA_ "U_P702_MY2021_Rx" SG_ 357 BpedDrvAppl_D_Actl 1;
BA_ "U_T6_MCA_MY2020_Rx" SG_ 357 BpedDrvAppl_D_Actl 1;
BA_ "U_CD542_MY2021_Rx" SG_ 357 BpedDrvAppl_D_Actl 1;
BA_ "U_U55X_MY2022_Rx" SG_ 357 BpedDrvAppl_D_Actl 1;
BA_ "U_CD764_MY2022_Rx" SG_ 357 BpedDrvAppl_D_Actl 1;
BA_ "GenSigSendType" SG_ 357 CmbbEngTqMn_B_Actl 3;
BA_ "U_CX727_MY2021_Rx" SG_ 357 CmbbEngTqMn_B_Actl 1;
BA_ "U_P702_MY2021_Rx" SG_ 357 CmbbEngTqMn_B_Actl 1;
BA_ "U_T6_MCA_MY2020_Rx" SG_ 357 CmbbEngTqMn_B_Actl 1;
BA_ "U_T6_MCA_MY2020_Rx" SG_ 357 Veh_V_DsplyCcSet 1;
BA_ "GenSigSendType" SG_ 357 AccEngStat_D_Actl 3;
BA_ "U_CX727_MY2021_Rx" SG_ 357 AccEngStat_D_Actl 1;
BA_ "U_P702_MY2021_Rx" SG_ 357 AccEngStat_D_Actl 1;
BA_ "U_T6_MCA_MY2020_Rx" SG_ 357 AccEngStat_D_Actl 1;
BA_ "GenSigSendType" SG_ 357 CcMde_D_Actl 3;
BA_ "GenSigSendType" SG_ 357 CcStat_D_Actl 3;
BA_ "U_CX727_MY2021_Rx" SG_ 357 CcStat_D_Actl 1;
BA_ "U_P702_MY2021_Rx" SG_ 357 CcStat_D_Actl 1;
BA_ "U_T6_MCA_MY2020_Rx" SG_ 357 CcStat_D_Actl 1;
BA_ "U_CD542_MY2021_Rx" SG_ 357 CcStat_D_Actl 1;
BA_ "U_U55X_MY2022_Rx" SG_ 357 CcStat_D_Actl 1;
BA_ "U_CD764_MY2022_Rx" SG_ 357 CcStat_D_Actl 1;
BA_ "GenSigSendType" SG_ 357 CcOvrrdActv_B_Actl 3;
BA_ "U_CX727_MY2021_Rx" SG_ 357 CcOvrrdActv_B_Actl 1;
BA_ "U_P702_MY2021_Rx" SG_ 357 CcOvrrdActv_B_Actl 1;
BA_ "U_T6_MCA_MY2020_Rx" SG_ 357 CcOvrrdActv_B_Actl 1;
BA_ "U_CD542_MY2021_Rx" SG_ 357 CcOvrrdActv_B_Actl 1;
BA_ "U_U55X_MY2022_Rx" SG_ 357 CcOvrrdActv_B_Actl 1;
BA_ "U_CD764_MY2022_Rx" SG_ 357 CcOvrrdActv_B_Actl 1;
BA_ "GenSigSendType" SG_ 357 AccStopMde_D_Rq 3;
BA_ "U_CX727_MY2021_Rx" SG_ 357 AccStopMde_D_Rq 1;
BA_ "U_P702_MY2021_Rx" SG_ 357 AccStopMde_D_Rq 1;
BA_ "U_T6_MCA_MY2020_Rx" SG_ 357 AccStopMde_D_Rq 1;
BA_ "GenSigStartValueInteger" SG_ 390 AccBrkTot_A_Rq 5129;
BA_ "U_T6_MCA_MY2020_Tx" SG_ 390 AccBrkTot_A_Rq 1;
BA_ "U_T6_MCA_MY2020_Tx" SG_ 390 AccPrpl_A_Pred 1;
BA_ "U_T6_MCA_MY2020_Tx" SG_ 390 AccVeh_V_Trg 1;
BA_ "U_T6_MCA_MY2020_Tx" SG_ 390 AccBrkPrkEl_B_Rq 1;
BA_ "U_CX727_MY2021_Rx" SG_ 390 Cmbb_B_Enbl 1;
BA_ "U_P702_MY2021_Rx" SG_ 390 Cmbb_B_Enbl 1;
BA_ "U_T6_MCA_MY2020_Rx" SG_ 390 Cmbb_B_Enbl 1;
BA_ "U_CD542_MY2021_Rx" SG_ 390 Cmbb_B_Enbl 1;
BA_ "U_U55X_MY2022_Rx" SG_ 390 Cmbb_B_Enbl 1;
BA_ "U_CD764_MY2022_Rx" SG_ 390 Cmbb_B_Enbl 1;
BA_ "U_T6_MCA_MY2020_Tx" SG_ 390 Cmbb_B_Enbl 1;
BA_ "U_CX727_MY2021_Rx" SG_ 390 CmbbOvrrd_B_RqDrv 1;
BA_ "U_P702_MY2021_Rx" SG_ 390 CmbbOvrrd_B_RqDrv 1;
BA_ "U_T6_MCA_MY2020_Rx" SG_ 390 CmbbOvrrd_B_RqDrv 1;
BA_ "U_CD542_MY2021_Rx" SG_ 390 CmbbOvrrd_B_RqDrv 1;
BA_ "U_U55X_MY2022_Rx" SG_ 390 CmbbOvrrd_B_RqDrv 1;
BA_ "U_CD764_MY2022_Rx" SG_ 390 CmbbOvrrd_B_RqDrv 1;
BA_ "U_T6_MCA_MY2020_Tx" SG_ 390 CmbbOvrrd_B_RqDrv 1;
BA_ "U_CX727_MY2021_Rx" SG_ 390 CmbbDeny_B_Actl 1;
BA_ "U_P702_MY2021_Rx" SG_ 390 CmbbDeny_B_Actl 1;
BA_ "U_T6_MCA_MY2020_Rx" SG_ 390 CmbbDeny_B_Actl 1;
BA_ "U_CD542_MY2021_Rx" SG_ 390 CmbbDeny_B_Actl 1;
BA_ "U_U55X_MY2022_Rx" SG_ 390 CmbbDeny_B_Actl 1;
BA_ "U_CD764_MY2022_Rx" SG_ 390 CmbbDeny_B_Actl 1;
BA_ "U_T6_MCA_MY2020_Tx" SG_ 390 CmbbDeny_B_Actl 1;
BA_ "U_T6_MCA_MY2020_Tx" SG_ 390 CmbbEngTqMn_B_Rq 1;
BA_ "U_T6_MCA_MY2020_Tx" SG_ 390 AccPrpl_A_Rq 1;
BA_ "U_T6_MCA_MY2020_Tx" SG_ 390 AccDeny_B_Rq 1;
BA_ "WakeupSignal" SG_ 390 AccResumEnbl_B_Rq 1;
BA_ "U_T6_MCA_MY2020_Tx" SG_ 390 AccResumEnbl_B_Rq 1;
BA_ "U_T6_MCA_MY2020_Tx" SG_ 390 AccCancl_B_Rq 1;
BA_ "U_T6_MCA_MY2020_Tx" SG_ 390 AccBrkPrchg_B_Rq 1;
BA_ "U_T6_MCA_MY2020_Tx" SG_ 390 AccBrkDecel_B_Rq 1;
BA_ "U_T6_MCA_MY2020_Tx" SG_ 390 AccStopStat_B_Rq 1;
BA_ "ContentDependant" SG_ 1071 CluPdl_PcRate_Actl 1;
BA_ "GenSigStartValueInteger" SG_ 1071 CluPdlPosPcMeas_D_Qf 1;
BA_ "ContentDependant" SG_ 1071 CluPdlPosPcMeas_D_Qf 1;
BA_ "MetaData" SG_ 1071 CluPdlPosPcMeas_D_Qf 1;
BA_ "GenSigStartValue" SG_ 1071 CluPdlPosPcMeas_D_Qf 1;
BA_ "U_CX727_MY2021_Rx" SG_ 1071 CluPdlPosPcMeas_D_Qf 1;
BA_ "U_P702_MY2021_Rx" SG_ 1071 CluPdlPosPcMeas_D_Qf 1;
BA_ "U_T6_MCA_MY2020_Rx" SG_ 1071 CluPdlPosPcMeas_D_Qf 1;
BA_ "ContentDependant" SG_ 1071 CluPdlPos_Pc_Meas 1;
BA_ "U_CX727_MY2021_Rx" SG_ 1071 CluPdlPos_Pc_Meas 1;
BA_ "U_P702_MY2021_Rx" SG_ 1071 CluPdlPos_Pc_Meas 1;
BA_ "U_T6_MCA_MY2020_Rx" SG_ 1071 CluPdlPos_Pc_Meas 1;
BA_ "GenSigStartValueInteger" SG_ 1071 EngMnfld3_P_Actl 254;
BA_ "GenSigStartValue" SG_ 1071 EngMnfld3_P_Actl 254;
BA_ "ContentDependant" SG_ 1071 EngAoutIdl_N_Ntrl 1;
BA_ "GenSigSendType" SG_ 1072 TrlrAidCancl_B_Rq 3;
BA_ "GenSigSendType" SG_ 1072 HdcOn_B_Rq 3;
BA_ "GenSigStartValueInteger" SG_ 1072 HsaMde_D_Rq 1;
BA_ "GenSigStartValue" SG_ 1072 HsaMde_D_Rq 1;
BA_ "GenSigSendType" SG_ 1072 HsaMde_D_Rq 3;
BA_ "GenSigSendType" SG_ 1072 LscmbbStat_B_Actl 3;
BA_ "U_T6_MCA_MY2020_Rx" SG_ 1072 Outside_Air_Temp_Stat_UB 1;
BA_ "U_CD764_MY2022_Rx" SG_ 1072 Outside_Air_Temp_Stat_UB 1;
BA_ "U_CX727_MY2021_Rx" SG_ 1072 Outside_Air_Temp_Stat_UB 1;
BA_ "U_P702_MY2021_Rx" SG_ 1072 Outside_Air_Temp_Stat_UB 1;
BA_ "GenSigStartValueInteger" SG_ 1072 Outside_Air_Temp_Stat 254;
BA_ "GenSigStartValue" SG_ 1072 Outside_Air_Temp_Stat 254;
BA_ "GenSigSendType" SG_ 1072 Outside_Air_Temp_Stat 3;
BA_ "U_T6_MCA_MY2020_Rx" SG_ 1072 Outside_Air_Temp_Stat 1;
BA_ "U_CD764_MY2022_Rx" SG_ 1072 Outside_Air_Temp_Stat 1;
BA_ "U_CX727_MY2021_Rx" SG_ 1072 Outside_Air_Temp_Stat 1;
BA_ "U_P702_MY2021_Rx" SG_ 1072 Outside_Air_Temp_Stat 1;
BA_ "GenSigSendType" SG_ 1072 BulbChkActv_B_Stat 3;
BA_ "U_CX727_MY2021_Rx" SG_ 1072 Fda_B_Stat_UB 1;
BA_ "U_P702_MY2021_Rx" SG_ 1072 Fda_B_Stat_UB 1;
BA_ "U_T6_MCA_MY2020_Rx" SG_ 1072 Fda_B_Stat_UB 1;
BA_ "U_CX727_MY2021_Rx" SG_ 1072 AccEnbl_B_RqDrv_UB 1;
BA_ "U_P702_MY2021_Rx" SG_ 1072 AccEnbl_B_RqDrv_UB 1;
BA_ "U_T6_MCA_MY2020_Rx" SG_ 1072 AccEnbl_B_RqDrv_UB 1;
BA_ "U_CX727_MY2021_Rx" SG_ 1072 AccDeny_B_RqIpc_UB 1;
BA_ "U_P702_MY2021_Rx" SG_ 1072 AccDeny_B_RqIpc_UB 1;
BA_ "U_T6_MCA_MY2020_Rx" SG_ 1072 AccDeny_B_RqIpc_UB 1;
BA_ "U_P702_MY2021_Rx" SG_ 1072 OdometerMasterValue_UB 1;
BA_ "U_CX727_MY2021_Rx" SG_ 1072 OdometerMasterValue_UB 1;
BA_ "U_T6_MCA_MY2020_Rx" SG_ 1072 OdometerMasterValue_UB 1;
BA_ "GenSigSendType" SG_ 1072 OdometerMasterValue 3;
BA_ "U_P702_MY2021_Rx" SG_ 1072 OdometerMasterValue 1;
BA_ "U_CX727_MY2021_Rx" SG_ 1072 OdometerMasterValue 1;
BA_ "U_T6_MCA_MY2020_Rx" SG_ 1072 OdometerMasterValue 1;
BA_ "U_CD542_MY2021_Rx" SG_ 1072 OdometerMasterValue 1;
BA_ "U_U55X_MY2022_Rx" SG_ 1072 OdometerMasterValue 1;
BA_ "U_CD764_MY2022_Rx" SG_ 1072 OdometerMasterValue 1;
BA_ "GenSigSendType" SG_ 1072 Fda_B_Stat 3;
BA_ "U_CX727_MY2021_Rx" SG_ 1072 Fda_B_Stat 1;
BA_ "U_P702_MY2021_Rx" SG_ 1072 Fda_B_Stat 1;
BA_ "U_T6_MCA_MY2020_Rx" SG_ 1072 Fda_B_Stat 1;
BA_ "GenSigSendType" SG_ 1072 AccDeny_B_RqIpc 3;
BA_ "U_CX727_MY2021_Rx" SG_ 1072 AccDeny_B_RqIpc 1;
BA_ "U_P702_MY2021_Rx" SG_ 1072 AccDeny_B_RqIpc 1;
BA_ "U_T6_MCA_MY2020_Rx" SG_ 1072 AccDeny_B_RqIpc 1;
BA_ "GenSigStartValueInteger" SG_ 1072 AccEnbl_B_RqDrv 1;
BA_ "GenSigStartValue" SG_ 1072 AccEnbl_B_RqDrv 1;
BA_ "GenSigSendType" SG_ 1072 AccEnbl_B_RqDrv 3;
BA_ "U_CX727_MY2021_Rx" SG_ 1072 AccEnbl_B_RqDrv 1;
BA_ "U_P702_MY2021_Rx" SG_ 1072 AccEnbl_B_RqDrv 1;
BA_ "U_T6_MCA_MY2020_Rx" SG_ 1072 AccEnbl_B_RqDrv 1;
BA_ "GenSigSendType" SG_ 1072 DrvSlipCtlMde_D_Rq 3;
BA_ "GenSigSendType" SG_ 1072 DrvSlipCtlMde_B_Rq 3;
BA_ "U_CX727_MY2021_Rx" SG_ 1072 ePRNDL_MODE_UB 1;
BA_ "U_P702_MY2021_Rx" SG_ 1072 ePRNDL_MODE_UB 1;
BA_ "U_T6_MCA_MY2020_Rx" SG_ 1072 ePRNDL_MODE_UB 1;
BA_ "U_CD542_MY2021_Rx" SG_ 1072 ePRNDL_MODE_UB 1;
BA_ "U_U55X_MY2022_Rx" SG_ 1072 ePRNDL_MODE_UB 1;
BA_ "U_CD764_MY2022_Rx" SG_ 1072 ePRNDL_MODE_UB 1;
BA_ "WakeupSignal" SG_ 1072 ePRNDL_MODE 1;
BA_ "GenSigSendType" SG_ 1072 ePRNDL_MODE 3;
BA_ "U_CX727_MY2021_Rx" SG_ 1072 ePRNDL_MODE 1;
BA_ "U_P702_MY2021_Rx" SG_ 1072 ePRNDL_MODE 1;
BA_ "U_T6_MCA_MY2020_Rx" SG_ 1072 ePRNDL_MODE 1;
BA_ "U_CD542_MY2021_Rx" SG_ 1072 ePRNDL_MODE 1;
BA_ "U_U55X_MY2022_Rx" SG_ 1072 ePRNDL_MODE 1;
BA_ "U_CD764_MY2022_Rx" SG_ 1072 ePRNDL_MODE 1;
BA_ "GenSigSendType" SG_ 1072 TrlrBrkMde_D_Rq 3;
BA_ "U_P702_MY2021_Rx" SG_ 1072 TrlrBrkMde_D_Rq 1;
BA_ "GenSigSendType" SG_ 1072 TRLR_SWAY_CONFIG_CMD 3;
BA_ "GenSigSendType" SG_ 1072 TRAILER_BRAKE_CONFIG 3;
BA_ "U_P702_MY2021_Rx" SG_ 1072 TRAILER_BRAKE_CONFIG 1;
BA_ "U_P702_MY2021_Rx" SG_ 1072 TrlrBrkMde_D_Rq_UB 1;
BA_ "U_P702_MY2021_Rx" SG_ 1072 TRAILER_BRAKE_CONFIG_UB 1;
BA_ "U_CX727_MY2021_Rx" SG_ 1058 BattTracWarnLamp_B_Rq 1;
BA_ "U_P702_MY2021_Rx" SG_ 1058 BattTracWarnLamp_B_Rq 1;
BA_ "U_CD542_MY2021_Rx" SG_ 1058 BattTracWarnLamp_B_Rq 1;
BA_ "U_CD764_MY2022_Rx" SG_ 1058 BattTracWarnLamp_B_Rq 1;
BA_ "U_CX727_MY2021_Rx" SG_ 1058 BattTracSrvcRqd_B_Rq 1;
BA_ "U_P702_MY2021_Rx" SG_ 1058 BattTracSrvcRqd_B_Rq 1;
BA_ "U_CD542_MY2021_Rx" SG_ 1058 BattTracSrvcRqd_B_Rq 1;
BA_ "U_CD764_MY2022_Rx" SG_ 1058 BattTracSrvcRqd_B_Rq 1;
BA_ "U_P702_MY2021_Rx" SG_ 1058 SeatBlLoPsgr_Pc_Actl_UB 1;
BA_ "U_U55X_MY2022_Rx" SG_ 1058 SeatBlLoPsgr_Pc_Actl_UB 1;
BA_ "GenSigStartValueInteger" SG_ 1058 SeatBlLoPsgr_Pc_Actl 127;
BA_ "GenSigStartValue" SG_ 1058 SeatBlLoPsgr_Pc_Actl 127;
BA_ "U_P702_MY2021_Rx" SG_ 1058 SeatBlLoPsgr_Pc_Actl 1;
BA_ "U_U55X_MY2022_Rx" SG_ 1058 SeatBlLoPsgr_Pc_Actl 1;
BA_ "U_CX727_MY2021_Rx" SG_ 1058 WndwFrontHeat_B_Stat_UB 1;
BA_ "U_P702_MY2021_Rx" SG_ 1058 WndwFrontHeat_B_Stat_UB 1;
BA_ "U_T6_MCA_MY2020_Rx" SG_ 1058 WndwFrontHeat_B_Stat_UB 1;
BA_ "U_CX727_MY2021_Rx" SG_ 1058 WndwFrontHeat_B_Stat 1;
BA_ "U_P702_MY2021_Rx" SG_ 1058 WndwFrontHeat_B_Stat 1;
BA_ "U_T6_MCA_MY2020_Rx" SG_ 1058 WndwFrontHeat_B_Stat 1;
BA_ "MetaData" SG_ 1058 EngClntTe_D_Qf 1;
BA_ "U_CX727_MY2021_Rx" SG_ 1058 EngClnt_Te_Actl 1;
BA_ "U_P702_MY2021_Rx" SG_ 1058 EngClnt_Te_Actl 1;
BA_ "U_T6_MCA_MY2020_Rx" SG_ 1058 EngClnt_Te_Actl 1;
BA_ "U_CD542_MY2021_Rx" SG_ 1058 EngClnt_Te_Actl 1;
BA_ "ContentDependant" SG_ 1058 TrnTotTq_Rt_Est 1;
BA_ "ContentDependant" SG_ 1058 TrnTotLss_Tq_Est 1;
BA_ "GenSigStartValueInteger" SG_ 1082 EsaOn_B_Rq 1;
BA_ "GenSigStartValue" SG_ 1082 EsaOn_B_Rq 1;
BA_ "GenSigSendType" SG_ 1082 EsaOn_B_Rq 3;
BA_ "GenSigStartValueInteger" SG_ 1082 RearDiffLck_D_RqArb 3;
BA_ "GenSigStartValue" SG_ 1082 RearDiffLck_D_RqArb 3;
BA_ "GenSigSendType" SG_ 1082 RearDiffLck_D_RqArb 3;
BA_ "GenSigStartValueInteger" SG_ 1082 AwdMde_D_RqArb 5;
BA_ "GenSigStartValue" SG_ 1082 AwdMde_D_RqArb 5;
BA_ "GenSigSendType" SG_ 1082 AwdMde_D_RqArb 3;
BA_ "GenSigSendType" SG_ 1082 SelDrvMdeTxtReset_B_Rq 3;
BA_ "U_CX727_MY2021_Rx" SG_ 1082 DrvInputRequired_B_Rq_UB 1;
BA_ "U_P702_MY2021_Rx" SG_ 1082 DrvInputRequired_B_Rq_UB 1;
BA_ "U_T6_MCA_MY2020_Rx" SG_ 1082 DrvInputRequired_B_Rq_UB 1;
BA_ "U_CD542_MY2021_Rx" SG_ 1082 DrvInputRequired_B_Rq_UB 1;
BA_ "U_U55X_MY2022_Rx" SG_ 1082 DrvInputRequired_B_Rq_UB 1;
BA_ "U_CD764_MY2022_Rx" SG_ 1082 DrvInputRequired_B_Rq_UB 1;
BA_ "WakeupSignal" SG_ 1082 DrvInputRequired_B_Rq 1;
BA_ "GenSigSendType" SG_ 1082 DrvInputRequired_B_Rq 3;
BA_ "U_CX727_MY2021_Rx" SG_ 1082 DrvInputRequired_B_Rq 1;
BA_ "U_P702_MY2021_Rx" SG_ 1082 DrvInputRequired_B_Rq 1;
BA_ "U_T6_MCA_MY2020_Rx" SG_ 1082 DrvInputRequired_B_Rq 1;
BA_ "U_CD542_MY2021_Rx" SG_ 1082 DrvInputRequired_B_Rq 1;
BA_ "U_U55X_MY2022_Rx" SG_ 1082 DrvInputRequired_B_Rq 1;
BA_ "U_CD764_MY2022_Rx" SG_ 1082 DrvInputRequired_B_Rq 1;
BA_ "GenSigSendType" SG_ 1082 SelDrvMdeSwtch_D_Stat2 3;
BA_ "GenSigSendType" SG_ 1082 FapLcStopHold_B_Rq 3;
BA_ "GenSigSendType" SG_ 1082 SelDrvMdeDsply_B_Avail 3;
BA_ "GenSigSendType" SG_ 1082 LnchCtl_D_Rq 3;
BA_ "GenSigSendType" SG_ 1082 AirSusp_D_RqDrv 3;
BA_ "GenSigStartValueInteger" SG_ 1082 AwdRnge_D_ActlIpc 7;
BA_ "GenSigStartValue" SG_ 1082 AwdRnge_D_ActlIpc 7;
BA_ "GenSigSendType" SG_ 1082 AwdRnge_D_ActlIpc 3;
BA_ "GenSigSendType" SG_ 1082 NtrlTowMdeEnbl_B_RqDrv 3;
BA_ "GenSigSendType" SG_ 1082 DrvSlipCtlMde_B_RqMyKey 3;
BA_ "GenSigSendType" SG_ 1082 AwdDrvMde_D_Rq 3;
BA_ "U_CX727_MY2021_Rx" SG_ 1082 MetricActv_B_Actl_UB 1;
BA_ "U_P702_MY2021_Rx" SG_ 1082 MetricActv_B_Actl_UB 1;
BA_ "U_T6_MCA_MY2020_Rx" SG_ 1082 MetricActv_B_Actl_UB 1;
BA_ "GenSigSendType" SG_ 1082 MetricActv_B_Actl 3;
BA_ "U_CX727_MY2021_Rx" SG_ 1082 MetricActv_B_Actl 1;
BA_ "U_P702_MY2021_Rx" SG_ 1082 MetricActv_B_Actl 1;
BA_ "U_T6_MCA_MY2020_Rx" SG_ 1082 MetricActv_B_Actl 1;
BA_ "GenSigSendType" SG_ 1082 BrkLineLck_D_Rq 3;
BA_ "GenSigSendType" SG_ 1082 SuspDrvMde_D_Rq 3;
BA_ "GenSigSendType" SG_ 1082 SelDrvMdePt_D_Stat 3;
BA_ "GenSigStartValueInteger" SG_ 1462 GSM_GWOnBoardTester 255;
BA_ "ContentDependant" SG_ 1462 GSM_GWOnBoardTester 1;
BA_ "GenSigStartValue" SG_ 1462 GSM_GWOnBoardTester 255;
BA_ "U_P702_MY2021_Rx" SG_ 1462 GSM_GWOnBoardTester 1;
BA_ "U_CD542_MY2021_Rx" SG_ 1462 GSM_GWOnBoardTester 1;
BA_ "U_U55X_MY2022_Rx" SG_ 1462 GSM_GWOnBoardTester 1;
BA_ "U_CD764_MY2022_Rx" SG_ 1462 GSM_GWOnBoardTester 1;
BA_ "U_CX727_MY2021_Tx" SG_ 1462 GSM_GWOnBoardTester 1;
BA_ "U_P702_MY2021_Tx" SG_ 1462 GSM_GWOnBoardTester 1;
BA_ "U_T6_MCA_MY2020_Tx" SG_ 1462 GSM_GWOnBoardTester 1;
BA_ "U_CD542_MY2021_Tx" SG_ 1462 GSM_GWOnBoardTester 1;
BA_ "U_U55X_MY2022_Tx" SG_ 1462 GSM_GWOnBoardTester 1;
BA_ "U_CD764_MY2022_Tx" SG_ 1462 GSM_GWOnBoardTester 1;
BA_ "GenSigStartValueInteger" SG_ 1462 GSM_GWNMProxy 255;
BA_ "ContentDependant" SG_ 1462 GSM_GWNMProxy 1;
BA_ "GenSigStartValue" SG_ 1462 GSM_GWNMProxy 255;
BA_ "U_P702_MY2021_Rx" SG_ 1462 GSM_GWNMProxy 1;
BA_ "U_CD542_MY2021_Rx" SG_ 1462 GSM_GWNMProxy 1;
BA_ "U_U55X_MY2022_Rx" SG_ 1462 GSM_GWNMProxy 1;
BA_ "U_CD764_MY2022_Rx" SG_ 1462 GSM_GWNMProxy 1;
BA_ "U_CX727_MY2021_Tx" SG_ 1462 GSM_GWNMProxy 1;
BA_ "U_P702_MY2021_Tx" SG_ 1462 GSM_GWNMProxy 1;
BA_ "U_T6_MCA_MY2020_Tx" SG_ 1462 GSM_GWNMProxy 1;
BA_ "U_CD542_MY2021_Tx" SG_ 1462 GSM_GWNMProxy 1;
BA_ "U_U55X_MY2022_Tx" SG_ 1462 GSM_GWNMProxy 1;
BA_ "U_CD764_MY2022_Tx" SG_ 1462 GSM_GWNMProxy 1;
BA_ "GenSigStartValueInteger" SG_ 1462 GSM_AutoSarNMReserved4 255;
BA_ "ContentDependant" SG_ 1462 GSM_AutoSarNMReserved4 1;
BA_ "GenSigStartValue" SG_ 1462 GSM_AutoSarNMReserved4 255;
BA_ "U_P702_MY2021_Rx" SG_ 1462 GSM_AutoSarNMReserved4 1;
BA_ "U_CD542_MY2021_Rx" SG_ 1462 GSM_AutoSarNMReserved4 1;
BA_ "U_U55X_MY2022_Rx" SG_ 1462 GSM_AutoSarNMReserved4 1;
BA_ "U_CD764_MY2022_Rx" SG_ 1462 GSM_AutoSarNMReserved4 1;
BA_ "U_CX727_MY2021_Tx" SG_ 1462 GSM_AutoSarNMReserved4 1;
BA_ "U_P702_MY2021_Tx" SG_ 1462 GSM_AutoSarNMReserved4 1;
BA_ "U_T6_MCA_MY2020_Tx" SG_ 1462 GSM_AutoSarNMReserved4 1;
BA_ "U_CD542_MY2021_Tx" SG_ 1462 GSM_AutoSarNMReserved4 1;
BA_ "U_U55X_MY2022_Tx" SG_ 1462 GSM_AutoSarNMReserved4 1;
BA_ "U_CD764_MY2022_Tx" SG_ 1462 GSM_AutoSarNMReserved4 1;
BA_ "GenSigStartValueInteger" SG_ 1462 GSM_AutoSarNMReserved3 255;
BA_ "ContentDependant" SG_ 1462 GSM_AutoSarNMReserved3 1;
BA_ "GenSigStartValue" SG_ 1462 GSM_AutoSarNMReserved3 255;
BA_ "U_P702_MY2021_Rx" SG_ 1462 GSM_AutoSarNMReserved3 1;
BA_ "U_CD542_MY2021_Rx" SG_ 1462 GSM_AutoSarNMReserved3 1;
BA_ "U_U55X_MY2022_Rx" SG_ 1462 GSM_AutoSarNMReserved3 1;
BA_ "U_CD764_MY2022_Rx" SG_ 1462 GSM_AutoSarNMReserved3 1;
BA_ "U_CX727_MY2021_Tx" SG_ 1462 GSM_AutoSarNMReserved3 1;
BA_ "U_P702_MY2021_Tx" SG_ 1462 GSM_AutoSarNMReserved3 1;
BA_ "U_T6_MCA_MY2020_Tx" SG_ 1462 GSM_AutoSarNMReserved3 1;
BA_ "U_CD542_MY2021_Tx" SG_ 1462 GSM_AutoSarNMReserved3 1;
BA_ "U_U55X_MY2022_Tx" SG_ 1462 GSM_AutoSarNMReserved3 1;
BA_ "U_CD764_MY2022_Tx" SG_ 1462 GSM_AutoSarNMReserved3 1;
BA_ "GenSigStartValueInteger" SG_ 1462 GSM_AutoSarNMReserved2 255;
BA_ "ContentDependant" SG_ 1462 GSM_AutoSarNMReserved2 1;
BA_ "GenSigStartValue" SG_ 1462 GSM_AutoSarNMReserved2 255;
BA_ "U_P702_MY2021_Rx" SG_ 1462 GSM_AutoSarNMReserved2 1;
BA_ "U_CD542_MY2021_Rx" SG_ 1462 GSM_AutoSarNMReserved2 1;
BA_ "U_U55X_MY2022_Rx" SG_ 1462 GSM_AutoSarNMReserved2 1;
BA_ "U_CD764_MY2022_Rx" SG_ 1462 GSM_AutoSarNMReserved2 1;
BA_ "U_CX727_MY2021_Tx" SG_ 1462 GSM_AutoSarNMReserved2 1;
BA_ "U_P702_MY2021_Tx" SG_ 1462 GSM_AutoSarNMReserved2 1;
BA_ "U_T6_MCA_MY2020_Tx" SG_ 1462 GSM_AutoSarNMReserved2 1;
BA_ "U_CD542_MY2021_Tx" SG_ 1462 GSM_AutoSarNMReserved2 1;
BA_ "U_U55X_MY2022_Tx" SG_ 1462 GSM_AutoSarNMReserved2 1;
BA_ "U_CD764_MY2022_Tx" SG_ 1462 GSM_AutoSarNMReserved2 1;
BA_ "GenSigStartValueInteger" SG_ 1462 GSM_AutoSarNMReserved1 255;
BA_ "ContentDependant" SG_ 1462 GSM_AutoSarNMReserved1 1;
BA_ "GenSigStartValue" SG_ 1462 GSM_AutoSarNMReserved1 255;
BA_ "U_P702_MY2021_Rx" SG_ 1462 GSM_AutoSarNMReserved1 1;
BA_ "U_CD542_MY2021_Rx" SG_ 1462 GSM_AutoSarNMReserved1 1;
BA_ "U_U55X_MY2022_Rx" SG_ 1462 GSM_AutoSarNMReserved1 1;
BA_ "U_CD764_MY2022_Rx" SG_ 1462 GSM_AutoSarNMReserved1 1;
BA_ "U_CX727_MY2021_Tx" SG_ 1462 GSM_AutoSarNMReserved1 1;
BA_ "U_P702_MY2021_Tx" SG_ 1462 GSM_AutoSarNMReserved1 1;
BA_ "U_T6_MCA_MY2020_Tx" SG_ 1462 GSM_AutoSarNMReserved1 1;
BA_ "U_CD542_MY2021_Tx" SG_ 1462 GSM_AutoSarNMReserved1 1;
BA_ "U_U55X_MY2022_Tx" SG_ 1462 GSM_AutoSarNMReserved1 1;
BA_ "U_CD764_MY2022_Tx" SG_ 1462 GSM_AutoSarNMReserved1 1;
BA_ "GenSigStartValueInteger" SG_ 1462 GSM_AutoSarNMNodeId 182;
BA_ "ContentDependant" SG_ 1462 GSM_AutoSarNMNodeId 1;
BA_ "GenSigStartValue" SG_ 1462 GSM_AutoSarNMNodeId 182;
BA_ "U_P702_MY2021_Rx" SG_ 1462 GSM_AutoSarNMNodeId 1;
BA_ "U_CD542_MY2021_Rx" SG_ 1462 GSM_AutoSarNMNodeId 1;
BA_ "U_U55X_MY2022_Rx" SG_ 1462 GSM_AutoSarNMNodeId 1;
BA_ "U_CD764_MY2022_Rx" SG_ 1462 GSM_AutoSarNMNodeId 1;
BA_ "U_CX727_MY2021_Tx" SG_ 1462 GSM_AutoSarNMNodeId 1;
BA_ "U_P702_MY2021_Tx" SG_ 1462 GSM_AutoSarNMNodeId 1;
BA_ "U_T6_MCA_MY2020_Tx" SG_ 1462 GSM_AutoSarNMNodeId 1;
BA_ "U_CD542_MY2021_Tx" SG_ 1462 GSM_AutoSarNMNodeId 1;
BA_ "U_U55X_MY2022_Tx" SG_ 1462 GSM_AutoSarNMNodeId 1;
BA_ "U_CD764_MY2022_Tx" SG_ 1462 GSM_AutoSarNMNodeId 1;
BA_ "ContentDependant" SG_ 1462 GSM_AutoSarNMControl 1;
BA_ "U_P702_MY2021_Rx" SG_ 1462 GSM_AutoSarNMControl 1;
BA_ "U_CD542_MY2021_Rx" SG_ 1462 GSM_AutoSarNMControl 1;
BA_ "U_U55X_MY2022_Rx" SG_ 1462 GSM_AutoSarNMControl 1;
BA_ "U_CD764_MY2022_Rx" SG_ 1462 GSM_AutoSarNMControl 1;
BA_ "U_CX727_MY2021_Tx" SG_ 1462 GSM_AutoSarNMControl 1;
BA_ "U_P702_MY2021_Tx" SG_ 1462 GSM_AutoSarNMControl 1;
BA_ "U_T6_MCA_MY2020_Tx" SG_ 1462 GSM_AutoSarNMControl 1;
BA_ "U_CD542_MY2021_Tx" SG_ 1462 GSM_AutoSarNMControl 1;
BA_ "U_U55X_MY2022_Tx" SG_ 1462 GSM_AutoSarNMControl 1;
BA_ "U_CD764_MY2022_Tx" SG_ 1462 GSM_AutoSarNMControl 1;
BA_ "ContentDependant" SG_ 92 TrnGearMsgTxt2_D_Rq 1;
BA_ "GenSigStartValueInteger" SG_ 92 TrnLvrV_D_Rq 1;
BA_ "GenSigStartValue" SG_ 92 TrnLvrV_D_Rq 1;
BA_ "GenSigStartValueInteger" SG_ 92 TrnSbwSysHlth_D_Actl 1;
BA_ "ContentDependant" SG_ 92 TrnSbwSysHlth_D_Actl 1;
BA_ "GenSigStartValue" SG_ 92 TrnSbwSysHlth_D_Actl 1;
BA_ "U_CX727_MY2021_Rx" SG_ 92 TrnSbwSysHlth_D_Actl 1;
BA_ "U_P702_MY2021_Rx" SG_ 92 TrnSbwSysHlth_D_Actl 1;
BA_ "U_T6_MCA_MY2020_Rx" SG_ 92 TrnSbwSysHlth_D_Actl 1;
BA_ "U_CD542_MY2021_Rx" SG_ 92 TrnSbwSysHlth_D_Actl 1;
BA_ "U_U55X_MY2022_Rx" SG_ 92 TrnSbwSysHlth_D_Actl 1;
BA_ "WakeupSignal" SG_ 92 TrnDtpCmd_D_Actl 1;
BA_ "GenSigStartValueInteger" SG_ 92 TrnDtpCmd_D_Actl 1;
BA_ "ContentDependant" SG_ 92 TrnDtpCmd_D_Actl 1;
BA_ "GenSigStartValue" SG_ 92 TrnDtpCmd_D_Actl 1;
BA_ "U_CX727_MY2021_Rx" SG_ 92 TrnDtpCmd_D_Actl 1;
BA_ "U_P702_MY2021_Rx" SG_ 92 TrnDtpCmd_D_Actl 1;
BA_ "U_T6_MCA_MY2020_Rx" SG_ 92 TrnDtpCmd_D_Actl 1;
BA_ "U_CD542_MY2021_Rx" SG_ 92 TrnDtpCmd_D_Actl 1;
BA_ "U_U55X_MY2022_Rx" SG_ 92 TrnDtpCmd_D_Actl 1;
BA_ "U_CD764_MY2022_Rx" SG_ 92 TrnDtpCmd_D_Actl 1;
BA_ "ContentDependant" SG_ 92 TrnGearNtmAllow_B_Stat 1;
BA_ "U_CX727_MY2021_Rx" SG_ 92 GearSelLck_D_Rq 1;
BA_ "U_P702_MY2021_Rx" SG_ 92 GearSelLck_D_Rq 1;
BA_ "U_T6_MCA_MY2020_Rx" SG_ 92 GearSelLck_D_Rq 1;
BA_ "U_CD542_MY2021_Rx" SG_ 92 GearSelLck_D_Rq 1;
BA_ "U_U55X_MY2022_Rx" SG_ 92 GearSelLck_D_Rq 1;
BA_ "U_CD764_MY2022_Rx" SG_ 92 GearSelLck_D_Rq 1;
BA_ "ContentDependant" SG_ 92 TrnGearCmd_No_Cs 1;
BA_ "MetaData" SG_ 92 TrnGearCmd_No_Cs 1;
BA_ "U_CX727_MY2021_Rx" SG_ 92 TrnGearCmd_No_Cs 1;
BA_ "U_P702_MY2021_Rx" SG_ 92 TrnGearCmd_No_Cs 1;
BA_ "U_T6_MCA_MY2020_Rx" SG_ 92 TrnGearCmd_No_Cs 1;
BA_ "U_CD542_MY2021_Rx" SG_ 92 TrnGearCmd_No_Cs 1;
BA_ "U_U55X_MY2022_Rx" SG_ 92 TrnGearCmd_No_Cs 1;
BA_ "U_CD764_MY2022_Rx" SG_ 92 TrnGearCmd_No_Cs 1;
BA_ "ContentDependant" SG_ 92 TrnValidGear_D_Cnfm 1;
BA_ "U_CX727_MY2021_Rx" SG_ 92 TrnValidGear_D_Cnfm 1;
BA_ "U_P702_MY2021_Rx" SG_ 92 TrnValidGear_D_Cnfm 1;
BA_ "U_T6_MCA_MY2020_Rx" SG_ 92 TrnValidGear_D_Cnfm 1;
BA_ "U_CD542_MY2021_Rx" SG_ 92 TrnValidGear_D_Cnfm 1;
BA_ "U_U55X_MY2022_Rx" SG_ 92 TrnValidGear_D_Cnfm 1;
BA_ "U_CD764_MY2022_Rx" SG_ 92 TrnValidGear_D_Cnfm 1;
BA_ "ContentDependant" SG_ 92 TrnNtrlTowCmd_D_Actl 1;
BA_ "U_CX727_MY2021_Rx" SG_ 92 TrnNtrlTowCmd_D_Actl 1;
BA_ "U_P702_MY2021_Rx" SG_ 92 TrnNtrlTowCmd_D_Actl 1;
BA_ "U_T6_MCA_MY2020_Rx" SG_ 92 TrnNtrlTowCmd_D_Actl 1;
BA_ "U_CD542_MY2021_Rx" SG_ 92 TrnNtrlTowCmd_D_Actl 1;
BA_ "U_U55X_MY2022_Rx" SG_ 92 TrnNtrlTowCmd_D_Actl 1;
BA_ "U_CD764_MY2022_Rx" SG_ 92 TrnNtrlTowCmd_D_Actl 1;
BA_ "ContentDependant" SG_ 92 TrnGearCmd_Pc_ActlPt 1;
BA_ "U_CX727_MY2021_Rx" SG_ 92 TrnGearCmd_Pc_ActlPt 1;
BA_ "U_P702_MY2021_Rx" SG_ 92 TrnGearCmd_Pc_ActlPt 1;
BA_ "U_T6_MCA_MY2020_Rx" SG_ 92 TrnGearCmd_Pc_ActlPt 1;
BA_ "U_CD542_MY2021_Rx" SG_ 92 TrnGearCmd_Pc_ActlPt 1;
BA_ "U_U55X_MY2022_Rx" SG_ 92 TrnGearCmd_Pc_ActlPt 1;
BA_ "U_CD764_MY2022_Rx" SG_ 92 TrnGearCmd_Pc_ActlPt 1;
BA_ "ContentDependant" SG_ 92 TrnGear_D_RqPt 1;
BA_ "U_CX727_MY2021_Rx" SG_ 92 TrnGear_D_RqPt 1;
BA_ "U_P702_MY2021_Rx" SG_ 92 TrnGear_D_RqPt 1;
BA_ "U_T6_MCA_MY2020_Rx" SG_ 92 TrnGear_D_RqPt 1;
BA_ "U_CD542_MY2021_Rx" SG_ 92 TrnGear_D_RqPt 1;
BA_ "U_U55X_MY2022_Rx" SG_ 92 TrnGear_D_RqPt 1;
BA_ "U_CD764_MY2022_Rx" SG_ 92 TrnGear_D_RqPt 1;
BA_ "ContentDependant" SG_ 92 TrnCmdState_B_Actl 1;
BA_ "U_CX727_MY2021_Rx" SG_ 92 TrnCmdState_B_Actl 1;
BA_ "U_P702_MY2021_Rx" SG_ 92 TrnCmdState_B_Actl 1;
BA_ "U_T6_MCA_MY2020_Rx" SG_ 92 TrnCmdState_B_Actl 1;
BA_ "U_CD542_MY2021_Rx" SG_ 92 TrnCmdState_B_Actl 1;
BA_ "U_U55X_MY2022_Rx" SG_ 92 TrnCmdState_B_Actl 1;
BA_ "U_CD764_MY2022_Rx" SG_ 92 TrnCmdState_B_Actl 1;
BA_ "ContentDependant" SG_ 92 TrnCmdCnt_B_Actl 1;
BA_ "U_CX727_MY2021_Rx" SG_ 92 TrnCmdCnt_B_Actl 1;
BA_ "U_P702_MY2021_Rx" SG_ 92 TrnCmdCnt_B_Actl 1;
BA_ "U_T6_MCA_MY2020_Rx" SG_ 92 TrnCmdCnt_B_Actl 1;
BA_ "U_CD542_MY2021_Rx" SG_ 92 TrnCmdCnt_B_Actl 1;
BA_ "U_U55X_MY2022_Rx" SG_ 92 TrnCmdCnt_B_Actl 1;
BA_ "U_CD764_MY2022_Rx" SG_ 92 TrnCmdCnt_B_Actl 1;
BA_ "GenSigStartValueInteger" SG_ 92 PrkBrkActv_D_RqTrnGear 1;
BA_ "ContentDependant" SG_ 92 PrkBrkActv_D_RqTrnGear 1;
BA_ "GenSigStartValue" SG_ 92 PrkBrkActv_D_RqTrnGear 1;
BA_ "U_CX727_MY2021_Rx" SG_ 92 PrkBrkActv_D_RqTrnGear 1;
BA_ "U_P702_MY2021_Rx" SG_ 92 PrkBrkActv_D_RqTrnGear 1;
BA_ "U_T6_MCA_MY2020_Rx" SG_ 92 PrkBrkActv_D_RqTrnGear 1;
BA_ "U_CD542_MY2021_Rx" SG_ 92 PrkBrkActv_D_RqTrnGear 1;
BA_ "U_U55X_MY2022_Rx" SG_ 92 PrkBrkActv_D_RqTrnGear 1;
BA_ "U_CD764_MY2022_Rx" SG_ 92 PrkBrkActv_D_RqTrnGear 1;
BA_ "ContentDependant" SG_ 92 TrnGearMsgTxt_D_Rq 1;
BA_ "ContentDependant" SG_ 92 TrnGearCmd_No_Cnt 1;
BA_ "MetaData" SG_ 92 TrnGearCmd_No_Cnt 1;
BA_ "U_CX727_MY2021_Rx" SG_ 92 TrnGearCmd_No_Cnt 1;
BA_ "U_P702_MY2021_Rx" SG_ 92 TrnGearCmd_No_Cnt 1;
BA_ "U_T6_MCA_MY2020_Rx" SG_ 92 TrnGearCmd_No_Cnt 1;
BA_ "U_CD542_MY2021_Rx" SG_ 92 TrnGearCmd_No_Cnt 1;
BA_ "U_U55X_MY2022_Rx" SG_ 92 TrnGearCmd_No_Cnt 1;
BA_ "U_CD764_MY2022_Rx" SG_ 92 TrnGearCmd_No_Cnt 1;
BA_ "ContentDependant" SG_ 360 GsmSrvcRqd_B_Rq 1;
BA_ "U_CX727_MY2021_Tx" SG_ 360 GsmSrvcRqd_B_Rq 1;
BA_ "U_P702_MY2021_Tx" SG_ 360 GsmSrvcRqd_B_Rq 1;
BA_ "U_T6_MCA_MY2020_Tx" SG_ 360 GsmSrvcRqd_B_Rq 1;
BA_ "U_CD542_MY2021_Tx" SG_ 360 GsmSrvcRqd_B_Rq 1;
BA_ "U_U55X_MY2022_Tx" SG_ 360 GsmSrvcRqd_B_Rq 1;
BA_ "U_CD764_MY2022_Tx" SG_ 360 GsmSrvcRqd_B_Rq 1;
BA_ "ContentDependant" SG_ 360 TrnTrcmPwmSig_D_Actl 1;
BA_ "U_CD542_MY2021_Tx" SG_ 360 TrnTrcmPwmSig_D_Actl 1;
BA_ "ContentDependant" SG_ 360 TrnGearPwmFalt_B_Actl 1;
BA_ "U_CX727_MY2021_Tx" SG_ 360 TrnGearPwmFalt_B_Actl 1;
BA_ "U_P702_MY2021_Tx" SG_ 360 TrnGearPwmFalt_B_Actl 1;
BA_ "U_T6_MCA_MY2020_Tx" SG_ 360 TrnGearPwmFalt_B_Actl 1;
BA_ "U_CD542_MY2021_Tx" SG_ 360 TrnGearPwmFalt_B_Actl 1;
BA_ "U_CD764_MY2022_Tx" SG_ 360 TrnGearPwmFalt_B_Actl 1;
BA_ "ContentDependant" SG_ 360 GearButtnStuck_B_Actl 1;
BA_ "U_CX727_MY2021_Tx" SG_ 360 GearButtnStuck_B_Actl 1;
BA_ "U_P702_MY2021_Tx" SG_ 360 GearButtnStuck_B_Actl 1;
BA_ "U_T6_MCA_MY2020_Tx" SG_ 360 GearButtnStuck_B_Actl 1;
BA_ "U_CD542_MY2021_Tx" SG_ 360 GearButtnStuck_B_Actl 1;
BA_ "U_U55X_MY2022_Tx" SG_ 360 GearButtnStuck_B_Actl 1;
BA_ "U_CD764_MY2022_Tx" SG_ 360 GearButtnStuck_B_Actl 1;
BA_ "ContentDependant" SG_ 90 TrnGsmNtmState_D_Actl 1;
BA_ "U_CX727_MY2021_Tx" SG_ 90 TrnGsmNtmState_D_Actl 1;
BA_ "U_P702_MY2021_Tx" SG_ 90 TrnGsmNtmState_D_Actl 1;
BA_ "U_T6_MCA_MY2020_Tx" SG_ 90 TrnGsmNtmState_D_Actl 1;
BA_ "U_CD542_MY2021_Tx" SG_ 90 TrnGsmNtmState_D_Actl 1;
BA_ "U_U55X_MY2022_Tx" SG_ 90 TrnGsmNtmState_D_Actl 1;
BA_ "U_CD764_MY2022_Tx" SG_ 90 TrnGsmNtmState_D_Actl 1;
BA_ "GenSigStartValueInteger" SG_ 90 DrQltyDrv_D_StatGsm 6;
BA_ "ContentDependant" SG_ 90 DrQltyDrv_D_StatGsm 1;
BA_ "GenSigStartValue" SG_ 90 DrQltyDrv_D_StatGsm 6;
BA_ "U_CX727_MY2021_Rx" SG_ 90 DrQltyDrv_D_StatGsm 1;
BA_ "U_P702_MY2021_Rx" SG_ 90 DrQltyDrv_D_StatGsm 1;
BA_ "U_CX727_MY2021_Tx" SG_ 90 DrQltyDrv_D_StatGsm 1;
BA_ "U_P702_MY2021_Tx" SG_ 90 DrQltyDrv_D_StatGsm 1;
BA_ "U_T6_MCA_MY2020_Tx" SG_ 90 DrQltyDrv_D_StatGsm 1;
BA_ "U_CD542_MY2021_Tx" SG_ 90 DrQltyDrv_D_StatGsm 1;
BA_ "U_U55X_MY2022_Tx" SG_ 90 DrQltyDrv_D_StatGsm 1;
BA_ "U_CD764_MY2022_Tx" SG_ 90 DrQltyDrv_D_StatGsm 1;
BA_ "ContentDependant" SG_ 90 TrnBtsiOvrrd_B_Stat 1;
BA_ "U_CX727_MY2021_Tx" SG_ 90 TrnBtsiOvrrd_B_Stat 1;
BA_ "U_P702_MY2021_Tx" SG_ 90 TrnBtsiOvrrd_B_Stat 1;
BA_ "U_T6_MCA_MY2020_Tx" SG_ 90 TrnBtsiOvrrd_B_Stat 1;
BA_ "U_CD542_MY2021_Tx" SG_ 90 TrnBtsiOvrrd_B_Stat 1;
BA_ "U_U55X_MY2022_Tx" SG_ 90 TrnBtsiOvrrd_B_Stat 1;
BA_ "U_CD764_MY2022_Tx" SG_ 90 TrnBtsiOvrrd_B_Stat 1;
BA_ "GenSigSendType" SG_ 90 GsmGearMsgTxt_D_Rq 3;
BA_ "U_CX727_MY2021_Tx" SG_ 90 GsmGearMsgTxt_D_Rq 1;
BA_ "U_P702_MY2021_Tx" SG_ 90 GsmGearMsgTxt_D_Rq 1;
BA_ "U_T6_MCA_MY2020_Tx" SG_ 90 GsmGearMsgTxt_D_Rq 1;
BA_ "U_CD542_MY2021_Tx" SG_ 90 GsmGearMsgTxt_D_Rq 1;
BA_ "U_U55X_MY2022_Tx" SG_ 90 GsmGearMsgTxt_D_Rq 1;
BA_ "U_CD764_MY2022_Tx" SG_ 90 GsmGearMsgTxt_D_Rq 1;
BA_ "GenSigStartValueInteger" SG_ 90 TrnRng_D_RqGsm 14;
BA_ "GenSigStartValue" SG_ 90 TrnRng_D_RqGsm 14;
BA_ "GenSigSendType" SG_ 90 TrnRng_D_RqGsm 3;
BA_ "U_CX727_MY2021_Tx" SG_ 90 TrnRng_D_RqGsm 1;
BA_ "U_P702_MY2021_Tx" SG_ 90 TrnRng_D_RqGsm 1;
BA_ "U_T6_MCA_MY2020_Tx" SG_ 90 TrnRng_D_RqGsm 1;
BA_ "U_CD542_MY2021_Tx" SG_ 90 TrnRng_D_RqGsm 1;
BA_ "U_U55X_MY2022_Tx" SG_ 90 TrnRng_D_RqGsm 1;
BA_ "U_CD764_MY2022_Tx" SG_ 90 TrnRng_D_RqGsm 1;
BA_ "GenSigSendType" SG_ 90 PrkBrkActv_D_RqGsmGear 3;
BA_ "U_CX727_MY2021_Tx" SG_ 90 PrkBrkActv_D_RqGsmGear 1;
BA_ "U_P702_MY2021_Tx" SG_ 90 PrkBrkActv_D_RqGsmGear 1;
BA_ "U_T6_MCA_MY2020_Tx" SG_ 90 PrkBrkActv_D_RqGsmGear 1;
BA_ "U_CD542_MY2021_Tx" SG_ 90 PrkBrkActv_D_RqGsmGear 1;
BA_ "U_U55X_MY2022_Tx" SG_ 90 PrkBrkActv_D_RqGsmGear 1;
BA_ "U_CD764_MY2022_Tx" SG_ 90 PrkBrkActv_D_RqGsmGear 1;
BA_ "ContentDependant" SG_ 90 TrnValidGearRq_D_Stat 1;
BA_ "U_CX727_MY2021_Tx" SG_ 90 TrnValidGearRq_D_Stat 1;
BA_ "U_P702_MY2021_Tx" SG_ 90 TrnValidGearRq_D_Stat 1;
BA_ "U_T6_MCA_MY2020_Tx" SG_ 90 TrnValidGearRq_D_Stat 1;
BA_ "U_CD542_MY2021_Tx" SG_ 90 TrnValidGearRq_D_Stat 1;
BA_ "U_U55X_MY2022_Tx" SG_ 90 TrnValidGearRq_D_Stat 1;
BA_ "U_CD764_MY2022_Tx" SG_ 90 TrnValidGearRq_D_Stat 1;
BA_ "ContentDependant" SG_ 90 TrnGearRqCnt_B_Actl 1;
BA_ "GenSigSendType" SG_ 90 TrnGearRqCnt_B_Actl 3;
BA_ "U_CX727_MY2021_Tx" SG_ 90 TrnGearRqCnt_B_Actl 1;
BA_ "U_P702_MY2021_Tx" SG_ 90 TrnGearRqCnt_B_Actl 1;
BA_ "U_T6_MCA_MY2020_Tx" SG_ 90 TrnGearRqCnt_B_Actl 1;
BA_ "U_CD542_MY2021_Tx" SG_ 90 TrnGearRqCnt_B_Actl 1;
BA_ "U_U55X_MY2022_Tx" SG_ 90 TrnGearRqCnt_B_Actl 1;
BA_ "U_CD764_MY2022_Tx" SG_ 90 TrnGearRqCnt_B_Actl 1;
BA_ "WakeupSignal" SG_ 90 TrnGearButtn_U_Actl 1;
BA_ "ContentDependant" SG_ 90 TrnGearButtn_U_Actl 1;
BA_ "U_CX727_MY2021_Tx" SG_ 90 TrnGearButtn_U_Actl 1;
BA_ "U_P702_MY2021_Tx" SG_ 90 TrnGearButtn_U_Actl 1;
BA_ "U_T6_MCA_MY2020_Tx" SG_ 90 TrnGearButtn_U_Actl 1;
BA_ "U_CD542_MY2021_Tx" SG_ 90 TrnGearButtn_U_Actl 1;
BA_ "U_U55X_MY2022_Tx" SG_ 90 TrnGearButtn_U_Actl 1;
BA_ "U_CD764_MY2022_Tx" SG_ 90 TrnGearButtn_U_Actl 1;
BA_ "WakeupSignal" SG_ 90 TrnGearButtn_B_ActlR2 1;
BA_ "ContentDependant" SG_ 90 TrnGearButtn_B_ActlR2 1;
BA_ "U_CX727_MY2021_Tx" SG_ 90 TrnGearButtn_B_ActlR2 1;
BA_ "U_P702_MY2021_Tx" SG_ 90 TrnGearButtn_B_ActlR2 1;
BA_ "U_T6_MCA_MY2020_Tx" SG_ 90 TrnGearButtn_B_ActlR2 1;
BA_ "U_CD542_MY2021_Tx" SG_ 90 TrnGearButtn_B_ActlR2 1;
BA_ "U_U55X_MY2022_Tx" SG_ 90 TrnGearButtn_B_ActlR2 1;
BA_ "U_CD764_MY2022_Tx" SG_ 90 TrnGearButtn_B_ActlR2 1;
BA_ "WakeupSignal" SG_ 90 TrnGearButtn_B_ActlR1 1;
BA_ "ContentDependant" SG_ 90 TrnGearButtn_B_ActlR1 1;
BA_ "U_CX727_MY2021_Tx" SG_ 90 TrnGearButtn_B_ActlR1 1;
BA_ "U_P702_MY2021_Tx" SG_ 90 TrnGearButtn_B_ActlR1 1;
BA_ "U_T6_MCA_MY2020_Tx" SG_ 90 TrnGearButtn_B_ActlR1 1;
BA_ "U_CD542_MY2021_Tx" SG_ 90 TrnGearButtn_B_ActlR1 1;
BA_ "U_U55X_MY2022_Tx" SG_ 90 TrnGearButtn_B_ActlR1 1;
BA_ "U_CD764_MY2022_Tx" SG_ 90 TrnGearButtn_B_ActlR1 1;
BA_ "WakeupSignal" SG_ 90 TrnGearButtn_B_ActlR0 1;
BA_ "ContentDependant" SG_ 90 TrnGearButtn_B_ActlR0 1;
BA_ "U_CX727_MY2021_Tx" SG_ 90 TrnGearButtn_B_ActlR0 1;
BA_ "U_P702_MY2021_Tx" SG_ 90 TrnGearButtn_B_ActlR0 1;
BA_ "U_T6_MCA_MY2020_Tx" SG_ 90 TrnGearButtn_B_ActlR0 1;
BA_ "U_CD542_MY2021_Tx" SG_ 90 TrnGearButtn_B_ActlR0 1;
BA_ "U_U55X_MY2022_Tx" SG_ 90 TrnGearButtn_B_ActlR0 1;
BA_ "U_CD764_MY2022_Tx" SG_ 90 TrnGearButtn_B_ActlR0 1;
BA_ "WakeupSignal" SG_ 90 TrnGearButtn_B_ActlP2 1;
BA_ "ContentDependant" SG_ 90 TrnGearButtn_B_ActlP2 1;
BA_ "U_CX727_MY2021_Tx" SG_ 90 TrnGearButtn_B_ActlP2 1;
BA_ "U_P702_MY2021_Tx" SG_ 90 TrnGearButtn_B_ActlP2 1;
BA_ "U_T6_MCA_MY2020_Tx" SG_ 90 TrnGearButtn_B_ActlP2 1;
BA_ "U_CD542_MY2021_Tx" SG_ 90 TrnGearButtn_B_ActlP2 1;
BA_ "U_U55X_MY2022_Tx" SG_ 90 TrnGearButtn_B_ActlP2 1;
BA_ "U_CD764_MY2022_Tx" SG_ 90 TrnGearButtn_B_ActlP2 1;
BA_ "WakeupSignal" SG_ 90 TrnGearButtn_B_ActlP1 1;
BA_ "ContentDependant" SG_ 90 TrnGearButtn_B_ActlP1 1;
BA_ "U_CX727_MY2021_Tx" SG_ 90 TrnGearButtn_B_ActlP1 1;
BA_ "U_P702_MY2021_Tx" SG_ 90 TrnGearButtn_B_ActlP1 1;
BA_ "U_T6_MCA_MY2020_Tx" SG_ 90 TrnGearButtn_B_ActlP1 1;
BA_ "U_CD542_MY2021_Tx" SG_ 90 TrnGearButtn_B_ActlP1 1;
BA_ "U_U55X_MY2022_Tx" SG_ 90 TrnGearButtn_B_ActlP1 1;
BA_ "U_CD764_MY2022_Tx" SG_ 90 TrnGearButtn_B_ActlP1 1;
BA_ "WakeupSignal" SG_ 90 TrnGearButtn_B_ActlP0 1;
BA_ "ContentDependant" SG_ 90 TrnGearButtn_B_ActlP0 1;
BA_ "U_CX727_MY2021_Tx" SG_ 90 TrnGearButtn_B_ActlP0 1;
BA_ "U_P702_MY2021_Tx" SG_ 90 TrnGearButtn_B_ActlP0 1;
BA_ "U_T6_MCA_MY2020_Tx" SG_ 90 TrnGearButtn_B_ActlP0 1;
BA_ "U_CD542_MY2021_Tx" SG_ 90 TrnGearButtn_B_ActlP0 1;
BA_ "U_U55X_MY2022_Tx" SG_ 90 TrnGearButtn_B_ActlP0 1;
BA_ "U_CD764_MY2022_Tx" SG_ 90 TrnGearButtn_B_ActlP0 1;
BA_ "WakeupSignal" SG_ 90 TrnGearButtn_B_ActlN2 1;
BA_ "ContentDependant" SG_ 90 TrnGearButtn_B_ActlN2 1;
BA_ "U_CX727_MY2021_Tx" SG_ 90 TrnGearButtn_B_ActlN2 1;
BA_ "U_P702_MY2021_Tx" SG_ 90 TrnGearButtn_B_ActlN2 1;
BA_ "U_T6_MCA_MY2020_Tx" SG_ 90 TrnGearButtn_B_ActlN2 1;
BA_ "U_CD542_MY2021_Tx" SG_ 90 TrnGearButtn_B_ActlN2 1;
BA_ "U_U55X_MY2022_Tx" SG_ 90 TrnGearButtn_B_ActlN2 1;
BA_ "U_CD764_MY2022_Tx" SG_ 90 TrnGearButtn_B_ActlN2 1;
BA_ "WakeupSignal" SG_ 90 TrnGearButtn_B_ActlN1 1;
BA_ "ContentDependant" SG_ 90 TrnGearButtn_B_ActlN1 1;
BA_ "U_CX727_MY2021_Tx" SG_ 90 TrnGearButtn_B_ActlN1 1;
BA_ "U_P702_MY2021_Tx" SG_ 90 TrnGearButtn_B_ActlN1 1;
BA_ "U_T6_MCA_MY2020_Tx" SG_ 90 TrnGearButtn_B_ActlN1 1;
BA_ "U_CD542_MY2021_Tx" SG_ 90 TrnGearButtn_B_ActlN1 1;
BA_ "U_U55X_MY2022_Tx" SG_ 90 TrnGearButtn_B_ActlN1 1;
BA_ "U_CD764_MY2022_Tx" SG_ 90 TrnGearButtn_B_ActlN1 1;
BA_ "WakeupSignal" SG_ 90 TrnGearButtn_B_ActlN0 1;
BA_ "ContentDependant" SG_ 90 TrnGearButtn_B_ActlN0 1;
BA_ "U_CX727_MY2021_Tx" SG_ 90 TrnGearButtn_B_ActlN0 1;
BA_ "U_P702_MY2021_Tx" SG_ 90 TrnGearButtn_B_ActlN0 1;
BA_ "U_T6_MCA_MY2020_Tx" SG_ 90 TrnGearButtn_B_ActlN0 1;
BA_ "U_CD542_MY2021_Tx" SG_ 90 TrnGearButtn_B_ActlN0 1;
BA_ "U_U55X_MY2022_Tx" SG_ 90 TrnGearButtn_B_ActlN0 1;
BA_ "U_CD764_MY2022_Tx" SG_ 90 TrnGearButtn_B_ActlN0 1;
BA_ "WakeupSignal" SG_ 90 TrnGearButtn_B_ActlM2 1;
BA_ "ContentDependant" SG_ 90 TrnGearButtn_B_ActlM2 1;
BA_ "U_CX727_MY2021_Tx" SG_ 90 TrnGearButtn_B_ActlM2 1;
BA_ "U_P702_MY2021_Tx" SG_ 90 TrnGearButtn_B_ActlM2 1;
BA_ "U_T6_MCA_MY2020_Tx" SG_ 90 TrnGearButtn_B_ActlM2 1;
BA_ "U_CD542_MY2021_Tx" SG_ 90 TrnGearButtn_B_ActlM2 1;
BA_ "U_U55X_MY2022_Tx" SG_ 90 TrnGearButtn_B_ActlM2 1;
BA_ "U_CD764_MY2022_Tx" SG_ 90 TrnGearButtn_B_ActlM2 1;
BA_ "WakeupSignal" SG_ 90 TrnGearButtn_B_ActlM1 1;
BA_ "ContentDependant" SG_ 90 TrnGearButtn_B_ActlM1 1;
BA_ "U_CX727_MY2021_Tx" SG_ 90 TrnGearButtn_B_ActlM1 1;
BA_ "U_P702_MY2021_Tx" SG_ 90 TrnGearButtn_B_ActlM1 1;
BA_ "U_T6_MCA_MY2020_Tx" SG_ 90 TrnGearButtn_B_ActlM1 1;
BA_ "U_CD542_MY2021_Tx" SG_ 90 TrnGearButtn_B_ActlM1 1;
BA_ "U_U55X_MY2022_Tx" SG_ 90 TrnGearButtn_B_ActlM1 1;
BA_ "U_CD764_MY2022_Tx" SG_ 90 TrnGearButtn_B_ActlM1 1;
BA_ "WakeupSignal" SG_ 90 TrnGearButtn_B_ActlM0 1;
BA_ "ContentDependant" SG_ 90 TrnGearButtn_B_ActlM0 1;
BA_ "U_CX727_MY2021_Tx" SG_ 90 TrnGearButtn_B_ActlM0 1;
BA_ "U_P702_MY2021_Tx" SG_ 90 TrnGearButtn_B_ActlM0 1;
BA_ "U_T6_MCA_MY2020_Tx" SG_ 90 TrnGearButtn_B_ActlM0 1;
BA_ "U_CD542_MY2021_Tx" SG_ 90 TrnGearButtn_B_ActlM0 1;
BA_ "U_U55X_MY2022_Tx" SG_ 90 TrnGearButtn_B_ActlM0 1;
BA_ "U_CD764_MY2022_Tx" SG_ 90 TrnGearButtn_B_ActlM0 1;
BA_ "WakeupSignal" SG_ 90 TrnGearButtn_B_ActlD2 1;
BA_ "ContentDependant" SG_ 90 TrnGearButtn_B_ActlD2 1;
BA_ "U_CX727_MY2021_Tx" SG_ 90 TrnGearButtn_B_ActlD2 1;
BA_ "U_P702_MY2021_Tx" SG_ 90 TrnGearButtn_B_ActlD2 1;
BA_ "U_T6_MCA_MY2020_Tx" SG_ 90 TrnGearButtn_B_ActlD2 1;
BA_ "U_CD542_MY2021_Tx" SG_ 90 TrnGearButtn_B_ActlD2 1;
BA_ "U_U55X_MY2022_Tx" SG_ 90 TrnGearButtn_B_ActlD2 1;
BA_ "U_CD764_MY2022_Tx" SG_ 90 TrnGearButtn_B_ActlD2 1;
BA_ "WakeupSignal" SG_ 90 TrnGearButtn_B_ActlD1 1;
BA_ "ContentDependant" SG_ 90 TrnGearButtn_B_ActlD1 1;
BA_ "U_CX727_MY2021_Tx" SG_ 90 TrnGearButtn_B_ActlD1 1;
BA_ "U_P702_MY2021_Tx" SG_ 90 TrnGearButtn_B_ActlD1 1;
BA_ "U_T6_MCA_MY2020_Tx" SG_ 90 TrnGearButtn_B_ActlD1 1;
BA_ "U_CD542_MY2021_Tx" SG_ 90 TrnGearButtn_B_ActlD1 1;
BA_ "U_U55X_MY2022_Tx" SG_ 90 TrnGearButtn_B_ActlD1 1;
BA_ "U_CD764_MY2022_Tx" SG_ 90 TrnGearButtn_B_ActlD1 1;
BA_ "WakeupSignal" SG_ 90 TrnGearButtn_B_ActlD0 1;
BA_ "ContentDependant" SG_ 90 TrnGearButtn_B_ActlD0 1;
BA_ "U_CX727_MY2021_Tx" SG_ 90 TrnGearButtn_B_ActlD0 1;
BA_ "U_P702_MY2021_Tx" SG_ 90 TrnGearButtn_B_ActlD0 1;
BA_ "U_T6_MCA_MY2020_Tx" SG_ 90 TrnGearButtn_B_ActlD0 1;
BA_ "U_CD542_MY2021_Tx" SG_ 90 TrnGearButtn_B_ActlD0 1;
BA_ "U_U55X_MY2022_Tx" SG_ 90 TrnGearButtn_B_ActlD0 1;
BA_ "U_CD764_MY2022_Tx" SG_ 90 TrnGearButtn_B_ActlD0 1;
BA_ "ContentDependant" SG_ 90 TrnGear_No_Cs 1;
BA_ "MetaData" SG_ 90 TrnGear_No_Cs 1;
BA_ "U_CX727_MY2021_Tx" SG_ 90 TrnGear_No_Cs 1;
BA_ "U_P702_MY2021_Tx" SG_ 90 TrnGear_No_Cs 1;
BA_ "U_T6_MCA_MY2020_Tx" SG_ 90 TrnGear_No_Cs 1;
BA_ "U_CD542_MY2021_Tx" SG_ 90 TrnGear_No_Cs 1;
BA_ "U_U55X_MY2022_Tx" SG_ 90 TrnGear_No_Cs 1;
BA_ "U_CD764_MY2022_Tx" SG_ 90 TrnGear_No_Cs 1;
BA_ "ContentDependant" SG_ 90 TrnGear_No_Cnt 1;
BA_ "MetaData" SG_ 90 TrnGear_No_Cnt 1;
BA_ "U_CX727_MY2021_Tx" SG_ 90 TrnGear_No_Cnt 1;
BA_ "U_P702_MY2021_Tx" SG_ 90 TrnGear_No_Cnt 1;
BA_ "U_T6_MCA_MY2020_Tx" SG_ 90 TrnGear_No_Cnt 1;
BA_ "U_CD542_MY2021_Tx" SG_ 90 TrnGear_No_Cnt 1;
BA_ "U_U55X_MY2022_Tx" SG_ 90 TrnGear_No_Cnt 1;
BA_ "U_CD764_MY2022_Tx" SG_ 90 TrnGear_No_Cnt 1;
BA_ "WakeupSignal" SG_ 90 TrnGear_D_RqDrv 1;
BA_ "ContentDependant" SG_ 90 TrnGear_D_RqDrv 1;
BA_ "GenSigSendType" SG_ 90 TrnGear_D_RqDrv 3;
BA_ "U_CX727_MY2021_Tx" SG_ 90 TrnGear_D_RqDrv 1;
BA_ "U_P702_MY2021_Tx" SG_ 90 TrnGear_D_RqDrv 1;
BA_ "U_T6_MCA_MY2020_Tx" SG_ 90 TrnGear_D_RqDrv 1;
BA_ "U_CD542_MY2021_Tx" SG_ 90 TrnGear_D_RqDrv 1;
BA_ "U_U55X_MY2022_Tx" SG_ 90 TrnGear_D_RqDrv 1;
BA_ "U_CD764_MY2022_Tx" SG_ 90 TrnGear_D_RqDrv 1;
BA_ "ContentDependant" SG_ 90 BrkSwtchPos_B_ActlGsm 1;
BA_ "U_CX727_MY2021_Tx" SG_ 90 BrkSwtchPos_B_ActlGsm 1;
BA_ "U_P702_MY2021_Tx" SG_ 90 BrkSwtchPos_B_ActlGsm 1;
BA_ "U_T6_MCA_MY2020_Tx" SG_ 90 BrkSwtchPos_B_ActlGsm 1;
BA_ "U_CD542_MY2021_Tx" SG_ 90 BrkSwtchPos_B_ActlGsm 1;
BA_ "U_U55X_MY2022_Tx" SG_ 90 BrkSwtchPos_B_ActlGsm 1;
BA_ "U_CD764_MY2022_Tx" SG_ 90 BrkSwtchPos_B_ActlGsm 1;
BA_ "GenSigSendType" SG_ 1842 TesterPhysicalReqGSM 3;
BA_ "U_CX727_MY2021_Rx" SG_ 1842 TesterPhysicalReqGSM 1;
BA_ "U_P702_MY2021_Rx" SG_ 1842 TesterPhysicalReqGSM 1;
BA_ "U_T6_MCA_MY2020_Rx" SG_ 1842 TesterPhysicalReqGSM 1;
BA_ "U_CD542_MY2021_Rx" SG_ 1842 TesterPhysicalReqGSM 1;
BA_ "U_U55X_MY2022_Rx" SG_ 1842 TesterPhysicalReqGSM 1;
BA_ "U_CD764_MY2022_Rx" SG_ 1842 TesterPhysicalReqGSM 1;
BA_ "GenSigSendType" SG_ 1850 TesterPhysicalResGSM 3;
BA_ "U_CX727_MY2021_Tx" SG_ 1850 TesterPhysicalResGSM 1;
BA_ "U_P702_MY2021_Tx" SG_ 1850 TesterPhysicalResGSM 1;
BA_ "U_T6_MCA_MY2020_Tx" SG_ 1850 TesterPhysicalResGSM 1;
BA_ "U_CD542_MY2021_Tx" SG_ 1850 TesterPhysicalResGSM 1;
BA_ "U_U55X_MY2022_Tx" SG_ 1850 TesterPhysicalResGSM 1;
BA_ "U_CD764_MY2022_Tx" SG_ 1850 TesterPhysicalResGSM 1;
BA_ "U_CX727_MY2021_Rx" SG_ 512 PtDrvMde_D_Stat 1;
BA_ "U_P702_MY2021_Rx" SG_ 512 PtDrvMde_D_Stat 1;
BA_ "ContentDependant" SG_ 512 PrplWhlTotTqRq_No_Cs 1;
BA_ "MetaData" SG_ 512 PrplWhlTotTqRq_No_Cs 1;
BA_ "ContentDependant" SG_ 512 PrplWhlTotTqRq_No_Cnt 1;
BA_ "MetaData" SG_ 512 PrplWhlTotTqRq_No_Cnt 1;
BA_ "ContentDependant" SG_ 512 EngAout_Tq_MxMxN 1;
BA_ "GenSigSendType" SG_ 76 RstrnPsngrOn_D_Stat 3;
BA_ "U_CX727_MY2021_Tx" SG_ 76 RstrnPsngrOn_D_Stat 1;
BA_ "U_T6_MCA_MY2020_Tx" SG_ 76 RstrnPsngrOn_D_Stat 1;
BA_ "U_CD542_MY2021_Tx" SG_ 76 RstrnPsngrOn_D_Stat 1;
BA_ "U_CD764_MY2022_Tx" SG_ 76 RstrnPsngrOn_D_Stat 1;
BA_ "MetaData" SG_ 76 FirstRowBuckle_No_Cs 1;
BA_ "U_T6_MCA_MY2020_Tx" SG_ 76 FirstRowBuckle_No_Cs 1;
BA_ "U_CD542_MY2021_Tx" SG_ 76 FirstRowBuckle_No_Cs 1;
BA_ "U_U55X_MY2022_Tx" SG_ 76 FirstRowBuckle_No_Cs 1;
BA_ "U_CD764_MY2022_Tx" SG_ 76 FirstRowBuckle_No_Cs 1;
BA_ "MetaData" SG_ 76 RCMStatusMsg2_No_Cnt 1;
BA_ "U_T6_MCA_MY2020_Tx" SG_ 76 RCMStatusMsg2_No_Cnt 1;
BA_ "U_CD542_MY2021_Tx" SG_ 76 RCMStatusMsg2_No_Cnt 1;
BA_ "U_U55X_MY2022_Tx" SG_ 76 RCMStatusMsg2_No_Cnt 1;
BA_ "U_CD764_MY2022_Tx" SG_ 76 RCMStatusMsg2_No_Cnt 1;
BA_ "GenSigStartValueInteger" SG_ 76 SecondRowBucklePsngr 3;
BA_ "GenSigStartValue" SG_ 76 SecondRowBucklePsngr 3;
BA_ "GenSigSendType" SG_ 76 SecondRowBucklePsngr 3;
BA_ "U_CX727_MY2021_Tx" SG_ 76 SecondRowBucklePsngr 1;
BA_ "U_P702_MY2021_Tx" SG_ 76 SecondRowBucklePsngr 1;
BA_ "U_T6_MCA_MY2020_Tx" SG_ 76 SecondRowBucklePsngr 1;
BA_ "U_CD542_MY2021_Tx" SG_ 76 SecondRowBucklePsngr 1;
BA_ "U_U55X_MY2022_Tx" SG_ 76 SecondRowBucklePsngr 1;
BA_ "U_CD764_MY2022_Tx" SG_ 76 SecondRowBucklePsngr 1;
BA_ "GenSigStartValueInteger" SG_ 76 SecondRowBuckleMid 3;
BA_ "GenSigStartValue" SG_ 76 SecondRowBuckleMid 3;
BA_ "GenSigSendType" SG_ 76 SecondRowBuckleMid 3;
BA_ "U_CX727_MY2021_Tx" SG_ 76 SecondRowBuckleMid 1;
BA_ "U_P702_MY2021_Tx" SG_ 76 SecondRowBuckleMid 1;
BA_ "U_T6_MCA_MY2020_Tx" SG_ 76 SecondRowBuckleMid 1;
BA_ "U_CD542_MY2021_Tx" SG_ 76 SecondRowBuckleMid 1;
BA_ "U_U55X_MY2022_Tx" SG_ 76 SecondRowBuckleMid 1;
BA_ "U_CD764_MY2022_Tx" SG_ 76 SecondRowBuckleMid 1;
BA_ "GenSigStartValueInteger" SG_ 76 SecondRowBuckleDriver 3;
BA_ "GenSigStartValue" SG_ 76 SecondRowBuckleDriver 3;
BA_ "GenSigSendType" SG_ 76 SecondRowBuckleDriver 3;
BA_ "U_CX727_MY2021_Tx" SG_ 76 SecondRowBuckleDriver 1;
BA_ "U_P702_MY2021_Tx" SG_ 76 SecondRowBuckleDriver 1;
BA_ "U_T6_MCA_MY2020_Tx" SG_ 76 SecondRowBuckleDriver 1;
BA_ "U_CD542_MY2021_Tx" SG_ 76 SecondRowBuckleDriver 1;
BA_ "U_U55X_MY2022_Tx" SG_ 76 SecondRowBuckleDriver 1;
BA_ "U_CD764_MY2022_Tx" SG_ 76 SecondRowBuckleDriver 1;
BA_ "GenSigStartValueInteger" SG_ 76 FirstRowBuckleDriver 3;
BA_ "GenSigStartValue" SG_ 76 FirstRowBuckleDriver 3;
BA_ "GenSigSendType" SG_ 76 FirstRowBuckleDriver 3;
BA_ "U_CX727_MY2021_Rx" SG_ 76 FirstRowBuckleDriver 1;
BA_ "U_P702_MY2021_Rx" SG_ 76 FirstRowBuckleDriver 1;
BA_ "U_T6_MCA_MY2020_Rx" SG_ 76 FirstRowBuckleDriver 1;
BA_ "U_CD542_MY2021_Rx" SG_ 76 FirstRowBuckleDriver 1;
BA_ "U_U55X_MY2022_Rx" SG_ 76 FirstRowBuckleDriver 1;
BA_ "U_CD764_MY2022_Rx" SG_ 76 FirstRowBuckleDriver 1;
BA_ "ECGUsedRxSignal" SG_ 76 FirstRowBuckleDriver 1;
BA_ "U_CX727_MY2021_Tx" SG_ 76 FirstRowBuckleDriver 1;
BA_ "U_P702_MY2021_Tx" SG_ 76 FirstRowBuckleDriver 1;
BA_ "U_T6_MCA_MY2020_Tx" SG_ 76 FirstRowBuckleDriver 1;
BA_ "U_CD542_MY2021_Tx" SG_ 76 FirstRowBuckleDriver 1;
BA_ "U_U55X_MY2022_Tx" SG_ 76 FirstRowBuckleDriver 1;
BA_ "U_CD764_MY2022_Tx" SG_ 76 FirstRowBuckleDriver 1;
BA_ "GenSigSendType" SG_ 76 RILReq 3;
BA_ "U_CX727_MY2021_Tx" SG_ 76 RILReq 1;
BA_ "U_P702_MY2021_Tx" SG_ 76 RILReq 1;
BA_ "U_T6_MCA_MY2020_Tx" SG_ 76 RILReq 1;
BA_ "U_CD542_MY2021_Tx" SG_ 76 RILReq 1;
BA_ "U_U55X_MY2022_Tx" SG_ 76 RILReq 1;
BA_ "U_CD764_MY2022_Tx" SG_ 76 RILReq 1;
BA_ "GenSigStartValueInteger" SG_ 76 FirstRowBucklePsngr 3;
BA_ "GenSigStartValue" SG_ 76 FirstRowBucklePsngr 3;
BA_ "GenSigSendType" SG_ 76 FirstRowBucklePsngr 3;
BA_ "U_CX727_MY2021_Rx" SG_ 76 FirstRowBucklePsngr 1;
BA_ "U_P702_MY2021_Rx" SG_ 76 FirstRowBucklePsngr 1;
BA_ "U_T6_MCA_MY2020_Rx" SG_ 76 FirstRowBucklePsngr 1;
BA_ "U_U55X_MY2022_Rx" SG_ 76 FirstRowBucklePsngr 1;
BA_ "ECGUsedRxSignal" SG_ 76 FirstRowBucklePsngr 1;
BA_ "U_CD542_MY2021_Rx" SG_ 76 FirstRowBucklePsngr 1;
BA_ "U_CD764_MY2022_Rx" SG_ 76 FirstRowBucklePsngr 1;
BA_ "U_CX727_MY2021_Tx" SG_ 76 FirstRowBucklePsngr 1;
BA_ "U_P702_MY2021_Tx" SG_ 76 FirstRowBucklePsngr 1;
BA_ "U_T6_MCA_MY2020_Tx" SG_ 76 FirstRowBucklePsngr 1;
BA_ "U_CD542_MY2021_Tx" SG_ 76 FirstRowBucklePsngr 1;
BA_ "U_U55X_MY2022_Tx" SG_ 76 FirstRowBucklePsngr 1;
BA_ "U_CD764_MY2022_Tx" SG_ 76 FirstRowBucklePsngr 1;
BA_ "WakeupSignal" SG_ 76 RstrnImpactEvntStatus 1;
BA_ "GenSigSendType" SG_ 76 RstrnImpactEvntStatus 3;
BA_ "U_CX727_MY2021_Rx" SG_ 76 RstrnImpactEvntStatus 1;
BA_ "U_P702_MY2021_Rx" SG_ 76 RstrnImpactEvntStatus 1;
BA_ "U_T6_MCA_MY2020_Rx" SG_ 76 RstrnImpactEvntStatus 1;
BA_ "U_U55X_MY2022_Rx" SG_ 76 RstrnImpactEvntStatus 1;
BA_ "ECGUsedRxSignal" SG_ 76 RstrnImpactEvntStatus 1;
BA_ "U_CD542_MY2021_Rx" SG_ 76 RstrnImpactEvntStatus 1;
BA_ "U_CD764_MY2022_Rx" SG_ 76 RstrnImpactEvntStatus 1;
BA_ "U_CX727_MY2021_Tx" SG_ 76 RstrnImpactEvntStatus 1;
BA_ "U_P702_MY2021_Tx" SG_ 76 RstrnImpactEvntStatus 1;
BA_ "U_T6_MCA_MY2020_Tx" SG_ 76 RstrnImpactEvntStatus 1;
BA_ "U_CD542_MY2021_Tx" SG_ 76 RstrnImpactEvntStatus 1;
BA_ "U_U55X_MY2022_Tx" SG_ 76 RstrnImpactEvntStatus 1;
BA_ "U_CD764_MY2022_Tx" SG_ 76 RstrnImpactEvntStatus 1;
BA_ "GenSigStartValueInteger" SG_ 76 PsngrFrntDetct_D_Actl 3;
BA_ "GenSigStartValue" SG_ 76 PsngrFrntDetct_D_Actl 3;
BA_ "GenSigSendType" SG_ 76 PsngrFrntDetct_D_Actl 3;
BA_ "U_CX727_MY2021_Tx" SG_ 76 PsngrFrntDetct_D_Actl 1;
BA_ "U_T6_MCA_MY2020_Tx" SG_ 76 PsngrFrntDetct_D_Actl 1;
BA_ "U_U55X_MY2022_Tx" SG_ 76 PsngrFrntDetct_D_Actl 1;
BA_ "U_CD764_MY2022_Tx" SG_ 76 PsngrFrntDetct_D_Actl 1;
BA_ "GenSigSendType" SG_ 76 EDRTriggerEvntSync 3;
BA_ "U_CX727_MY2021_Rx" SG_ 76 EDRTriggerEvntSync 1;
BA_ "U_P702_MY2021_Rx" SG_ 76 EDRTriggerEvntSync 1;
BA_ "U_T6_MCA_MY2020_Rx" SG_ 76 EDRTriggerEvntSync 1;
BA_ "ECGUsedRxSignal" SG_ 76 EDRTriggerEvntSync 1;
BA_ "U_CD542_MY2021_Rx" SG_ 76 EDRTriggerEvntSync 1;
BA_ "U_CD764_MY2022_Rx" SG_ 76 EDRTriggerEvntSync 1;
BA_ "U_CX727_MY2021_Tx" SG_ 76 EDRTriggerEvntSync 1;
BA_ "U_P702_MY2021_Tx" SG_ 76 EDRTriggerEvntSync 1;
BA_ "U_T6_MCA_MY2020_Tx" SG_ 76 EDRTriggerEvntSync 1;
BA_ "U_CD542_MY2021_Tx" SG_ 76 EDRTriggerEvntSync 1;
BA_ "U_U55X_MY2022_Tx" SG_ 76 EDRTriggerEvntSync 1;
BA_ "U_CD764_MY2022_Tx" SG_ 76 EDRTriggerEvntSync 1;
BA_ "U_CX727_MY2021_Rx" SG_ 120 BpedDrvMsgTxt_B_Dsply_UB 1;
BA_ "U_P702_MY2021_Rx" SG_ 120 BpedDrvMsgTxt_B_Dsply_UB 1;
BA_ "U_T6_MCA_MY2020_Rx" SG_ 120 BpedDrvMsgTxt_B_Dsply_UB 1;
BA_ "U_CD542_MY2021_Rx" SG_ 120 BpedDrvMsgTxt_B_Dsply_UB 1;
BA_ "U_U55X_MY2022_Rx" SG_ 120 BpedDrvMsgTxt_B_Dsply_UB 1;
BA_ "U_CD764_MY2022_Rx" SG_ 120 BpedDrvMsgTxt_B_Dsply_UB 1;
BA_ "GenSigSendType" SG_ 120 BpedDrvMsgTxt_B_Dsply 3;
BA_ "U_CX727_MY2021_Rx" SG_ 120 BpedDrvMsgTxt_B_Dsply 1;
BA_ "U_P702_MY2021_Rx" SG_ 120 BpedDrvMsgTxt_B_Dsply 1;
BA_ "U_T6_MCA_MY2020_Rx" SG_ 120 BpedDrvMsgTxt_B_Dsply 1;
BA_ "U_CD542_MY2021_Rx" SG_ 120 BpedDrvMsgTxt_B_Dsply 1;
BA_ "U_U55X_MY2022_Rx" SG_ 120 BpedDrvMsgTxt_B_Dsply 1;
BA_ "U_CD764_MY2022_Rx" SG_ 120 BpedDrvMsgTxt_B_Dsply 1;
BA_ "U_CX727_MY2021_Rx" SG_ 120 PassRstrnInd_Stat_UB 1;
BA_ "U_P702_MY2021_Rx" SG_ 120 PassRstrnInd_Stat_UB 1;
BA_ "U_T6_MCA_MY2020_Rx" SG_ 120 PassRstrnInd_Stat_UB 1;
BA_ "GenSigSendType" SG_ 120 PassRstrnInd_Stat 3;
BA_ "U_CX727_MY2021_Rx" SG_ 120 PassRstrnInd_Stat 1;
BA_ "U_P702_MY2021_Rx" SG_ 120 PassRstrnInd_Stat 1;
BA_ "U_T6_MCA_MY2020_Rx" SG_ 120 PassRstrnInd_Stat 1;
BA_ "GenSigSendType" SG_ 120 HtrnWarnLamp_B_Dsply 3;
BA_ "U_CX727_MY2021_Rx" SG_ 120 HtrnWarnLamp_B_Dsply 1;
BA_ "U_P702_MY2021_Rx" SG_ 120 HtrnWarnLamp_B_Dsply 1;
BA_ "U_CD542_MY2021_Rx" SG_ 120 HtrnWarnLamp_B_Dsply 1;
BA_ "U_CD764_MY2022_Rx" SG_ 120 HtrnWarnLamp_B_Dsply 1;
BA_ "U_CX727_MY2021_Rx" SG_ 120 ECMMILRequest_UB 1;
BA_ "U_P702_MY2021_Rx" SG_ 120 ECMMILRequest_UB 1;
BA_ "U_T6_MCA_MY2020_Rx" SG_ 120 ECMMILRequest_UB 1;
BA_ "U_CD542_MY2021_Rx" SG_ 120 ECMMILRequest_UB 1;
BA_ "U_U55X_MY2022_Rx" SG_ 120 ECMMILRequest_UB 1;
BA_ "U_CD764_MY2022_Rx" SG_ 120 ECMMILRequest_UB 1;
BA_ "GenSigSendType" SG_ 120 ECMMILRequest 3;
BA_ "U_CX727_MY2021_Rx" SG_ 120 ECMMILRequest 1;
BA_ "U_P702_MY2021_Rx" SG_ 120 ECMMILRequest 1;
BA_ "U_T6_MCA_MY2020_Rx" SG_ 120 ECMMILRequest 1;
BA_ "U_CD542_MY2021_Rx" SG_ 120 ECMMILRequest 1;
BA_ "U_U55X_MY2022_Rx" SG_ 120 ECMMILRequest 1;
BA_ "U_CD764_MY2022_Rx" SG_ 120 ECMMILRequest 1;
BA_ "WakeupSignal" SG_ 120 TrnIpcDsplyMde_D_Stat 1;
BA_ "GenSigSendType" SG_ 120 TrnIpcDsplyMde_D_Stat 3;
BA_ "U_CX727_MY2021_Rx" SG_ 120 TrnIpcDsplyMde_D_Stat 1;
BA_ "U_P702_MY2021_Rx" SG_ 120 TrnIpcDsplyMde_D_Stat 1;
BA_ "U_T6_MCA_MY2020_Rx" SG_ 120 TrnIpcDsplyMde_D_Stat 1;
BA_ "U_CD542_MY2021_Rx" SG_ 120 TrnIpcDsplyMde_D_Stat 1;
BA_ "U_U55X_MY2022_Rx" SG_ 120 TrnIpcDsplyMde_D_Stat 1;
BA_ "U_CD764_MY2022_Rx" SG_ 120 TrnIpcDsplyMde_D_Stat 1;
BA_ "WakeupSignal" SG_ 120 TrnIpcDsplyMde_D_Actl 1;
BA_ "GenSigSendType" SG_ 120 TrnIpcDsplyMde_D_Actl 3;
BA_ "U_CX727_MY2021_Rx" SG_ 120 TrnIpcDsplyMde_D_Actl 1;
BA_ "U_P702_MY2021_Rx" SG_ 120 TrnIpcDsplyMde_D_Actl 1;
BA_ "U_T6_MCA_MY2020_Rx" SG_ 120 TrnIpcDsplyMde_D_Actl 1;
BA_ "U_CD542_MY2021_Rx" SG_ 120 TrnIpcDsplyMde_D_Actl 1;
BA_ "U_U55X_MY2022_Rx" SG_ 120 TrnIpcDsplyMde_D_Actl 1;
BA_ "U_CD764_MY2022_Rx" SG_ 120 TrnIpcDsplyMde_D_Actl 1;
BA_ "GenSigSendType" SG_ 120 EngSrvcRqd_B_Rq 3;
BA_ "U_CX727_MY2021_Rx" SG_ 120 EngSrvcRqd_B_Rq 1;
BA_ "U_P702_MY2021_Rx" SG_ 120 EngSrvcRqd_B_Rq 1;
BA_ "U_T6_MCA_MY2020_Rx" SG_ 120 EngSrvcRqd_B_Rq 1;
BA_ "U_CD542_MY2021_Rx" SG_ 120 EngSrvcRqd_B_Rq 1;
BA_ "U_U55X_MY2022_Rx" SG_ 120 EngSrvcRqd_B_Rq 1;
BA_ "U_CD764_MY2022_Rx" SG_ 120 EngSrvcRqd_B_Rq 1;
BA_ "GenSigSendType" SG_ 120 HtrnSrvcRqd_B_Dsply 3;
BA_ "U_CX727_MY2021_Rx" SG_ 120 HtrnSrvcRqd_B_Dsply 1;
BA_ "U_P702_MY2021_Rx" SG_ 120 HtrnSrvcRqd_B_Dsply 1;
BA_ "U_CD542_MY2021_Rx" SG_ 120 HtrnSrvcRqd_B_Dsply 1;
BA_ "U_CD764_MY2022_Rx" SG_ 120 HtrnSrvcRqd_B_Dsply 1;
BA_ "U_CX727_MY2021_Rx" SG_ 120 TrnIpcDsplyMde_D_Stat_UB 1;
BA_ "U_P702_MY2021_Rx" SG_ 120 TrnIpcDsplyMde_D_Stat_UB 1;
BA_ "U_T6_MCA_MY2020_Rx" SG_ 120 TrnIpcDsplyMde_D_Stat_UB 1;
BA_ "U_CD542_MY2021_Rx" SG_ 120 TrnIpcDsplyMde_D_Stat_UB 1;
BA_ "U_U55X_MY2022_Rx" SG_ 120 TrnIpcDsplyMde_D_Stat_UB 1;
BA_ "U_CD764_MY2022_Rx" SG_ 120 TrnIpcDsplyMde_D_Stat_UB 1;
BA_ "U_CX727_MY2021_Rx" SG_ 120 TrnIpcDsplyMde_D_Actl_UB 1;
BA_ "U_P702_MY2021_Rx" SG_ 120 TrnIpcDsplyMde_D_Actl_UB 1;
BA_ "U_T6_MCA_MY2020_Rx" SG_ 120 TrnIpcDsplyMde_D_Actl_UB 1;
BA_ "U_CD542_MY2021_Rx" SG_ 120 TrnIpcDsplyMde_D_Actl_UB 1;
BA_ "U_U55X_MY2022_Rx" SG_ 120 TrnIpcDsplyMde_D_Actl_UB 1;
BA_ "U_CD764_MY2022_Rx" SG_ 120 TrnIpcDsplyMde_D_Actl_UB 1;
BA_ "GenSigSendType" SG_ 1665 UUDTRCMResponse2 3;
BA_ "U_CX727_MY2021_Tx" SG_ 1665 UUDTRCMResponse2 1;
BA_ "U_P702_MY2021_Tx" SG_ 1665 UUDTRCMResponse2 1;
BA_ "U_T6_MCA_MY2020_Tx" SG_ 1665 UUDTRCMResponse2 1;
BA_ "U_CD542_MY2021_Tx" SG_ 1665 UUDTRCMResponse2 1;
BA_ "U_U55X_MY2022_Tx" SG_ 1665 UUDTRCMResponse2 1;
BA_ "U_CD764_MY2022_Tx" SG_ 1665 UUDTRCMResponse2 1;
BA_ "GenSigSendType" SG_ 2041 TesterPhysicalResPCU 3;
BA_ "U_CX727_MY2021_Tx" SG_ 2041 TesterPhysicalResPCU 1;
BA_ "U_P702_MY2021_Tx" SG_ 2041 TesterPhysicalResPCU 1;
BA_ "U_T6_MCA_MY2020_Tx" SG_ 2041 TesterPhysicalResPCU 1;
BA_ "U_CD542_MY2021_Tx" SG_ 2041 TesterPhysicalResPCU 1;
BA_ "U_U55X_MY2022_Tx" SG_ 2041 TesterPhysicalResPCU 1;
BA_ "U_CD764_MY2022_Tx" SG_ 2041 TesterPhysicalResPCU 1;
VAL_ 1186 AwdDrvMde_D2_Stat 15 "Faulty" 14 "NotUsed_7" 13 "NotUsed_6" 12 "NotUsed_5" 11 "NotUsed_4" 10 "NotUsed_3" 9 "NotUsed_2" 8 "NotUsed_1" 7 "NotAvailable" 6 "TowHaul" 5 "RockCrawl" 4 "Baja" 3 "MudAndSand" 2 "Weather" 1 "Sport" 0 "Normal" ;
VAL_ 1186 FrontDiffLckLamp_D_Rq 3 "Triggered" 2 "Flash" 1 "On" 0 "Off" ;
VAL_ 1186 FrontDiffLckMsg_D_Rq 7 "LockerDisabled" 6 "LockerEnabled" 5 "LockerAccelPedal" 4 "Speed4" 3 "Speed3" 2 "Speed2" 1 "Speed1" 0 "NormalNoMessage" ;
VAL_ 1186 AwdStat2_D_RqDsply 31 "NotUsed_29" 30 "NotUsed_28" 29 "NotUsed_27" 28 "NotUsed_26" 27 "NotUsed_25" 26 "NotUsed_24" 25 "NotUsed_23" 24 "NotUsed_22" 23 "NotUsed_21" 22 "NotUsed_20" 21 "NotUsed_19" 20 "NotUsed_18" 19 "NotUsed_17" 18 "NotUsed_16" 17 "NotUsed_15" 16 "NotUsed_14" 15 "NotUsed_13" 14 "NotUsed_12" 13 "NotUsed_11" 12 "NotUsed_10" 11 "NotUsed_9" 10 "NotUsed_8" 9 "NotUsed_7" 8 "NotUsed_6" 7 "NotUsed_5" 6 "NotUsed_4" 5 "Unavailable4x4Mode" 4 "UnavailableDriveMode" 3 "HillHoldFail" 2 "TCaseOilChanged" 1 "ChangeTCaseOil" 0 "Normal" ;
VAL_ 1186 FrontDiffFalt_D_Stat 3 "Diff_Failed_Closed" 2 "Diff_Failed_Open" 1 "Fault_Non_Specific" 0 "No_Fault" ;
VAL_ 1186 FrontDiffLck_Tq_Actl 16383 "Faulty" 16382 "NoDataExists" ;
VAL_ 1186 SelDrvMdeAwd2_D_Stat 31 "Faulty" 30 "NotUsed_17" 29 "NotUsed_16" 28 "NotUsed_15" 27 "NotUsed_14" 26 "NotUsed_13" 25 "NotUsed_12" 24 "NotUsed_11" 23 "NotUsed_10" 22 "NotUsed_9" 21 "NotUsed_8" 20 "CustomMode" 19 "OnePedalDrive" 18 "DragMode" 17 "EvLaterChargeMode" 16 "EvNowMode" 15 "TrackMode" 14 "RoughRoadMode" 13 "NotAvailable" 12 "HighSpeedDesertMode_Baja" 11 "SportAdaptiveMode" 10 "RockCrawlMode" 9 "MudRutsMode" 8 "SandMode" 7 "EconomyMode" 6 "GrassGravelSnow" 5 "TowHaulMode" 4 "SportMode" 3 "Normal_4L" 2 "Normal_4A" 1 "Normal_2H" 0 "NormalMode" ;
VAL_ 1186 RearDiffLckMsg_D_Rq 7 "Locker_Disabled" 6 "Locker_Enabled" 5 "Locker_Accel_Pedal" 4 "Speed4" 3 "Speed3" 2 "Spee2" 1 "Speed1" 0 "Normal__No_Message " ;
VAL_ 1186 RearDiffLckLamp_D_Rq 3 "Not_Used" 2 "Flash" 1 "On" 0 "Off" ;
VAL_ 1186 RearDiffLck_Tq_Actl 4095 "Fault" 4094 "Unknown" ;
VAL_ 1186 RearDiffFalt_D_Stat 3 "Diff_Failed_Closed" 2 "Diff_Failed_Open" 1 "Fault_Non_Specific" 0 "No_Fault" ;
VAL_ 1186 LsdSrvcRqd_B_Rq 1 "On" 0 "Off" ;
VAL_ 133 SteWhlOSRelInit2An_Est 65535 "Fault" 65534 "Unknown" ;
VAL_ 133 SteWhlRelCalib_An_Sns 32767 "Fault" 32766 "NoDataExists" ;
VAL_ 133 StePw_B_Rq 1 "Yes" 0 "No" ;
VAL_ 133 SteWhlRelInit2_An_Sns 65535 "Faulty" 65534 "NoDataExists" ;
VAL_ 945 PrkLckCtlMsgTxt_D2_Rq 7 "Message7" 6 "Message6" 5 "Message5" 4 "Message4" 3 "Message3" 2 "Message2" 1 "Message1" 0 "NoMessage" ;
VAL_ 945 KeyPadCodeDgt7_D_Dsply 15 "NotUsed_4" 14 "NotUsed_3" 13 "NotUsed_2" 12 "NotUsed_1" 11 "Button7_8and9_0" 10 "Button0" 9 "Button9_0or9" 8 "Button8" 7 "Button7_8or7" 6 "Button6" 5 "Button5_6or5" 4 "Button4" 3 "Button3_4or3" 2 "Button2" 1 "Button1_2or1" 0 "EndofString" ;
VAL_ 945 KeyPadCodeDgt6_D_Dsply 15 "NotUsed_4" 14 "NotUsed_3" 13 "NotUsed_2" 12 "NotUsed_1" 11 "Button7_8and9_0" 10 "Button0" 9 "Button9_0or9" 8 "Button8" 7 "Button7_8or7" 6 "Button6" 5 "Button5_6or5" 4 "Button4" 3 "Button3_4or3" 2 "Button2" 1 "Button1_2or1" 0 "EndofString" ;
VAL_ 945 KeyPadCodeDgt5_D_Dsply 15 "NotUsed_4" 14 "NotUsed_3" 13 "NotUsed_2" 12 "NotUsed_1" 11 "Button7_8and9_0" 10 "Button0" 9 "Button9_0or9" 8 "Button8" 7 "Button7_8or7" 6 "Button6" 5 "Button5_6or5" 4 "Button4" 3 "Button3_4or3" 2 "Button2" 1 "Button1_2or1" 0 "EndofString" ;
VAL_ 945 KeyPadCodeDgt4_D_Dsply 15 "NotUsed_4" 14 "NotUsed_3" 13 "NotUsed_2" 12 "NotUsed_1" 11 "Button7_8and9_0" 10 "Button0" 9 "Button9_0or9" 8 "Button8" 7 "Button7_8or7" 6 "Button6" 5 "Button5_6or5" 4 "Button4" 3 "Button3_4or3" 2 "Button2" 1 "Button1_2or1" 0 "EndofString" ;
VAL_ 945 KeyPadCodeDgt3_D_Dsply 15 "NotUsed_4" 14 "NotUsed_3" 13 "NotUsed_2" 12 "NotUsed_1" 11 "Button7_8and9_0" 10 "Button0" 9 "Button9_0or9" 8 "Button8" 7 "Button7_8or7" 6 "Button6" 5 "Button5_6or5" 4 "Button4" 3 "Button3_4or3" 2 "Button2" 1 "Button1_2or1" 0 "EndofString" ;
VAL_ 945 KeyPadCodeDgt2_D_Dsply 15 "NotUsed_4" 14 "NotUsed_3" 13 "NotUsed_2" 12 "NotUsed_1" 11 "Button7_8and9_0" 10 "Button0" 9 "Button9_0or9" 8 "Button8" 7 "Button7_8or7" 6 "Button6" 5 "Button5_6or5" 4 "Button4" 3 "Button3_4or3" 2 "Button2" 1 "Button1_2or1" 0 "EndofString" ;
VAL_ 945 KeyPadCodeDgt1_D_Dsply 15 "NotUsed_4" 14 "NotUsed_3" 13 "NotUsed_2" 12 "NotUsed_1" 11 "Button7_8and9_0" 10 "Button0" 9 "Button9_0or9" 8 "Button8" 7 "Button7_8or7" 6 "Button6" 5 "Button5_6or5" 4 "Button4" 3 "Button3_4or3" 2 "Button2" 1 "Button1_2or1" 0 "EndofString" ;
VAL_ 945 KeyOffMde_D_Actl 15 "NotUsed_11" 14 "NotUsed_10" 13 "NotUsed_9" 12 "NotUsed_8" 11 "NotUsed_7" 10 "NotUsed_6" 9 "NotUsed_5" 8 "NotUsed_4" 7 "NotUsed_3" 6 "NotUsed_2" 5 "NotUsed_1" 4 "CriticalBattery" 3 "Hibernate" 2 "Transport" 1 "Factory" 0 "Normal" ;
VAL_ 945 PrkLckCtlLatch_B_Rq 1 "On" 0 "Off" ;
VAL_ 1080 TrlrAidMde_D_Rq_UB 1 "Fresh_data" 0 "Unchanged_data" ;
VAL_ 1080 TrlrAidMde_D_Rq 3 "Mode_3" 2 "Mode_2" 1 "Mode_1" 0 "NoRequest" ;
VAL_ 1080 Rba_D_Rq_UB 1 "Fresh_data" 0 "Unchanged_data" ;
VAL_ 1080 Rba_D_Rq 3 "NotUsed" 2 "On" 1 "Off" 0 "Null" ;
VAL_ 1080 TrailCtlSwtch_B_Stat_UB 1 "Fresh_data" 0 "Unchanged_data" ;
VAL_ 1080 TrailCtlSwtch_B_Stat 1 "Pressed" 0 "Not_Pressed" ;
VAL_ 1080 TrailCtlPt_B_Falt_UB 1 "Fresh_data" 0 "Unchanged_data" ;
VAL_ 1080 TrailCtlPt_B_Falt 1 "Fault" 0 "No_Fault" ;
VAL_ 1080 AutoTowActv_B_Stat_UB 1 "Fresh_data" 0 "Unchanged_data" ;
VAL_ 1080 AutoTowActv_B_Stat 1 "Yes" 0 "No" ;
VAL_ 1080 DrLatchLckRr_B_Stat_UB 1 "Fresh_data" 0 "Unchanged_data" ;
VAL_ 1080 DrLatchLckRl_B_Stat_UB 1 "Fresh_data" 0 "Unchanged_data" ;
VAL_ 1080 DrLatchLckFr_B_Stat_UB 1 "Fresh_data" 0 "Unchanged_data" ;
VAL_ 1080 DrLatchLckFl_B_Stat_UB 1 "Fresh_data" 0 "Unchanged_data" ;
VAL_ 1080 DrLatchRr_B_Falt_UB 1 "Fresh_data" 0 "Unchanged_data" ;
VAL_ 1080 DrLatchRl_B_Falt_UB 1 "Fresh_data" 0 "Unchanged_data" ;
VAL_ 1080 DrLatchFr_B_Falt_UB 1 "Fresh_data" 0 "Unchanged_data" ;
VAL_ 1080 DrLatchFl_B_Falt_UB 1 "Fresh_data" 0 "Unchanged_data" ;
VAL_ 1080 DrLatchCntRr_No_Actl_UB 1 "Fresh_data" 0 "Unchanged_data" ;
VAL_ 1080 DrLatchCntRl_No_Actl_UB 1 "Fresh_data" 0 "Unchanged_data" ;
VAL_ 1080 DrLatchCntFr_No_Actl_UB 1 "Fresh_data" 0 "Unchanged_data" ;
VAL_ 1080 DrLatchCntFl_No_Actl_UB 1 "Fresh_data" 0 "Unchanged_data" ;
VAL_ 1080 DrLatchRr_B_Falt 1 "Yes" 0 "No" ;
VAL_ 1080 DrLatchRl_B_Falt 1 "Yes" 0 "No" ;
VAL_ 1080 DrLatchLckRr_B_Stat 1 "Locked" 0 "Unlock" ;
VAL_ 1080 DrLatchLckRl_B_Stat 1 "Locked" 0 "Unlock" ;
VAL_ 1080 DrLatchLckFr_B_Stat 1 "Locked" 0 "Unlock" ;
VAL_ 1080 DrLatchLckFl_B_Stat 1 "Locked" 0 "Unlock" ;
VAL_ 1080 DrLatchFr_B_Falt 1 "Yes" 0 "No" ;
VAL_ 1080 DrLatchFl_B_Falt 1 "Yes" 0 "No" ;
VAL_ 1080 TurnLghtSwtch_D_Stat2_UB 1 "Fresh_data" 0 "Unchanged_data" ;
VAL_ 1080 TurnLghtSwtch_D_Stat2 3 "NotUsed" 2 "Right" 1 "Left" 0 "Off" ;
VAL_ 1080 CabnAmb_Te_Actl_UB 1 "Fresh_data" 0 "Unchanged_data" ;
VAL_ 1080 CabnAmb_Te_Actl 255 "Fault" ;
VAL_ 1080 HeadLghtHiPrmsn_D_Stat_UB 1 "Fresh_data" 0 "Unchanged_data" ;
VAL_ 1080 HeadLghtHiPrmsn_D_Stat 3 "CancelAndSuppress" 2 "Cancel" 1 "Hold" 0 "AllowChange" ;
VAL_ 1121 OffRdSwtch_D_RqMnu 3 "Faulty" 2 "NoRequest" 1 "On" 0 "Off" ;
VAL_ 1121 SelDrvMdeSwtchOk_D_Stat 3 "Faulty" 2 "Pressed" 1 "NotPressed" 0 "Null" ;
VAL_ 1121 AutoHoldSwtch_D_Stat2 3 "Faulty" 2 "NotUsed" 1 "Pressed" 0 "Not_Pressed" ;
VAL_ 1121 PrkAidSwtch_D_RqDrv3 1 "Pressed" 0 "Not_Pressed" ;
VAL_ 1121 ApaSwtch_D_RqDrv3 3 "NotUsed2" 2 "NotUsed1" 1 "Pressed" 0 "Not_Pressed" ;
VAL_ 1121 StopStrtDrvMde_B_RqBtn2 1 "Pressed" 0 "Not_Pressed" ;
VAL_ 1121 SelDrvMdeSwtch_D_Stat 3 "Faulty" 2 "SwitchState2" 1 "SwitchState1" 0 "NotPressed" ;
VAL_ 1121 SelDrvMdeCnt_D_Stat 4 "FourCounts" 3 "ThreeCounts" 2 "TwoCounts" 1 "OneCount" 0 "ZeroCounts" 7 "SevenOrMoreCounts" 6 "SixCounts" 5 "FiveCounts" ;
VAL_ 673 ICI_Coding_BtnID_D 15 "Idle" 5 "Stuck" 4 "LongEvent" 3 "ShortElapsed" 2 "ShortEvent" 1 "Active" 0 "Inactive" ;
VAL_ 673 ICI_Coding_BtnID_C 15 "Idle" 5 "Stuck" 4 "LongEvent" 3 "ShortElapsed" 2 "ShortEvent" 1 "Active" 0 "Inactive" ;
VAL_ 673 ICI_Coding_BtnID_B 15 "Idle" 5 "Stuck" 4 "LongEvent" 3 "ShortElapsed" 2 "ShortEvent" 1 "Active" 0 "Inactive" ;
VAL_ 673 ICI_Coding_BtnID_A 15 "Idle" 5 "Stuck" 4 "LongEvent" 3 "ShortElapsed" 2 "ShortEvent" 1 "Active" 0 "Inactive" ;
VAL_ 845 SeatMasgPsngr_D_Stat 15 "NotUsed_10" 14 "NotUsed_9" 13 "NotUsed_8" 12 "NotUsed_7" 11 "NotUsed_6" 10 "Pattern10" 9 "Pattern9" 8 "Pattern8" 7 "Pattern7" 6 "Pattern6" 5 "Pattern5" 4 "Pattern4" 3 "Pattern3" 2 "Pattern2" 1 "Pattern1" 0 "Null" ;
VAL_ 845 SeatIntnsPsngr_D_Stat 7 "NotUsed_3" 6 "NotUsed_2" 5 "NotUsed_1" 4 "High" 3 "Medium" 2 "Low" 1 "Off" 0 "Null" ;
VAL_ 845 StmsLmbrPsgr_D_Stat 3 "High" 2 "Low" 1 "Off" 0 "Null" ;
VAL_ 845 StmsCshnPsgr_D_Stat 3 "High" 2 "Low" 1 "Off" 0 "Null" ;
VAL_ 845 SeatSwtchPsgr_B_Stat 1 "On" 0 "Off" ;
VAL_ 845 SeatPPsgr_B_Stat 1 "Updating" 0 "NotUpdating" ;
VAL_ 845 SeatFnPsgr_D_Stat 7 "CushionMassage" 6 "LumbarMassage" 5 "UpperBolster" 4 "LowerBolster" 3 "UpperLumbar" 2 "MiddleLumbar" 1 "LowerLumbar" 0 "Null" ;
VAL_ 845 PsgrMemFeedback_Rsp 8 "Recall_4" 7 "Recall_3" 6 "Recall_2" 5 "Recall_1" 4 "Store_4" 3 "Store_3" 2 "Store_2" 1 "Store_1" 0 "Inactive" ;
VAL_ 850 SeatCshnPsgrRR_Pc_Actl 127 "Null" ;
VAL_ 850 SeatCshnPsgrRL_Pc_Actl 127 "Null" ;
VAL_ 850 SeatCshnPsgrFR_Pc_Actl 127 "Null" ;
VAL_ 850 SeatCshnPsgrFL_Pc_Actl 127 "Null" ;
VAL_ 850 SeatBlLoPsgr_Pc_Actl2 127 "Null" ;
VAL_ 820 TurnLampFrOut_B_Stat 1 "Out" 0 "Null" ;
VAL_ 820 TurnLampFlOut_B_Stat 1 "Out" 0 "Null" ;
VAL_ 820 AhbStatGfhbFdbk_D_Actl 3 "GfhbHighBeamFullyOn" 2 "GfhbHighBeamPartlyOn" 1 "GfhbHighBeamOff" 0 "GfhbUnavailable" ;
VAL_ 820 HeadLghtDrvSide_B_Stat 1 "Left_Hand_Traffic" 0 "Right_Hand_Traffic" ;
VAL_ 820 HeadLghtHiOn_B_StatHcm 1 "On" 0 "Off" ;
VAL_ 820 Adaptive_Hdlmp_Fault 1 "Yes" 0 "No" ;
VAL_ 935 SodInnrRight_D_Stat 3 "Reporting" 2 "Not_Reporting" 1 "System_Standby" 0 "Initialization" ;
VAL_ 935 RbaCtaRight_D_Stat 7 "Faulty" 6 "NotUsed_2" 5 "NotUsed_1" 4 "Invalid" 3 "Disabled" 2 "On" 1 "Trailer_Tow_Off" 0 "Off" ;
VAL_ 935 LcwaRight_D_Stat 7 "Faulty" 6 "NotUsed_3" 5 "NotUsed_2" 4 "NotUsed_1" 3 "Disabled" 2 "TemporaryUnavailable" 1 "SensorBlocked" 0 "Available" ;
VAL_ 935 LcwaDetctRight2_B_Stat 1 "Yes" 0 "No" ;
VAL_ 935 LcwaDetctRight1_B_Stat 1 "Yes" 0 "No" ;
VAL_ 935 CtaInnrRight_D_Stat 3 "Reporting" 2 "Not_Reporting" 1 "System_Standby" 0 "Initialization" ;
VAL_ 935 CtaAlrtRight2_D_Stat 7 "NotUsed3" 6 "NotUsed2" 5 "NotUsed1" 4 "AlertZone4" 3 "AlertZone3" 2 "AlertZone2" 1 "AlertZone1" 0 "Off" ;
VAL_ 935 BttRight_D_Stat 7 "NotUsed" 6 "Disabled" 5 "Off" 4 "OffTemp" 3 "NotConnected" 2 "Pending" 1 "Connected" 0 "NotDetermined" ;
VAL_ 935 BttRight_D_RqDrv 3 "NotUsed" 2 "Request" 1 "NoRequest" 0 "Null" ;
VAL_ 935 CtaBrkRightMsgTxt_B_Rq 1 "Enable" 0 "Disable" ;
VAL_ 935 CtaRightBrkEnbl_B_Rq 1 "Enable" 0 "Disable" ;
VAL_ 935 CtaSnsRight_D_Stat 3 "Invalid" 2 "System_Failure" 1 "Blocked" 0 "Clear" ;
VAL_ 935 CtaAlrtRight_D_Stat 1 "On" 0 "Off" ;
VAL_ 935 CtaRight_D_Stat 7 "NotUsed_3" 6 "NotUsed_2" 5 "NotUsed_1" 4 "Invalid" 3 "Disabled" 2 "On" 1 "Trailer_Tow_Off" 0 "Off" ;
VAL_ 935 SodRight_D_Stat 7 "NotUsed_3" 6 "NotUsed_2" 5 "NotUsed_1" 4 "Invalid" 3 "Disabled" 2 "On" 1 "Trailer_Tow_Off" 0 "Off" ;
VAL_ 935 SodSnsRight_D_Stat 3 "Second_Warning_Audio" 2 "System_Failure" 1 "Blocked" 0 "Clear" ;
VAL_ 935 SodAlrtRight_D_Stat 3 "Bulb_Proveout" 2 "Flash" 1 "On" 0 "Off" ;
VAL_ 935 SodDetctRight_D_Stat 4 "Sensor_Blocked" 3 "Sensor_Fault" 2 "Flash_On" 1 "Alert_On" 0 "AlertOff_FlashOff_SensrClr" ;
VAL_ 935 CtaRightBrkDecel_B_Rq 1 "Enable" 0 "Disable" ;
VAL_ 934 SodInnrLeft_D_Stat 3 "Reporting" 2 "Not_Reporting" 1 "System_Standby" 0 "Initialization" ;
VAL_ 934 RbaCtaLeft_D_Stat 7 "Faulty" 6 "NotUsed_2" 5 "NotUsed_1" 4 "Invalid" 3 "Disabled" 2 "On" 1 "Trailer_Tow_Off" 0 "Off" ;
VAL_ 934 LcwaLeft_D_Stat 7 "Faulty" 6 "NotUsed_3" 5 "NotUsed_2" 4 "NotUsed_1" 3 "Disabled" 2 "TemporaryUnavailable" 1 "SensorBlocked" 0 "Available" ;
VAL_ 934 LcwaDetctLeft2_B_Stat 1 "Yes" 0 "No" ;
VAL_ 934 LcwaDetctLeft1_B_Stat 1 "Yes" 0 "No" ;
VAL_ 934 CtaInnrLeft_D_Stat 3 "Reporting" 2 "Not_Reporting" 1 "System_Standby" 0 "Initialization" ;
VAL_ 934 CtaAlrtLeft2_D_Stat 7 "NotUsed3" 6 "NotUsed2" 5 "NotUsed1" 4 "AlertZone4" 3 "AlertZone3" 2 "AlertZone2" 1 "AlertZone1" 0 "Off" ;
VAL_ 934 BttLeft_D_Stat 7 "NotUsed" 6 "Disabled" 5 "Off" 4 "OffTemp" 3 "NotConnected" 2 "Pending" 1 "Connected" 0 "NotDetermined" ;
VAL_ 934 BttLeft_D_RqDrv 3 "NotUsed" 2 "Request" 1 "NoRequest" 0 "Null" ;
VAL_ 934 CtaBrkLeftMsgTxt_B_Rq 1 "Enable" 0 "Disable" ;
VAL_ 934 CtaLeftBrkDecel_B_Rq 1 "Enable" 0 "Disable" ;
VAL_ 934 CtaLeftBrkEnbl_B_Rq 1 "Enable" 0 "Disable" ;
VAL_ 934 CtaSnsLeft_D_Stat 3 "Invalid" 2 "System_Failure" 1 "Blocked" 0 "Clear" ;
VAL_ 934 SodDetctLeft_D_Stat 4 "Sensor_Blocked" 3 "Sensor_Fault" 2 "Flash_On" 1 "Alert_On" 0 "AlertOff_FlashOff_SensrClr" ;
VAL_ 934 CtaLeft_D_Stat 7 "NotUsed_3" 6 "NotUsed_2" 5 "NotUsed_1" 4 "Invalid" 3 "Disabled" 2 "On" 1 "Trailer_Tow_Off" 0 "Off" ;
VAL_ 934 CtaAlrtLeft_D_Stat 1 "On" 0 "Off" ;
VAL_ 934 SodLeft_D_Stat 7 "NotUsed_3" 6 "NotUsed_2" 5 "NotUsed_1" 4 "Invalid" 3 "Disabled" 2 "On" 1 "Trailer_Tow_Off" 0 "Off" ;
VAL_ 934 SodSnsLeft_D_Stat 3 "Second_Warning_Audio" 2 "System_Failure" 1 "Blocked" 0 "Clear" ;
VAL_ 934 SodAlrtLeft_D_Stat 3 "Bulb_Proveout" 2 "Flash" 1 "On" 0 "Off" ;
VAL_ 1073 CamraFrntBttn_D_Stat 1 "Pressed" 0 "Not_Pressed" ;
VAL_ 1073 CamraFrntBttn_D_Stat_UB 1 "Fresh_data" 0 "Unchanged_data" ;
VAL_ 1073 BrkDrvMde_D_Rq_UB 1 "Fresh_data" 0 "Unchanged_data" ;
VAL_ 1073 BrkDrvMde_D_Rq 7 "Faulty" 6 "RockCrawl" 5 "Baja" 4 "DragOrMudAndSand" 3 "Track" 2 "Snow_Wet" 1 "Sport" 0 "Normal" ;
VAL_ 1073 SteEffort_D_Rq 7 "NotUsed_3" 6 "NotUsed_2" 5 "NotUsed_1" 4 "SpecialMode_2" 3 "SpecialMode_1" 2 "Comfort" 1 "Sport" 0 "Normal" ;
VAL_ 1073 SteEffort_D_Rq_UB 1 "Fresh_data" 0 "Unchanged_data" ;
VAL_ 1073 AutoHoldSwtch_D_Stat_UB 1 "Fresh_data" 0 "Unchanged_data" ;
VAL_ 1073 AutoHoldSwtch_D_Stat 3 "Faulty" 2 "NotUsed" 1 "Pressed" 0 "Not_Pressed" ;
VAL_ 1073 HMI_HMIMode_St_UB 1 "Fresh_data" 0 "Unchanged_data" ;
VAL_ 1073 HMI_HMIMode_St 7 "NotUsed2" 6 "NotUsed1" 5 "Load_Shed_Active" 0 "Invalid" 1 "OffMode" 2 "On" 3 "Phone" 4 "Climate" ;
VAL_ 1073 Veh_Lock_Requestor_UB 1 "Fresh_data" 0 "Unchanged_data" ;
VAL_ 1073 Veh_Lock_EvNum_UB 1 "Fresh_data" 0 "Unchanged_data" ;
VAL_ 1073 Veh_Lock_Sub_Id_UB 1 "Fresh_data" 0 "Unchanged_data" ;
VAL_ 1073 Tire_Press_System_Stat_UB 1 "Fresh_data" 0 "Unchanged_data" ;
VAL_ 1073 Veh_Lock_Status_UB 1 "Fresh_data" 0 "Unchanged_data" ;
VAL_ 1073 Veh_Lock_Sub_Id 15 "Unused7" 14 "Unused6" 13 "Unused5" 12 "Unused4" 11 "Unused3" 10 "Unused2" 9 "Unused1" 8 "Customer_8" 7 "Customer_7" 6 "Customer_6" 5 "Customer_5" 4 "Customer_4" 3 "Customer_3" 2 "Customer_2" 1 "Customer_1" 0 "Null" ;
VAL_ 1073 Veh_Lock_Status 3 "UNLOCK_DRV" 2 "UNLOCK_ALL" 1 "LOCK_ALL" 0 "LOCK_DBL" ;
VAL_ 1073 Veh_Lock_Requestor 31 "Walk_Away_Locking" 30 "Remote_Park_Assist" 29 "DoorsOffToOn_Smart_Unlock" 28 "Rgtm_Shutlock_Switch" 27 "Boundary_Alert" 26 "Transit_Vehicle_Relock" 25 "Transit_Cargo_Relock" 24 "Transit_Ajar_Lock" 23 "Diagnostics" 22 "Console_Lock" 21 "Child_Lock" 20 "Double_Lock" 19 "Passive_Pasenger" 18 "Passive_Driver" 17 "Slam_Lock_Protect" 16 "SYNC" 15 "Passport" 14 "Passive_Smart_Unlock" 13 "Autorelock" 12 "RemoteStart" 0 "Null" 1 "Autolock" 11 "Smart_Unlock" 10 "Sliding_Door" 9 "Passive" 8 "Remote" 7 "Programming" 6 "Powerslide" 5 "Keypad" 4 "Key_Cylinder" 3 "Interior" 2 "Auto_Unlock" ;
VAL_ 1073 Tire_Press_System_Stat 13 "Training_Complete" 12 "Train_InsideLeftRear_tire" 11 "Train_OutsideLeftRear_tire" 10 "Train_LeftRear_tire" 9 "Train_InsideRtRear_tire" 8 "Train_OutsideRtRear_tire" 7 "Train_RightRear_tire" 14 "Tires_not_trained" 6 "Train_RightFront_tire" 5 "Train_LeftFront_tire" 4 "Systm_Activ_Composite_Stat" 3 "Low_Composite_Stat" 2 "Sensr_Fault_Composite_Stat" 1 "Systm_Fault_Composite_Stat" 0 "Unknown_Composite_Stat" ;
VAL_ 1073 DISPLAY_SPEED_OFFSET_UB 1 "Fresh_data" 0 "Unchanged_data" ;
VAL_ 1073 DISPLAY_SPEED_SCALING_UB 1 "Fresh_data" 0 "Unchanged_data" ;
VAL_ 1073 Foh_D_Stat 7 "Unused3" 6 "Unused2" 5 "Unused1" 4 "Stopping" 3 "Running" 2 "Starting" 1 "Prestart" 0 "Off" ;
VAL_ 1073 Foh_D_Stat_UB 1 "Fresh_data" 0 "Unchanged_data" ;
VAL_ 1073 SteWhlHeat_D_Rq_UB 1 "Fresh_data" 0 "Unchanged_data" ;
VAL_ 1073 SteWhlHeat_D_Rq 15 "NotUsed6" 14 "NotUsed5" 13 "NotUsed4" 12 "NotUsed3" 11 "NotUsed2" 10 "NotUsed1" 9 "Reserved_3" 8 "Reserved_2" 7 "Reserved_1" 6 "Level_3_Heating" 5 "Level_3_Heating_LS" 4 "Level_2_Heating" 3 "Level_2_Heating_LS" 2 "Level_1_Heating" 1 "Level_1_Heating_LS" 0 "Off" ;
VAL_ 1091 CamraRearOn_D2_Stat2 7 "Faulty" 6 "NotUsed_3" 5 "NotUsed_2" 4 "NotUsed_1" 3 "Decommission" 2 "Activate" 1 "Deactivate" 0 "Null" ;
VAL_ 1091 PoliceAux4Lamp_B_Rq2 1 "On" 0 "Off" ;
VAL_ 1091 PoliceAux3Lamp_B_Rq2 1 "On" 0 "Off" ;
VAL_ 1091 PoliceAux2Lamp_B_Rq2 1 "On" 0 "Off" ;
VAL_ 1091 PoliceAux1Lamp_B_Rq2 1 "On" 0 "Off" ;
VAL_ 1091 WakeAlarm2_B_Typ 1 "CanAndEcuDriveCircuit" 0 "CanOnly" ;
VAL_ 1091 TrlrAlarmSpprt_D_Stat 3 "SupportedByBrakesAndLights" 2 "SupportedByLights" 1 "SupportedByBrakes" 0 "NotSupported" ;
VAL_ 1091 TowBarMsgTxt_D_Rq 7 "NotUsed3" 6 "NotUsed2" 5 "NotUsed1" 4 "TowBar_Ext_No_Trlr" 3 "Error_Dealer_Fix" 2 "Start_Engine_Swivel" 1 "Check_Tow_Bar" 0 "Null" ;
VAL_ 1091 ParkLampTrlrOut_B_Stat 1 "Out" 0 "Null" ;
VAL_ 1091 StopLampTrlrOut_B_Stat 1 "Out" 0 "Null" ;
VAL_ 1091 TrlrBattChrg_D_Stat 3 "Reverse" 2 "Normal" 1 "Low" 0 "Null" ;
VAL_ 1091 TrlrLampCtl_D_Stat 3 "NotUsed" 2 "TrlrLampCnnctDrvFailure" 1 "TrlrLampNotCnnctDrvFailure" 0 "Null" ;
VAL_ 1091 TurnLampTrlrRr_B_Stat 1 "Out" 0 "Null" ;
VAL_ 1091 TurnLampTrlrRl_B_Stat 1 "Out" 0 "Null" ;
VAL_ 1091 TrlrLampCnnct_B_Actl 1 "Yes" 0 "No" ;
VAL_ 1068 EngStrtInhbt_B_RqBatt 1 "Start_Inhibit" 0 "Dont_Care" ;
VAL_ 1068 BattULoChrg_D_Rq 3 "Low_Battery_Temperature" 2 "Charging_Requested" 1 "Chrg_Requested_HighCurrent" 0 "No_Request" ;
VAL_ 1068 PwSysULoFalt_D_Stat 15 "Not_Used_6" 14 "LowBatterySOC" 13 "PSS_Shed2_Contin" 12 "Not_Used_4" 11 "Not_Used_3" 10 "Not_Used_2" 9 "BattMonitoringSensorFault" 8 "LowBattVoltDuringPwSrcOn" 7 "LowBatt2_PowerSaveMode" 6 "LowBatt1_Warning" 5 "Overvoltage" 4 "Fault_NoOutput" 3 "Fault_ReducedOutput" 2 "Fault_Nonspecific" 1 "Cluster_Proveout" 0 "No_Fault" ;
VAL_ 1068 Shed_T_Eng_Off_B 1 "Active" 0 "Inactive" ;
VAL_ 1068 Shed_Feature_Group_ID 16 "PtcHeater" 30 "NotUsed_7" 29 "NotUsed_6" 28 "NotUsed_5" 27 "NotUsed_4" 26 "NotUsed_3" 25 "NotUsed_2" 24 "NotUsed_1" 23 "Dcac" 22 "UpFitter_6" 21 "UpFitter_5" 20 "UpFitter_4" 19 "UpFitter_3" 18 "UpFitter_2" 17 "UpFitter_1" 14 "HtdMirr" 13 "HvacRearBlwr_Third" 12 "HvacRearBlwr_Second" 11 "HvacRearBlwr_First" 31 "All LSHED1 Features" 10 "Htd_Windscrn" 9 "SpltHtdBcklight_HtdMirr" 8 "HtdBcklight_HtdMirr" 7 "HtdCoolSeat_FrtDriver" 6 "HtdCoolSeat_FrtPass" 5 "HtdCoolSeat_RearPass" 4 "HtdCoolSeat_RearDriver" 3 "SmartTrlrTowBattCharge" 2 "Htd_StrWhl" 1 "Htd_Washer_Fluid" 0 "No_LSHED1_Features" 15 "Engine_Coolant_Fan" ;
VAL_ 1068 Shed_Drain_Eng_Off_B 1 "Active" 0 "Inactive" ;
VAL_ 1068 Shed_Level_Req 7 "SHED3" 6 "Loads_On" 5 "SHED_ENG_OFF" 4 "SOON_ENG_OFF" 3 "SHED2_CONTIN" 2 "SHED2_TRANS" 1 "SHED1" 0 "NO_SHED" ;
VAL_ 1068 ChargeMode 7 "Undefined_2" 6 "Undefined_1" 5 "Battery_Identify" 4 "Battery_Refresh" 3 "SlowRegenAllowNoDischarge" 2 "Fast_Regen_Allowed" 1 "Slow_Regen_Allowed" 0 "Conventional_Charging" ;
VAL_ 1068 IdleSpeedIncrease_El 1 "Yes" 0 "No" ;
VAL_ 1068 Batt_Lo_SoC_B 1 "Active" 0 "Inactive" ;
VAL_ 1068 PeriodicElLoad_B_Stat 1 "Active" 0 "Inactive" ;
VAL_ 1068 Batt_Crit_SoC_B 1 "Active" 0 "Inactive" ;
VAL_ 1068 ULoRgenTestMde_B_Rq 1 "Request" 0 "NoRequest" ;
VAL_ 611 AwdTerrMdeChng_D_Rdy 7 "Fault" 6 "Undefined_2" 5 "Undefined_1" 4 "ModeUnavailDrInputRqd" 3 "SpOpModes_NotSupported" 2 "ModeUnavailDynamicCond" 1 "Module_In_Initialization" 0 "Mode_Change_Available" ;
VAL_ 611 AwdTerrMde_D_Actl 7 "Fail_Safe_Default" 6 "Dynamic_Mode" 5 "Rock_Crawl_Mode" 4 "Mud_Ruts_Mode" 3 "Sand_Mode" 2 "Undefined" 1 "Low_Mu_Mode" 0 "Special_Operating_Mode_Off" ;
VAL_ 611 AwdSys_D_Stat 3 "Faulty" 2 "NotUsed" 1 "_4x4_L_H_Active" 0 "_4x4_L_H_Inactive" ;
VAL_ 611 SelDrvMdeAwd_D_Stat 0 "NotAvailable" 1 "Available" 2 "TemporarilyNotAvailable" 3 "Faulty" ;
VAL_ 611 AwdStat_D_RqDsply 31 "Rear_Diff_Lock_Not_Avail" 30 "_4wd_Lock_Required" 29 "Cfg_Perf_Redc_See_Manual" 28 "To_Engage_4x4_Release_Aped" 27 "To_Engage_4x4_Slow_To_3MPH" 26 "Shift_To_Neutral" 25 "Lkr_Mode_Unavail_TMS" 24 " _4x4_Mode_Unavail_TMS" 23 "Out_of_4Low_Crawl" 22 "AWD_PTU_Oil_Changed" 21 "Change_AWD_PTU_Oil" 20 "Neutral_Tow_Disabled" 19 "Neutral_Tow_Enabled" 18 "AWD_OFF" 17 "_4x4_Off_Road_Speed" 16 "_4x4_Extreme_Off_Road_Mode" 15 "_4x4_Exiting_Off_Road" 14 "_4x4_Off_Road_Mode" 10 "_4x4_Locked_Temporarily" 9 "Shift_In_Progress" 13 "Blocked_Shift_Assist" 12 "_4x4_Auto_Restored" 11 "_4x4_Disabled_Temporarily" 7 "Out_of_4Low__Neutral" 6 "Out_of_4Low__Brake" 5 "Out_of_4Low__Speed" 4 "Into_4Low__Clutch" 3 "Into_4Low__Neutral" 2 "Into_4Low__Brake" 1 "Into_4Low__Speed" 0 "Normal__No_Message" 8 "Out_of_4Low__Clutch" ;
VAL_ 611 AwdLck_D_Stat 9 "Undefined" 8 "Under_External_Torque_Ctrl" 7 "Torque_Limited_by_Cmd" 6 "Fully_Locked_by_Cmd" 5 "Disabled" 4 "Warning" 3 "Fault" 2 "Inactive" 1 "Completely_Opened_by_Cmd" 0 "OK" ;
VAL_ 611 AwdSrvcRqd_B_Rq 1 "On" 0 "Off" ;
VAL_ 611 AwdDrvMde_D_Stat 7 "Faulty" 6 "NotAvailable" 5 "RockCrawl" 4 "Baja" 3 "MudAndSand" 2 "Weather" 1 "Sport" 0 "Normal" ;
VAL_ 611 NtrlTowAvail_B_Stat 1 "Available" 0 "NotAvailable" ;
VAL_ 611 AwdLck_Tq_Rq 4095 "Fault" 4094 "Unknown" ;
VAL_ 611 AwdOffRoadMode_D_Stats 3 "Invalid" 2 "Extreme_Off_Road" 1 "Off_Road" 0 "Normal_Mode" ;
VAL_ 611 AwdLoLamp_D_RqDsply 3 "Not_Used" 2 "Flash" 1 "On" 0 "Off" ;
VAL_ 611 AwdHiLamp_D_RqDsply 3 "Not_Used" 2 "Flash" 1 "On" 0 "Off" ;
VAL_ 611 AwdAutoLamp_D_RqDsply 3 "Not_Used" 2 "Flash" 1 "On" 0 "Off" ;
VAL_ 611 Awd2wdLamp_D_RqDsply 3 "Not_Used" 2 "Flash" 1 "On" 0 "Off" ;
VAL_ 611 AwdRnge_D_Actl 7 "Unknown" 6 "High_Range_2wd" 5 "High_Range_Auto" 4 "High_Range_Locked" 3 "Neutral" 2 "Low_Range_2wd" 1 "Low_Range_Auto" 0 "Low_Range_Locked" ;
VAL_ 395 SelDrvMdeCnfm_D_Stat 3 "NotUsed" 2 "Accepted" 1 "NotAccepted" 0 "Null" ;
VAL_ 395 HudMde_D_Rq 7 "NotUsed3" 6 "NotUsed2" 5 "NotUsed1" 4 "Manual" 3 "Drag" 2 "RoadCourse" 1 "Tach" 0 "Off" ;
VAL_ 395 HudLedMde_D_Rq 3 "Not_Used" 2 "Flash" 1 "On" 0 "Off" ;
VAL_ 395 HudLed9On_B_Rq 1 "On" 0 "Off" ;
VAL_ 395 HudLed8On_B_Rq 1 "On" 0 "Off" ;
VAL_ 395 HudLed7On_B_Rq 1 "On" 0 "Off" ;
VAL_ 395 HudLed6On_B_Rq 1 "On" 0 "Off" ;
VAL_ 395 HudLed5On_B_Rq 1 "On" 0 "Off" ;
VAL_ 395 HudLed4On_B_Rq 1 "On" 0 "Off" ;
VAL_ 395 HudLed3On_B_Rq 1 "On" 0 "Off" ;
VAL_ 395 HudLed2On_B_Rq 1 "On" 0 "Off" ;
VAL_ 395 HudLed1On_B_Rq 1 "On" 0 "Off" ;
VAL_ 395 HudLed18On_B_Rq 1 "On" 0 "Off" ;
VAL_ 395 HudLed17On_B_Rq 1 "On" 0 "Off" ;
VAL_ 395 HudLed16On_B_Rq 1 "On" 0 "Off" ;
VAL_ 395 HudLed15On_B_Rq 1 "On" 0 "Off" ;
VAL_ 395 HudLed14On_B_Rq 1 "On" 0 "Off" ;
VAL_ 395 HudLed13On_B_Rq 1 "On" 0 "Off" ;
VAL_ 395 HudLed12On_B_Rq 1 "On" 0 "Off" ;
VAL_ 395 HudLed11On_B_Rq 1 "On" 0 "Off" ;
VAL_ 395 HudLed10On_B_Rq 1 "On" 0 "Off" ;
VAL_ 578 PtLatchActv_B_RqBcm 1 "On" 0 "Off" ;
VAL_ 578 PrkLckCtlUnlck_D_Stat 3 "Trans_And_Steer_Unlckd" 2 "Steering_Unlckd" 1 "Transmission_Unlckd" 0 "Null" ;
VAL_ 578 PrkLckCtlTow_B_Enbl 1 "Enable" 0 "Disable" ;
VAL_ 578 immoSecureIdleMode 3 "NotUsed2" 2 "NotUsed1" 1 "Active" 0 "Inactive" ;
VAL_ 578 FuelPumpPwr_D_Stat 7 "NotUsed3" 6 "NotUsed2" 5 "NotUsed1" 4 "Power_Off_Default" 3 "Power_Off_Command" 2 "Power_Off_Service" 1 "Power_Off_Impact" 0 "Power_On" ;
VAL_ 578 BattULo_U_Actl 255 "Fault" ;
VAL_ 578 PrkLckCtl_B_Enbl 1 "Enable" 0 "Disable" ;
VAL_ 578 PrkLckCtlMsgTxt_D_Rq 3 "BTSI_DI_3" 2 "BTSI_DI_2" 1 "BTSI_DI_1" 0 "Null_BTSI_DI" ;
VAL_ 578 BrkTrnShifLck_B_Stat 1 "Shift" 0 "NoShift" ;
VAL_ 578 DriverCrankingReq 1 "Crank_Request" 0 "No_Crank_Request" ;
VAL_ 578 EngOff_T_Actl 65535 "Invalid" ;
VAL_ 578 ReFuelSwtchStat_D_Actl 3 "NotUsed2" 2 "NotUsed1" 1 "On" 0 "Off" ;
VAL_ 578 DcacElPw_D_Rq 3 "NotUsed" 2 "AC_HighPower_Requested" 1 "AC_LowPower_Requested" 0 "AC_Power_NotRequested" ;
VAL_ 578 BattULo_I_Actl 16383 "Fault" ;
VAL_ 560 SelDrvMdeSwtch_D_Stat3 3 "Faulty" 2 "SwitchState2" 1 "SwitchState1" 0 "NotPressed" ;
VAL_ 560 TrnGbox_Rt_Actl 65535 "Fault" 65534 "Unknown" ;
VAL_ 560 TrnSrvcRqd_B_Rq 1 "On" 0 "Off" ;
VAL_ 560 TrnCnvtClu_D_Actl 3 "Transition_or_Micro_Slip" 2 "Lock_Up_Fixed" 1 "Lock_Up_Slip" 0 "No_Lock_Up" ;
VAL_ 560 TrnShifActv_B_Actl 1 "Active" 0 "Inactive" ;
VAL_ 560 RtmTerrMdeChng_D_Rdy 7 "Fault" 6 "Undefined_2" 5 "Undefined_1" 4 "ModeUnavailDrInputRqd" 3 "SpOpModes_NotSupported" 2 "ModeUnavailDynamicCond" 1 "Module_In_Initialization" 0 "Mode_Change_Available" ;
VAL_ 560 RtmTerrMde_D_Actl 7 "Fail_Safe_Default" 6 "Dynamic_Mode" 5 "Rock_Crawl_Mode" 4 "Mud_Ruts_Mode" 3 "Sand_Mode" 2 "Undefined" 1 "Low_Mu_Mode" 0 "Special_Operating_Mode_Off" ;
VAL_ 560 GearLvrPos_D_Actl 15 "Fault" 14 "Unknown_Position" 13 "Undefined_Treat_as__Fault" 12 "Undefined_Treat_as_Fault" 11 "sixth" 10 "fifth" 9 "fourth" 8 "third" 7 "second" 6 "first" 5 "Low" 4 "Sport_DriveSport" 3 "Drive" 2 "Neutral" 1 "Reverse" 0 "Park" ;
VAL_ 560 GboxOil_Te_Actl 255 "Faulty" 254 "NoDataExists" ;
VAL_ 359 PrplWhlRgenMn_Tq_Actl 8191 "Faulty" ;
VAL_ 359 ElPw_D_StatStrtStop 15 "NotUsed6" 14 "NotUsed5" 13 "NotUsed4" 12 "NotUsed3" 11 "NotUsed2" 10 "NotUsed1" 9 "Supported_Level_4" 8 "Supported_Level_3" 7 "Supported_Level_2" 6 "Supported_Level_1" 5 "Limited_Support" 4 "Fault_Limited" 3 "LV_Event_in_Progress" 2 "Not_Supported_Imminent" 1 "Supported_All" 0 "Not_Supported" ;
VAL_ 359 PrplWhlTot2_Tq_Actl 65535 "Fault" 65534 "NoDataExists" ;
VAL_ 359 LscmbbDeny_B_ActlPrpl 1 "Denied" 0 "Allowed" ;
VAL_ 359 LscmbbEngTqMn_B_Actl 1 "Engine_Braking_Activated" 0 "Engine_Braking_Off" ;
VAL_ 359 PwPckTq_D_Stat 3 "PwPckOn_TqAvailable" 2 "StartInPrgrss_TqNotAvail" 1 "PwPckOn_TqNotAvailable" 0 "PwPckOff_TqNotAvailable" ;
VAL_ 359 Eng_D_Stat 3 "NotUsed" 2 "EngAutoStopped" 1 "EngOn" 0 "EngOff" ;
VAL_ 359 ElPw_D_Stat 7 "NotUsed_3" 6 "NotUsed_2" 5 "NotUsed_1" 4 "Fault_Limited" 3 "LV_Event_In_Progress" 2 "Not_Supported_Imminent" 1 "Supported" 0 "Not_Supported" ;
VAL_ 359 TrnAinTq_D_Qf 3 "OK" 2 "Not_Within_Specifications" 1 "No_Data_Exists" 0 "Faulty" ;
VAL_ 359 PlgActvArb_B_Actl 1 "On" 0 "Off" ;
VAL_ 357 BPedDrvAppl_D_QF 3 "OK" 2 "Not_Within_Specifications" 1 "No_Data_Exists" 0 "Faulty" ;
VAL_ 357 CmbbDeny_B_ActlPrpl 1 "Yes" 0 "No" ;
VAL_ 357 PrplTqMnSat_B_Actl 1 "Yes" 0 "No" ;
VAL_ 357 VehStrtStop_D_Rq 3 "NotUsed" 2 "Vehicle_Start_Request" 1 "Vehicle_Stop_Request" 0 "NoRequest" ;
VAL_ 357 BpedDrvAppl_D_Actl 3 "_Not_Allowed" 2 "Driver_Braking" 1 "Driver_Not_Braking" 0 "Not_Allowed" ;
VAL_ 357 CmbbEngTqMn_B_Actl 1 "Yes" 0 "No" ;
VAL_ 357 Veh_V_DsplyCcSet 255 "Fault" 254 "Unknown" ;
VAL_ 357 AccEngStat_D_Actl 7 "Undefined_2" 6 "Undefined_1" 5 "ACCSoonCancel_due_Low_Spd" 4 "Shift_Down_Recommendation" 3 "Shift_Up_Recommendation" 2 "ACCNotAllowedToBeActivated" 1 "ACCStandby_due_Auto_Cancel" 0 "Normal_Operation" ;
VAL_ 357 CcMde_D_Actl 7 "TapDownWaiting" 6 "TapUpWaiting" 5 "Resuming_Low" 4 "Resuming_High" 3 "Decelerating" 2 "Accelerating" 1 "Keeping_Speed" 0 "Not_Active" ;
VAL_ 357 CcStat_D_Actl 7 "Undefined_2" 6 "Undefined_1" 5 "Active" 4 "Active_Que_Assist" 3 "Standby" 2 "Standby_Denied" 1 "Denied" 0 "Off" ;
VAL_ 357 CcOvrrdActv_B_Actl 1 "Cruise_Overridden" 0 "Cruise_Req_Not_Overridden" ;
VAL_ 357 AccStopMde_D_Rq 3 "Stop_Mode_Active" 2 "EPBApplyOrBrakeReleaseWarn" 1 "Limit_Rolling_Speed" 0 "Stop_Mode_Not_Active" ;
VAL_ 390 AccAutoResum_D_Rq 3 "NotUsed" 2 "Active" 1 "Pending" 0 "Off" ;
VAL_ 390 AccBrkPulse_B_Rq 1 "True" 0 "False" ;
VAL_ 390 AccBrkPrkEl_B_Rq 1 "Yes" 0 "No" ;
VAL_ 390 Cmbb_B_Enbl 1 "Yes" 0 "No" ;
VAL_ 390 CmbbOvrrd_B_RqDrv 1 "Yes" 0 "No" ;
VAL_ 390 CmbbDeny_B_Actl 1 "Yes" 0 "No" ;
VAL_ 390 CmbbEngTqMn_B_Rq 1 "Yes" 0 "No" ;
VAL_ 390 AccDeny_B_Rq 1 "Yes" 0 "No" ;
VAL_ 390 AccResumEnbl_B_Rq 1 "Yes" 0 "No" ;
VAL_ 390 AccCancl_B_Rq 1 "Yes" 0 "No" ;
VAL_ 390 AccBrkPrchg_B_Rq 1 "Yes" 0 "No" ;
VAL_ 390 AccBrkDecel_B_Rq 1 "Active" 0 "Inactive" ;
VAL_ 390 AccStopStat_B_Rq 1 "Yes" 0 "No" ;
VAL_ 1071 CluPdlPosPcMeas_D_Qf 3 "OK" 2 "Not_Within_Specifications" 1 "No_Data_Exists" 0 "Faulty" ;
VAL_ 1071 EngMnfld3_P_Actl 255 "Faulty" 254 "NoDataExists" ;
VAL_ 1072 HdcOn_B_Rq_UB 1 "Fresh_data" 0 "Unchanged_data" ;
VAL_ 1072 TrlrAidCancl_B_Rq_UB 1 "Fresh_data" 0 "Unchanged_data" ;
VAL_ 1072 TrlrAidCancl_B_Rq 1 "Cancel" 0 "Null" ;
VAL_ 1072 HdcOn_B_Rq 1 "On" 0 "Off" ;
VAL_ 1072 HsaMde_D_Rq 3 "Undefined" 2 "Manual" 1 "Automatic" 0 "Off" ;
VAL_ 1072 HsaMde_D_Rq_UB 1 "Fresh_data" 0 "Unchanged_data" ;
VAL_ 1072 LscmbbStat_B_Actl 1 "On" 0 "Off" ;
VAL_ 1072 LscmbbStat_B_Actl_UB 1 "Fresh_data" 0 "Unchanged_data" ;
VAL_ 1072 Outside_Air_Temp_Stat_UB 1 "Fresh_data" 0 "Unchanged_data" ;
VAL_ 1072 Outside_Air_Temp_Stat 255 "Invalid" 254 "Unknown" ;
VAL_ 1072 BulbChkActv_B_Stat_UB 1 "Fresh_data" 0 "Unchanged_data" ;
VAL_ 1072 BulbChkActv_B_Stat 1 "Active" 0 "Inactive" ;
VAL_ 1072 Fda_B_Stat_UB 1 "Fresh_data" 0 "Unchanged_data" ;
VAL_ 1072 AccEnbl_B_RqDrv_UB 1 "Fresh_data" 0 "Unchanged_data" ;
VAL_ 1072 AccDeny_B_RqIpc_UB 1 "Fresh_data" 0 "Unchanged_data" ;
VAL_ 1072 OdometerMasterValue_UB 1 "Fresh_data" 0 "Unchanged_data" ;
VAL_ 1072 OdometerMasterValue 16777215 "Invalid" ;
VAL_ 1072 Fda_B_Stat 1 "On" 0 "Off" ;
VAL_ 1072 AccDeny_B_RqIpc 1 "Yes" 0 "No" ;
VAL_ 1072 AccEnbl_B_RqDrv 1 "Adaptive_Cruise" 0 "Normal_Cruise" ;
VAL_ 1072 DrvSlipCtlMde_D_Rq_UB 1 "Fresh_data" 0 "Unchanged_data" ;
VAL_ 1072 DrvSlipCtlMde_D_Rq 3 "App_Specific_Off_Mode_3" 2 "App_Specific_Off_Mode_2" 1 "App_Specific_Off_Mode_1" 0 "Default_Mode" ;
VAL_ 1072 DrvSlipCtlMde_B_Rq_UB 1 "Fresh_data" 0 "Unchanged_data" ;
VAL_ 1072 DrvSlipCtlMde_B_Rq 1 "Pressed" 0 "Not_Pressed" ;
VAL_ 1072 ePRNDL_MODE_UB 1 "Fresh_data" 0 "Unchanged_data" ;
VAL_ 1072 ePRNDL_MODE 1 "On" 0 "Off" ;
VAL_ 1072 TrlrBrkMde_D_Rq 1 "ElectricOverHydraulic" 0 "Electric" ;
VAL_ 1072 TRLR_SWAY_CONFIG_CMD 1 "On" 0 "Off" ;
VAL_ 1072 TRAILER_BRAKE_CONFIG 1 "Yes" 0 "No" ;
VAL_ 1072 TrlrBrkMde_D_Rq_UB 1 "Fresh_data" 0 "Unchanged_data" ;
VAL_ 1072 TRLR_SWAY_CONFIG_CMD_UB 1 "Fresh_data" 0 "Unchanged_data" ;
VAL_ 1072 TRAILER_BRAKE_CONFIG_UB 1 "Fresh_data" 0 "Unchanged_data" ;
VAL_ 1058 TqmTerrMdeChng_D_Rdy_UB 1 "Fresh_data" 0 "Unchanged_data" ;
VAL_ 1058 TqmTerrMde_D_Actl_UB 1 "Fresh_data" 0 "Unchanged_data" ;
VAL_ 1058 TqmTerrMdeChng_D_Rdy 7 "Fault" 6 "Undefined_2" 5 "Undefined_1" 4 "ModeUnavailDrInputRqd" 3 "SpOpModes_NotSupported" 2 "ModeUnavailDynamicCond" 1 "Module_In_Initialization" 0 "Mode_Change_Available" ;
VAL_ 1058 TqmTerrMde_D_Actl 7 "Fail_Safe_Default" 6 "Dynamic_Mode" 5 "Rock_Crawl_Mode" 4 "Mud_Ruts_Mode" 3 "Sand_Mode" 2 "Undefined" 1 "Low_Mu_Mode" 0 "Special_Operating_Mode_Off" ;
VAL_ 1058 BattTracWarnLamp_B_Rq_UB 1 "Fresh_data" 0 "Unchanged_data" ;
VAL_ 1058 BattTracWarnLamp_B_Rq 1 "On" 0 "Off" ;
VAL_ 1058 BattTracSrvcRqd_B_Rq_UB 1 "Fresh_data" 0 "Unchanged_data" ;
VAL_ 1058 BattTracSrvcRqd_B_Rq 1 "On" 0 "Off" ;
VAL_ 1058 SeatBlLoPsgr_Pc_Actl_UB 1 "Fresh_data" 0 "Unchanged_data" ;
VAL_ 1058 SeatBlLoPsgr_Pc_Actl 127 "Null" ;
VAL_ 1058 WndwFrontHeat_B_Stat_UB 1 "Fresh_data" 0 "Unchanged_data" ;
VAL_ 1058 WndwFrontHeat_B_Stat 1 "On" 0 "Off" ;
VAL_ 1058 HILL_DESC_SW_UB 1 "Fresh_data" 0 "Unchanged_data" ;
VAL_ 1058 HILL_DESC_SW 1 "On" 0 "Off" ;
VAL_ 1058 EngClntTe_D_Qf 3 "OK" 2 "Not_Within_Specifications" 1 "No_Data_Exists" 0 "Faulty" ;
VAL_ 1058 EngClnt_Te_Actl_UB 1 "Fresh_data" 0 "Unchanged_data" ;
VAL_ 1058 TrnTotTq_Rt_Est_UB 1 "Fresh_data" 0 "Unchanged_data" ;
VAL_ 1058 TrnTotLss_Tq_Est_UB 1 "Fresh_data" 0 "Unchanged_data" ;
VAL_ 1058 TrnTotTq_Rt_Est 65535 "Fault" 65534 "Unknown" ;
VAL_ 1058 TrnTotLss_Tq_Est 255 "Fault" 254 "Unknown" ;
VAL_ 1058 DrvSlipCtlMde_B_Rq2_UB 1 "Fresh_data" 0 "Unchanged_data" ;
VAL_ 1058 DrvSlipCtlMde_B_Rq2 1 "Pressed" 0 "Not_Pressed" ;
VAL_ 1082 EsaOn_B_Rq_UB 1 "Fresh_data" 0 "Unchanged_data" ;
VAL_ 1082 EsaOn_B_Rq 1 "On" 0 "Off" ;
VAL_ 1082 RearDiffLck_D_RqArb_UB 1 "Fresh_data" 0 "Unchanged_data" ;
VAL_ 1082 RearDiffLck_D_RqArb 3 "Faulty" 2 "NotUsed" 1 "On" 0 "Off" ;
VAL_ 1082 AwdMde_D_RqArb_UB 1 "Fresh_data" 0 "Unchanged_data" ;
VAL_ 1082 AwdMde_D_RqArb 7 "Faulty" 6 "NotUsed2" 5 "NoRequest" 4 "Neutral" 3 "FourByFourLow" 2 "FourByFourHigh" 1 "FourByFourAuto" 0 "FourByTwo" ;
VAL_ 1082 SelDrvMdeTxtReset_B_Rq_UB 1 "Fresh_data" 0 "Unchanged_data" ;
VAL_ 1082 SelDrvMdeTxtReset_B_Rq 1 "Yes" 0 "No" ;
VAL_ 1082 SelDrvMdeDsply_B_Avail_UB 1 "Fresh_data" 0 "Unchanged_data" ;
VAL_ 1082 AirSusp_D_RqDrv_UB 1 "Fresh_data" 0 "Unchanged_data" ;
VAL_ 1082 DrvInputRequired_B_Rq_UB 1 "Fresh_data" 0 "Unchanged_data" ;
VAL_ 1082 DrvInputRequired_B_Rq 1 "Yes" 0 "No" ;
VAL_ 1082 SelDrvMdeSwtch_D_Stat2_UB 1 "Fresh_data" 0 "Unchanged_data" ;
VAL_ 1082 SelDrvMdeSwtch_D_Stat2 3 "Faulty" 2 "SwitchState2" 1 "SwitchState1" 0 "NotPressed" ;
VAL_ 1082 FapLcStopHold_B_Rq 1 "Yes" 0 "No" ;
VAL_ 1082 SelDrvMdeDsply_B_Avail 1 "Available" 0 "NotAvailable" ;
VAL_ 1082 FapLcStopHold_B_Rq_UB 1 "Fresh_data" 0 "Unchanged_data" ;
VAL_ 1082 FapLcPrchgBrk_B_Rq_UB 1 "Fresh_data" 0 "Unchanged_data" ;
VAL_ 1082 LnchCtl_N_Rq_UB 1 "Fresh_data" 0 "Unchanged_data" ;
VAL_ 1082 LnchCtl_D_Rq_UB 1 "Fresh_data" 0 "Unchanged_data" ;
VAL_ 1082 LnchCtl_D_Rq 3 "NotUsed2" 2 "NotUsed1" 1 "LC_On" 0 "LC_Off" ;
VAL_ 1082 AirSusp_D_RqDrv 3 "NotUsed" 2 "On" 1 "Off" 0 "NoModeSelected" ;
VAL_ 1082 AwdRnge_D_ActlIpc_UB 1 "Fresh_data" 0 "Unchanged_data" ;
VAL_ 1082 AwdRnge_D_ActlIpc 7 "Unknown" 6 "High_Range_2wd" 5 "High_Range_Auto" 4 "High_Range_Locked" 3 "Neutral" 2 "Low_Range_2wd" 1 "Low_Range_Auto" 0 "Low_Range_Locked" ;
VAL_ 1082 NtrlTowMdeEnbl_B_RqDrv_UB 1 "Fresh_data" 0 "Unchanged_data" ;
VAL_ 1082 NtrlTowMdeEnbl_B_RqDrv 1 "Yes" 0 "No" ;
VAL_ 1082 DrvSlipCtlMde_B_RqMyKey_UB 1 "Fresh_data" 0 "Unchanged_data" ;
VAL_ 1082 DrvSlipCtlMde_B_RqMyKey 1 "On" 0 "Off" ;
VAL_ 1082 AwdDrvMde_D_Rq_UB 1 "Fresh_data" 0 "Unchanged_data" ;
VAL_ 1082 AwdDrvMde_D_Rq 7 "Faulty" 6 "NotAvailable" 5 "RockCrawl" 4 "Baja" 3 "MudAndSand" 2 "Weather" 1 "Sport" 0 "Normal" ;
VAL_ 1082 MetricActv_B_Actl_UB 1 "Fresh_data" 0 "Unchanged_data" ;
VAL_ 1082 MetricActv_B_Actl 1 "Active" 0 "Inactive" ;
VAL_ 1082 BrkLineLck_D_Rq_UB 1 "Fresh_data" 0 "Unchanged_data" ;
VAL_ 1082 BrkLineLck_D_Rq 3 "Off" 2 "Engage" 1 "Initiate" 0 "NoRequest" ;
VAL_ 1082 SuspDrvMde_D_Rq_UB 1 "Fresh_data" 0 "Unchanged_data" ;
VAL_ 1082 SuspDrvMde_D_Rq 7 "Faulty" 6 "NotUsed2" 5 "NotUsed1" 4 "Drag" 3 "Track" 2 "Snow_Wet" 1 "Sport" 0 "Normal" ;
VAL_ 1082 SelDrvMdePt_D_Stat_UB 1 "Fresh_data" 0 "Unchanged_data" ;
VAL_ 1082 SelDrvMdePt_D_Stat 0 "NotAvailable" 1 "Available" 2 "TemporarilyNotAvailable" 3 "Faulty" ;
VAL_ 92 TrnGearMsgTxt2_D_Rq 31 "Message31" 30 "Message30" 29 "Message29" 28 "Message28" 27 "Message27" 26 "Message26" 25 "Message25" 24 "Message24" 23 "Message23" 22 "Message22" 21 "Message21" 20 "Message20" 19 "Message19" 18 "Message18" 17 "Message17" 16 "Message16" 15 "Message15" 14 "Message14" 13 "Message13" 12 "Message12" 11 "Message11" 10 "Message10" 9 "Message9" 8 "Message8" 7 "Message7" 6 "Message6" 5 "Message5" 4 "Message4" 3 "Message3" 2 "Message2" 1 "Message1" 0 "NoMessage" ;
VAL_ 92 RaceTrakMde_D_Stat 3 "NotUsed" 2 "Available" 1 "NotAvailable" 0 "Null" ;
VAL_ 92 TrnLvrV_D_Rq 3 "Full_Speed" 2 "Aggressive" 1 "Normal" 0 "Quiet" ;
VAL_ 92 TrnSbwSysHlth_D_Actl 3 "OK" 2 "Degraded" 1 "No_Data_Exists" 0 "Faulty" ;
VAL_ 92 TrnDtpCmd_D_Actl 7 "NotUsed4" 6 "NotUsed3" 5 "NotUsed2" 4 "Relatch" 3 "Deploy" 2 "Self_Test" 1 "No_Command" 0 "NotUsed1" ;
VAL_ 92 TrnGearNtmAllow_B_Stat 1 "Yes" 0 "No" ;
VAL_ 92 GearSelLck_D_Rq 3 "PreventionBlocker" 2 "Unlock" 1 "Lock" 0 "Null" ;
VAL_ 92 TrnValidGear_D_Cnfm 3 "Accept" 2 "Reject" 1 "Internal_Request" 0 "No_Command" ;
VAL_ 92 TrnNtrlTowCmd_D_Actl 3 "NotUsed" 2 "Neutral_Tow_Entry" 1 "Car_Wash_Mode" 0 "Normal_Mode" ;
VAL_ 92 TrnGearCmd_Pc_ActlPt 1023 "Fault" ;
VAL_ 92 TrnGear_D_RqPt 7 "Fault" 6 "NotUsed" 5 "Manual" 4 "Drive" 3 "Neutral" 2 "Reverse" 1 "Park" 0 "No_Gear" ;
VAL_ 92 TrnCmdState_B_Actl 1 "Yes" 0 "No" ;
VAL_ 92 PrkBrkActv_D_RqTrnGear 3 "NotUsed2" 2 "RequestParkBrakeEngage" 1 "NoRequest" 0 "NotUsed1" ;
VAL_ 92 TrnGearMsgTxt_D_Rq 15 "Message_15" 14 "Message_14" 13 "Message_13" 12 "Message_12" 11 "Message_11" 10 "Message_10" 9 "Message_9" 8 "Message_8" 7 "Message_7" 6 "Message_6" 5 "Message_5" 4 "Message_4" 3 "Message_3" 2 "Message_2" 1 "Message_1" 0 "NoMessage" ;
VAL_ 360 GsmSrvcRqd_B_Rq 1 "Yes" 0 "No" ;
VAL_ 360 TrnTrcmPwmSig_D_Actl 15 "Faulty" 14 "NoDataExists" 13 "NotUsed5" 12 "NotUsed4" 11 "NotUsed3" 10 "NotUsed2" 9 "NotUsed1" 8 "Default_To_Park" 7 "Neutral_Tow" 6 "Car_Wash_Mode" 5 "Manual" 4 "Drive" 3 "Neutral" 2 "Reverse" 1 "Park" 0 "No_Gear" ;
VAL_ 360 TrnGearPwmFalt_B_Actl 1 "Yes" 0 "No" ;
VAL_ 360 GearButtnStuck_B_Actl 1 "Yes" 0 "No" ;
VAL_ 90 TrnGsmNtmState_D_Actl 3 "Faulty" 2 "Neutral_Tow_Mode" 1 "Car_Wash_Mode" 0 "None" ;
VAL_ 90 DrQltyDrv_D_StatGsm 7 "Faulty" 6 "NoDataExists" 5 "NotUsed2" 4 "NotUsed1" 3 "ClosedDegraded" 2 "OpenDegraded" 1 "ClosedOkay" 0 "OpenOkay" ;
VAL_ 90 TrnBtsiOvrrd_B_Stat 1 "Override" 0 "Null" ;
VAL_ 90 GsmGearMsgTxt_D_Rq 3 "Message3" 2 "Message2" 1 "Message1" 0 "NoMessage" ;
VAL_ 90 TrnRng_D_RqGsm 15 "Fault" 14 "UnknownPosition" 13 "Undefined_2" 12 "Undefined_1" 11 "_6" 10 "_5" 9 "_4" 8 "_3" 7 "_2" 6 "_1" 5 "Low" 4 "Sport_DriveSport" 3 "Drive" 2 "Neutral" 1 "Reverse" 0 "Park" ;
VAL_ 90 PrkBrkActv_D_RqGsmGear 3 "NotUsed" 2 "RequestParkBrakeEngage" 1 "NoRequest" 0 "Null" ;
VAL_ 90 TrnValidGearRq_D_Stat 3 "Valid_Request" 2 "Valid_Degraded_Request" 1 "Invalid_Request" 0 "No_Request" ;
VAL_ 90 TrnGearButtn_U_Actl 255 "Fault" ;
VAL_ 90 TrnGearButtn_B_ActlR2 1 "Yes" 0 "No" ;
VAL_ 90 TrnGearButtn_B_ActlR1 1 "Yes" 0 "No" ;
VAL_ 90 TrnGearButtn_B_ActlR0 1 "Yes" 0 "No" ;
VAL_ 90 TrnGearButtn_B_ActlP2 1 "Yes" 0 "No" ;
VAL_ 90 TrnGearButtn_B_ActlP1 1 "Yes" 0 "No" ;
VAL_ 90 TrnGearButtn_B_ActlP0 1 "Yes" 0 "No" ;
VAL_ 90 TrnGearButtn_B_ActlN2 1 "Yes" 0 "No" ;
VAL_ 90 TrnGearButtn_B_ActlN1 1 "Yes" 0 "No" ;
VAL_ 90 TrnGearButtn_B_ActlN0 1 "Yes" 0 "No" ;
VAL_ 90 TrnGearButtn_B_ActlM2 1 "Yes" 0 "No" ;
VAL_ 90 TrnGearButtn_B_ActlM1 1 "Yes" 0 "No" ;
VAL_ 90 TrnGearButtn_B_ActlM0 1 "Yes" 0 "No" ;
VAL_ 90 TrnGearButtn_B_ActlD2 1 "Yes" 0 "No" ;
VAL_ 90 TrnGearButtn_B_ActlD1 1 "Yes" 0 "No" ;
VAL_ 90 TrnGearButtn_B_ActlD0 1 "Yes" 0 "No" ;
VAL_ 90 TrnGear_D_RqDrv 31 "Fault" 30 "NotUsed_25" 29 "NotUsed_24" 28 "NotUsed_23" 27 "NotUsed_22" 26 "NotUsed_21" 25 "NotUsed_20" 24 "NotUsed_19" 23 "NotUsed_18" 22 "NotUsed_17" 21 "Return_To_Park" 20 "NotUsed_15" 19 "NotUsed_14" 18 "NotUsed_13" 17 "NotUsed_12" 16 "Manual" 15 "Not_Used11" 14 "Not_Used10" 13 "NotUsed_9" 12 "NotUsed_8" 11 "NotUsed_7" 10 "NotUsed_6" 9 "NotUsed_5" 8 "Drive" 7 "NotUsed_4" 6 "NotUsed_3" 5 "NotUsed_2" 4 "Neutral" 3 "NotUsed_1" 2 "Reverse" 1 "Park" 0 "No_Gear" ;
VAL_ 90 BrkSwtchPos_B_ActlGsm 1 "Yes" 0 "No" ;
VAL_ 512 PtDrvMde_D_Stat 15 "Faulty" 14 "NotUsed11" 13 "NotUsed10" 12 "NotUsed9" 11 "NotUsed8" 10 "NotUsed7" 9 "NotUsed6" 8 "Track" 7 "Drag" 6 "Rock" 5 "Baja" 4 "Sand" 3 "TowHaulGradeAssist" 2 "SnowWet" 1 "Sport" 0 "Normal" ;
VAL_ 76 RstrnPsngrOn_D_Stat 15 "Faulty" 14 "NotUsed_11" 13 "NotUsed_10" 12 "ConfiguredOff" 11 "NotUsed_9" 10 "On" 9 "NotUsed_8" 8 "NotUsed_7" 7 "NotUsed_6" 6 "NotUsed_5" 5 "Off" 4 "NotUsed_4" 3 "NotUsed_3" 2 "NotUsed_2" 1 "NotUsed_1" 0 "NoAction" ;
VAL_ 76 SecondRowBucklePsngr 3 "Unknown" 2 "Unbelted" 1 "Belted" 0 "Faulty" ;
VAL_ 76 SecondRowBuckleMid 3 "Unknown" 2 "Unbelted" 1 "Belted" 0 "Faulty" ;
VAL_ 76 SecondRowBuckleDriver 3 "Unknown" 2 "Unbelted" 1 "Belted" 0 "Faulty" ;
VAL_ 76 FirstRowBuckleDriver 3 "Unknown" 2 "Unbelted" 1 "Belted" 0 "Faulty" ;
VAL_ 76 RILReq 3 "Not_Used" 2 "Plant_Mode" 1 "On" 0 "Off" ;
VAL_ 76 FirstRowBucklePsngr 3 "Unknown" 2 "Unbelted" 1 "Belted" 0 "Faulty" ;
VAL_ 76 RstrnImpactEvntStatus 7 "Invalid" 6 "Not_Used_4" 5 "Threshold_2_Exceeded" 4 "Not_Used_3" 3 "Threshold_1_Exceeded" 2 "Not_Used_2" 1 "Not_Used_1" 0 "Normal" ;
VAL_ 76 PsngrFrntDetct_D_Actl 3 "Unknown" 2 "Empty" 0 "Faulty" 1 "Occupied" ;
VAL_ 76 EDRTriggerEvntSync 1 "Threshold_Exceeded" 0 "Normal" ;
VAL_ 120 BpedDrvMsgTxt_B_Dsply_UB 1 "Fresh_data" 0 "Unchanged_data" ;
VAL_ 120 BpedDrvMsgTxt_B_Dsply 1 "On" 0 "Off" ;
VAL_ 120 PassRstrnInd_Stat_UB 1 "Fresh_data" 0 "Unchanged_data" ;
VAL_ 120 PassRstrnInd_Stat 7 "Invalid" 6 "Unused_2" 5 "Unused_1" 4 "Both_Indicators_Faulted" 3 "AirbagOff_Indicator_fault" 2 "AirbagOn_Indicator_fault" 1 "Normal" 0 "Not_Supported" ;
VAL_ 120 HtrnWarnLamp_B_Dsply_UB 1 "Fresh_data" 0 "Unchanged_data" ;
VAL_ 120 HtrnWarnLamp_B_Dsply 1 "On" 0 "Off" ;
VAL_ 120 ECMMILRequest_UB 1 "Fresh_data" 0 "Unchanged_data" ;
VAL_ 120 ECMMILRequest 3 "Not_Used" 2 "Flash" 1 "On" 0 "Off" ;
VAL_ 120 TrnIpcDsplyMde_D_Stat 3 "Reserved_Blank_No_Display" 2 "Flash" 1 "On" 0 "Blank_No_Display" ;
VAL_ 120 TrnIpcDsplyMde_D_Actl 7 "Manual_3" 6 "Manual_2" 5 "Manual_1_Low" 4 "Sport" 3 "Drive" 2 "Neutral" 1 "Reverse" 0 "Park" ;
VAL_ 120 EngSrvcRqd_B_Rq_UB 1 "Fresh_data" 0 "Unchanged_data" ;
VAL_ 120 EngSrvcRqd_B_Rq 1 "Engine_Service_Required" 0 "No_engine_service_required" ;
VAL_ 120 HtrnSrvcRqd_B_Dsply 1 "On" 0 "Off" ;
VAL_ 120 HtrnSrvcRqd_B_Dsply_UB 1 "Fresh_data" 0 "Unchanged_data" ;
VAL_ 120 TrnIpcDsplyMde_D_Stat_UB 1 "Fresh_data" 0 "Unchanged_data" ;
VAL_ 120 TrnIpcDsplyMde_D_Actl_UB 1 "Fresh_data" 0 "Unchanged_data" ;
